NS_ :

BS_:

BU_: AWC BAP_Tester BMC_MLBevo BMS_MV BMS_NV DCDC_800V_PAG DCDC_HV DCDC_HV_02 DCDC_IHEV Gateway Gateway_PAG Ladegeraet_2 Ladegeraet_Konzern LE1 LE2 LE_MLBevo Sub_Gateway TME

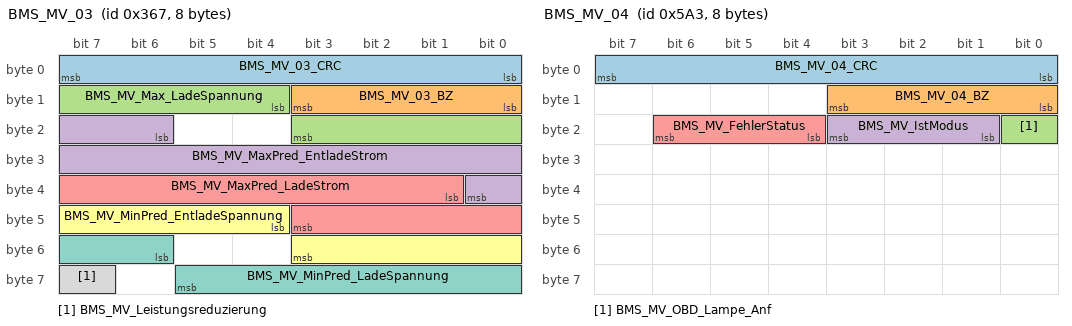
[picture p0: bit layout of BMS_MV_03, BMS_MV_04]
BO_ 871 BMS_MV_03: 8 BMS_MV
 SG_ BMS_MV_03_CRC : 0|8@1+ (1,0) [0|255] ""  Gateway,Gateway_PAG
 SG_ BMS_MV_03_BZ : 8|4@1+ (1,0) [0|15] ""  Gateway,Gateway_PAG
 SG_ BMS_MV_Max_LadeSpannung : 12|8@1+ (0.25,0) [0.00|63.25] "Unit_Volt"  Gateway,Gateway_PAG
 SG_ BMS_MV_MaxPred_EntladeStrom : 22|11@1+ (1,0) [0|2045] "Unit_Amper"  Gateway,Gateway_PAG
 SG_ BMS_MV_MaxPred_LadeStrom : 33|11@1+ (1,0) [0|2045] "Unit_Amper"  Gateway,Gateway_PAG
 SG_ BMS_MV_MinPred_EntladeSpannung : 44|8@1+ (0.25,0) [0.00|63.25] "Unit_Volt"  Gateway,Gateway_PAG
 SG_ BMS_MV_MinPred_LadeSpannung : 54|8@1+ (0.25,0) [0.00|63.25] "Unit_Volt"  Gateway,Gateway_PAG
 SG_ BMS_MV_Leistungsreduzierung : 63|1@1+ (1.0,0.0) [0.0|1] ""  Gateway,Gateway_PAG

BO_ 1443 BMS_MV_04: 8 BMS_MV
 SG_ BMS_MV_04_CRC : 0|8@1+ (1,0) [0|255] ""  Gateway,Gateway_PAG
 SG_ BMS_MV_04_BZ : 8|4@1+ (1,0) [0|15] ""  Gateway,Gateway_PAG
 SG_ BMS_MV_OBD_Lampe_Anf : 16|1@1+ (1.0,0.0) [0.0|1] ""  Gateway,Gateway_PAG
 SG_ BMS_MV_IstModus : 17|3@1+ (1.0,0.0) [0.0|7] ""  DCDC_IHEV,Gateway,Gateway_PAG
 SG_ BMS_MV_FehlerStatus : 20|3@1+ (1.0,0.0) [0.0|7] ""  Gateway,Gateway_PAG

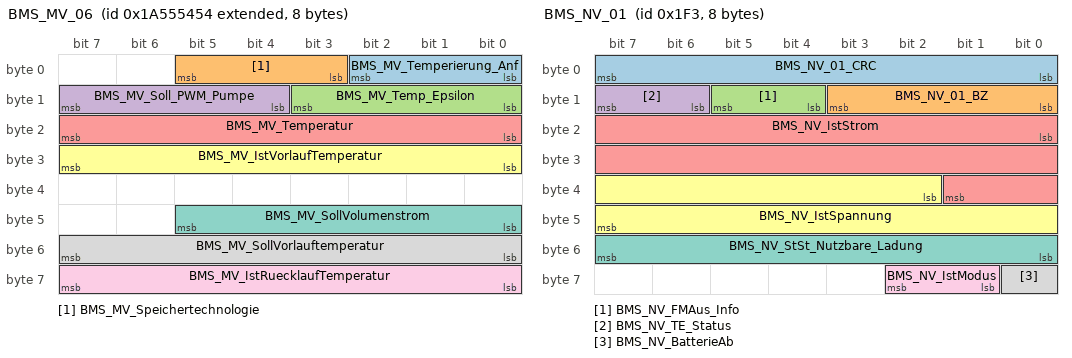
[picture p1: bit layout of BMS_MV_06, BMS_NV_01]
BO_ 2589283412 BMS_MV_06: 8 BMS_MV
 SG_ BMS_MV_Temperierung_Anf : 0|3@1+ (1.0,0.0) [0.0|7] ""  Gateway,Gateway_PAG,TME
 SG_ BMS_MV_Speichertechnologie : 3|3@1+ (1.0,0.0) [0.0|7] ""  Gateway,Gateway_PAG
 SG_ BMS_MV_Temp_Epsilon : 8|4@1+ (1,-15) [-15|0] "Unit_DegreCelsi"  Gateway,Gateway_PAG,TME
 SG_ BMS_MV_Soll_PWM_Pumpe : 12|4@1+ (10,0) [0|100] "Unit_PerCent"  Gateway,Gateway_PAG,TME
 SG_ BMS_MV_Temperatur : 16|8@1+ (0.5,-40) [-40.0|86.5] "Unit_DegreCelsi"  DCDC_IHEV,Gateway,Gateway_PAG,TME
 SG_ BMS_MV_IstVorlaufTemperatur : 24|8@1+ (0.5,-40) [-40.0|86.5] "Unit_DegreCelsi"  Gateway,Gateway_PAG,TME
 SG_ BMS_MV_SollVolumenstrom : 40|6@1+ (1,0) [0|61] ""  Gateway,Gateway_PAG,TME
 SG_ BMS_MV_SollVorlauftemperatur : 48|8@1+ (0.5,-40) [-40.0|86.5] "Unit_DegreCelsi"  Gateway,Gateway_PAG,TME
 SG_ BMS_MV_IstRuecklaufTemperatur : 56|8@1+ (0.5,-40) [-40.0|86.5] "Unit_DegreCelsi"  Gateway,Gateway_PAG,TME

BO_ 2589283608 BMS_MV_07: 8 BMS_MV
 SG_ BMS_MV_Energieinhalt : 12|11@1+ (1,0) [0|2045] "Unit_WattHour"  Gateway,Gateway_PAG
 SG_ BMS_MV_MaxEnergieinhalt : 32|11@1+ (1,0) [0|2045] "Unit_WattHour"  Gateway,Gateway_PAG

BO_ 2589283606 BMS_MV_09: 8 BMS_MV
 SG_ BMS_MV_SOC_Kaltstart : 43|11@1+ (0.05,0) [0.00|100.00] "Unit_PerCent"  Gateway,Gateway_PAG
 SG_ BMS_MV_max_Grenz_SOC : 54|5@1+ (1,70) [70|100] "Unit_PerCent"  Gateway,Gateway_PAG

BO_ 1021 BMS_MV_10: 8 BMS_MV
 SG_ BMS_MV_Pred_Entladeperformance : 50|7@1+ (1,0) [0|100] "Unit_PerCent"  Gateway,Gateway_PAG
 SG_ BMS_MV_Pred_Ladeperformance : 57|7@1+ (1,0) [0|100] "Unit_PerCent"  Gateway,Gateway_PAG

BO_ 499 BMS_NV_01: 8 BMS_NV
 SG_ BMS_NV_01_CRC : 0|8@1+ (1,0) [0|255] ""  Gateway,Gateway_PAG
 SG_ BMS_NV_01_BZ : 8|4@1+ (1,0) [0|15] ""  Gateway,Gateway_PAG
 SG_ BMS_NV_FMAus_Info : 12|2@1+ (1.0,0.0) [0.0|3] ""  Gateway,Gateway_PAG
 SG_ BMS_NV_TE_Status : 14|2@1+ (1.0,0.0) [0.0|3] ""  Gateway,Gateway_PAG
 SG_ BMS_NV_IstStrom : 16|18@1+ (0.01,-1300) [-1300.00|1300.00] "Unit_Amper"  Gateway,Gateway_PAG
 SG_ BMS_NV_IstSpannung : 34|14@1+ (0.001,4) [4.000|20.381] "Unit_Volt"  Gateway,Gateway_PAG
 SG_ BMS_NV_StSt_Nutzbare_Ladung : 48|8@1+ (50,0) [0|12650] "Unit_AmperSecon"  Gateway,Gateway_PAG
 SG_ BMS_NV_BatterieAb : 56|1@1+ (1.0,0.0) [0.0|1] ""  Gateway,Gateway_PAG
 SG_ BMS_NV_IstModus : 57|2@1+ (1.0,0.0) [0.0|3] ""  Gateway,Gateway_PAG

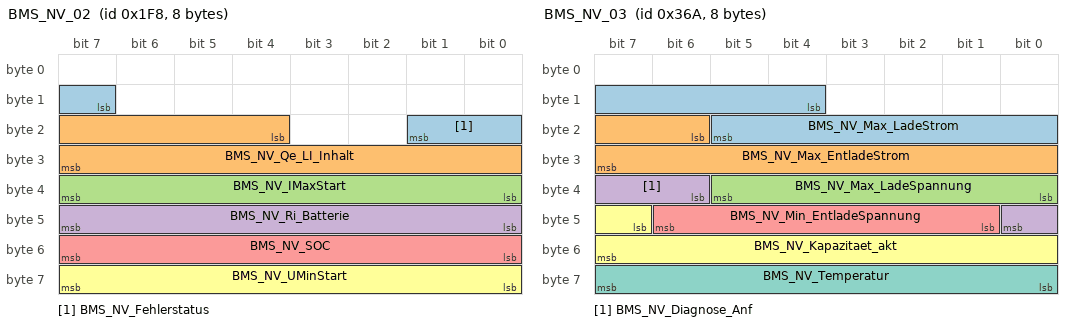
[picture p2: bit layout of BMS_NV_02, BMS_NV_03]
BO_ 504 BMS_NV_02: 8 BMS_NV
 SG_ BMS_NV_Fehlerstatus : 15|3@1+ (1.0,0.0) [0.0|7] ""  Gateway,Gateway_PAG
 SG_ BMS_NV_Qe_LI_Inhalt : 20|12@1+ (0.01,0) [0.00|40.00] "Unit_AmperHour"  Gateway,Gateway_PAG
 SG_ BMS_NV_IMaxStart : 32|8@1+ (4,1) [1|1013] "Unit_Amper"  Gateway,Gateway_PAG
 SG_ BMS_NV_Ri_Batterie : 40|8@1+ (0.2,0) [0.0|50.6] "Unit_MilliOhm"  Gateway,Gateway_PAG
 SG_ BMS_NV_SOC : 48|8@1+ (0.4,0) [0.0|100.0] "Unit_PerCent"  Gateway,Gateway_PAG
 SG_ BMS_NV_UMinStart : 56|8@1+ (0.05,2) [2.00|14.65] "Unit_Volt"  Gateway,Gateway_PAG

BO_ 874 BMS_NV_03: 8 BMS_NV
 SG_ BMS_NV_Max_LadeStrom : 12|10@1+ (1,0) [0|850] "Unit_Amper"  Gateway,Gateway_PAG
 SG_ BMS_NV_Max_EntladeStrom : 22|10@1+ (1,0) [0|850] "Unit_Amper"  Gateway,Gateway_PAG
 SG_ BMS_NV_Max_LadeSpannung : 32|6@1+ (0.1,11) [11.0|17.1] "Unit_Volt"  Gateway,Gateway_PAG
 SG_ BMS_NV_Diagnose_Anf : 38|3@1+ (1.0,0.0) [0.0|7] ""  Gateway,Gateway_PAG
 SG_ BMS_NV_Min_EntladeSpannung : 41|6@1+ (0.1,8) [8.0|14.1] "Unit_Volt"  Gateway,Gateway_PAG
 SG_ BMS_NV_Kapazitaet_akt : 47|9@1+ (0.1,0) [0.0|40.0] "Unit_AmperHour"  Gateway,Gateway_PAG
 SG_ BMS_NV_Temperatur : 56|8@1+ (1,-55) [-55|127] "Unit_DegreCelsi"  Gateway,Gateway_PAG

BO_ 2463978664 BMS_NV_04: 8 BMS_NV
 SG_ BMS_NV_Polspannung : 55|9@1+ (0.01,10.5) [10.50|15.59] "Unit_Volt"  Gateway,Gateway_PAG

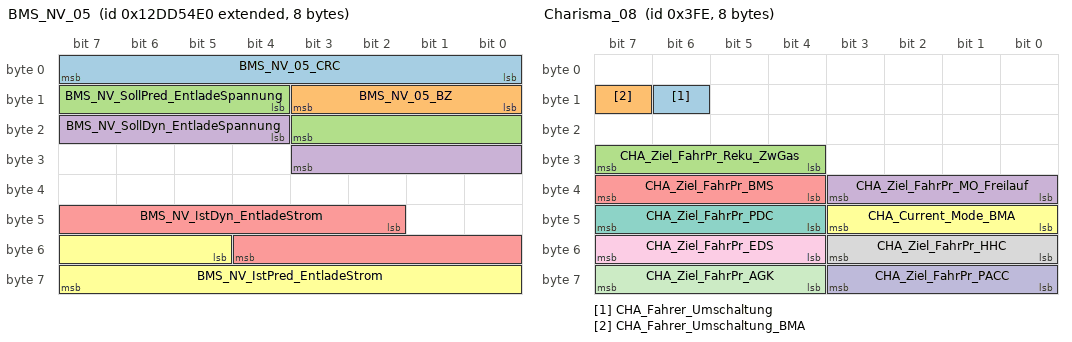
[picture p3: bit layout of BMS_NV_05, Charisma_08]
BO_ 2463978720 BMS_NV_05: 8 BMS_NV
 SG_ BMS_NV_05_CRC : 0|8@1+ (1,0) [0|255] ""  Gateway,Gateway_PAG
 SG_ BMS_NV_05_BZ : 8|4@1+ (1,0) [0|15] ""  Gateway,Gateway_PAG
 SG_ BMS_NV_SollPred_EntladeSpannung : 12|8@1+ (0.05,4) [4.00|16.65] "Unit_Volt"  Gateway,Gateway_PAG
 SG_ BMS_NV_SollDyn_EntladeSpannung : 20|8@1+ (0.05,4) [4.00|16.65] "Unit_Volt"  Gateway,Gateway_PAG
 SG_ BMS_NV_IstDyn_EntladeStrom : 42|11@1+ (1,0) [0|2045] "Unit_Amper"  Gateway,Gateway_PAG
 SG_ BMS_NV_IstPred_EntladeStrom : 53|11@1+ (1,0) [0|2045] "Unit_Amper"  Gateway,Gateway_PAG

BO_ 2617236992 CCP_BMS_CRO_01: 8 Vector__XXX
 SG_ CCP_BMS_CRO_01_Data : 0|64@1+ (1,0) [0|1] ""  BMC_MLBevo

BO_ 2617236993 CCP_BMS_DTO_01: 8 BMC_MLBevo
 SG_ CCP_BMS_DTO_01_Data : 0|64@1+ (1,0) [0|1] ""  Vector__XXX

BO_ 2617130752 CCP_DCDC_HV_02_CRO_01: 8 Vector__XXX
 SG_ CCP_DCDC_HV_02_CRO_01_Data : 0|64@1+ (1.0,0.0) [0.0|18446744073709551615] ""  DCDC_HV_02

BO_ 2617130753 CCP_DCDC_HV_02_DTO_01: 8 DCDC_HV_02
 SG_ CCP_DCDC_HV_02_DTO_01_Data : 0|64@1+ (1.0,0.0) [0.0|18446744073709551615] ""  Vector__XXX

BO_ 2617194240 CCP_Ladegeraet_2_CRO_01: 8 Vector__XXX
 SG_ CCP_Ladegeraet_2_CRO_01_Data : 0|64@1+ (1.0,0.0) [0.0|18446744073709551615] ""  Ladegeraet_2

BO_ 2617194241 CCP_Ladegeraet_2_DTO_01: 8 Ladegeraet_2
 SG_ CCP_Ladegeraet_2_DTO_01_Data : 0|64@1+ (1.0,0.0) [0.0|18446744073709551615] ""  Vector__XXX

BO_ 2617124352 CCP_Ladegeraet_CRO_01: 8 Vector__XXX
 SG_ CCP_Ladegeraet_CRO_01_Data : 0|64@1+ (1.0,0.0) [0.0|18446744073709551615] ""  Ladegeraet_Konzern

BO_ 2617124353 CCP_Ladegeraet_DTO_01: 8 Ladegeraet_Konzern
 SG_ CCP_Ladegeraet_DTO_01_Data : 0|64@1+ (1.0,0.0) [0.0|18446744073709551615] ""  Vector__XXX

BO_ 901 Charisma_01: 8 Gateway
 SG_ CHA_Ziel_FahrPr_AGA : 0|4@1+ (1.0,0.0) [0.0|15] ""  Vector__XXX
 SG_ CHA_Ziel_FahrPr_ESP : 4|4@1+ (1.0,0.0) [0.0|15] ""  Vector__XXX
 SG_ CHA_Ziel_FahrPr_Freilauf : 8|4@1+ (1.0,0.0) [0.0|15] ""  Vector__XXX
 SG_ CHA_Fahrer_Umschaltung : 14|1@1+ (1.0,0.0) [0.0|1] ""  Vector__XXX
 SG_ CHA_Fahrer_Umschaltung_BMA : 15|1@1+ (1.0,0.0) [0.0|1] ""  Vector__XXX
 SG_ CHA_Ziel_FahrPr_MO : 16|4@1+ (1.0,0.0) [0.0|15] ""  Vector__XXX
 SG_ CHA_Ziel_FahrPr_GE : 20|4@1+ (1.0,0.0) [0.0|15] ""  Vector__XXX
 SG_ CHA_Ziel_FahrPr_ALR : 24|4@1+ (1.0,0.0) [0.0|15] ""  Vector__XXX
 SG_ CHA_Ziel_FahrPr_MO_BZS : 28|4@1+ (1.0,0.0) [0.0|15] ""  TME
 SG_ CHA_Ziel_FahrPr_DR : 32|4@1+ (1.0,0.0) [0.0|15] ""  Vector__XXX
 SG_ CHA_Ziel_FahrPr_VAQ : 36|4@1+ (1.0,0.0) [0.0|15] ""  Vector__XXX
 SG_ CHA_Ziel_FahrPr_AFS : 40|4@1+ (1.0,0.0) [0.0|15] ""  Vector__XXX
 SG_ CHA_Ziel_FahrPr_PreCrash : 44|4@1+ (1.0,0.0) [0.0|15] ""  Vector__XXX
 SG_ CHA_Ziel_FahrPr_EPS : 48|4@1+ (1.0,0.0) [0.0|15] ""  Vector__XXX
 SG_ CHA_Ziel_FahrPr_ACC : 52|4@1+ (1.0,0.0) [0.0|15] ""  Vector__XXX
 SG_ CHA_Ziel_FahrPr_SAK : 56|4@1+ (1.0,0.0) [0.0|15] ""  Vector__XXX
 SG_ CHA_Ziel_FahrPr_MO_StSt : 60|4@1+ (1.0,0.0) [0.0|15] ""  Vector__XXX

BO_ 1022 Charisma_08: 8 Gateway
 SG_ CHA_Fahrer_Umschaltung : 14|1@1+ (1.0,0.0) [0.0|1] ""  Vector__XXX
 SG_ CHA_Fahrer_Umschaltung_BMA : 15|1@1+ (1.0,0.0) [0.0|1] ""  Vector__XXX
 SG_ CHA_Ziel_FahrPr_Reku_ZwGas : 28|4@1+ (1.0,0.0) [0.0|15] ""  Vector__XXX
 SG_ CHA_Ziel_FahrPr_MO_Freilauf : 32|4@1+ (1.0,0.0) [0.0|15] ""  Vector__XXX
 SG_ CHA_Ziel_FahrPr_BMS : 36|4@1+ (1.0,0.0) [0.0|15] ""  BMC_MLBevo
 SG_ CHA_Current_Mode_BMA : 40|4@1+ (1.0,0.0) [0.0|15] ""  Vector__XXX
 SG_ CHA_Ziel_FahrPr_PDC : 44|4@1+ (1.0,0.0) [0.0|15] ""  Vector__XXX
 SG_ CHA_Ziel_FahrPr_HHC : 48|4@1+ (1.0,0.0) [0.0|15] ""  Vector__XXX
 SG_ CHA_Ziel_FahrPr_EDS : 52|4@1+ (1.0,0.0) [0.0|15] ""  Vector__XXX
 SG_ CHA_Ziel_FahrPr_PACC : 56|4@1+ (1.0,0.0) [0.0|15] ""  Vector__XXX
 SG_ CHA_Ziel_FahrPr_AGK : 60|4@1+ (1.0,0.0) [0.0|15] ""  Vector__XXX

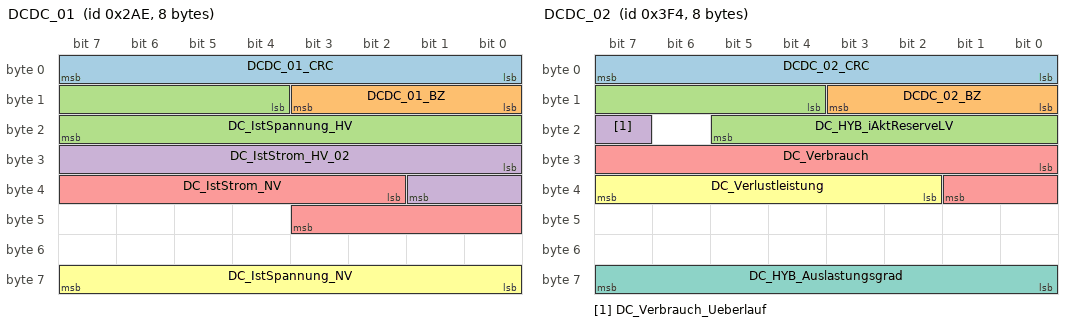
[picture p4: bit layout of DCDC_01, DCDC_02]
BO_ 686 DCDC_01: 8 DCDC_800V_PAG
 SG_ DCDC_01_CRC : 0|8@1+ (1,0) [0|255] ""  Gateway,Gateway_PAG
 SG_ DCDC_01_BZ : 8|4@1+ (1,0) [0|15] ""  Gateway,Gateway_PAG
 SG_ DC_IstSpannung_HV : 12|12@1+ (0.25,0) [0.00|1023.25] "Unit_Volt"  BMC_MLBevo,DCDC_HV_02,Gateway,Gateway_PAG,TME
 SG_ DC_IstStrom_HV_02 : 24|10@1+ (0.4,-204) [-204.0|204.0] "Unit_Amper"  DCDC_HV_02,Gateway,Gateway_PAG,Ladegeraet_Konzern,TME
 SG_ DC_IstStrom_NV : 34|10@1+ (1,-511) [-511|510] "Unit_Amper"  Gateway,Gateway_PAG
 SG_ DC_IstSpannung_NV : 56|8@1+ (0.1,0) [0.0|25.3] "Unit_Volt"  AWC,Gateway,Gateway_PAG,Ladegeraet_2,Ladegeraet_Konzern

BO_ 1012 DCDC_02: 8 DCDC_800V_PAG
 SG_ DCDC_02_CRC : 0|8@1+ (1,0) [0|255] ""  Gateway,Gateway_PAG
 SG_ DCDC_02_BZ : 8|4@1+ (1,0) [0|15] ""  Gateway,Gateway_PAG
 SG_ DC_HYB_iAktReserveLV : 12|10@1+ (1,-511) [-511|510] "Unit_Amper"  Gateway,Gateway_PAG
 SG_ DC_Verbrauch_Ueberlauf : 23|1@1+ (1.0,0.0) [0.0|1] ""  Gateway,Gateway_PAG
 SG_ DC_Verbrauch : 24|10@1+ (1,0) [0|1023] "Unit_WattSecond"  Gateway,Gateway_PAG
 SG_ DC_Verlustleistung : 34|6@1+ (5,0) [0|305] "Unit_Watt"  Gateway,Gateway_PAG,TME
 SG_ DC_HYB_Auslastungsgrad : 56|8@1+ (0.4,0) [0.0|100.0] "Unit_PerCent"  Gateway,Gateway_PAG,TME

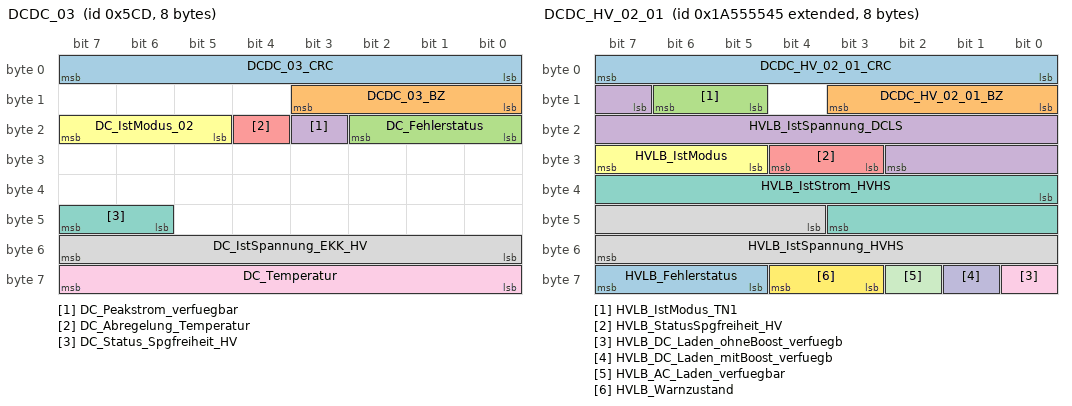
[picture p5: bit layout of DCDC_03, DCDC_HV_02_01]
BO_ 1485 DCDC_03: 8 DCDC_800V_PAG
 SG_ DCDC_03_CRC : 0|8@1+ (1,0) [0|255] ""  Gateway,Gateway_PAG
 SG_ DCDC_03_BZ : 8|4@1+ (1,0) [0|15] ""  Gateway,Gateway_PAG
 SG_ DC_Fehlerstatus : 16|3@1+ (1.0,0.0) [0.0|7] ""  Gateway,Gateway_PAG
 SG_ DC_Peakstrom_verfuegbar : 19|1@1+ (1.0,0.0) [0.0|1] ""  Gateway,Gateway_PAG
 SG_ DC_Abregelung_Temperatur : 20|1@1+ (1.0,0.0) [0.0|1] ""  TME
 SG_ DC_IstModus_02 : 21|3@1+ (1.0,0.0) [0.0|7] ""  DCDC_HV_02,Gateway,Gateway_PAG,Ladegeraet_Konzern,TME
 SG_ DC_Status_Spgfreiheit_HV : 46|2@1+ (1.0,0.0) [0.0|3] ""  Gateway
 SG_ DC_IstSpannung_EKK_HV : 48|8@1+ (2,0) [0|508] "Unit_Volt"  Gateway
 SG_ DC_Temperatur : 56|8@1+ (1,-40) [-40|213] "Unit_DegreCelsi"  Gateway,Gateway_PAG,TME

BO_ 2589283653 DCDC_HV_02_01: 8 DCDC_HV_02
 SG_ DCDC_HV_02_01_CRC : 0|8@1+ (1,0) [0|255] ""  Gateway,Gateway_PAG,Ladegeraet_Konzern
 SG_ DCDC_HV_02_01_BZ : 8|4@1+ (1,0) [0|15] ""  Gateway,Gateway_PAG,Ladegeraet_Konzern
 SG_ HVLB_IstModus_TN1 : 13|2@1+ (1.0,0.0) [0.0|3] ""  Gateway,Gateway_PAG
 SG_ HVLB_IstSpannung_DCLS : 15|12@1+ (0.25,0) [0.00|1023.25] "Unit_Volt"  Ladegeraet_Konzern
 SG_ HVLB_StatusSpgfreiheit_HV : 27|2@1+ (1.0,0.0) [0.0|3] ""  Gateway,Gateway_PAG
 SG_ HVLB_IstModus : 29|3@1+ (1.0,0.0) [0.0|7] ""  Ladegeraet_Konzern,TME
 SG_ HVLB_IstStrom_HVHS : 32|12@1+ (0.25,-512) [-512.00|511.25] "Unit_Amper"  Ladegeraet_Konzern
 SG_ HVLB_IstSpannung_HVHS : 44|12@1+ (0.25,0) [0.00|1023.25] "Unit_Volt"  Gateway,Gateway_PAG,Ladegeraet_Konzern
 SG_ HVLB_DC_Laden_ohneBoost_verfuegb : 56|1@1+ (1.0,0.0) [0.0|1] ""  Ladegeraet_Konzern
 SG_ HVLB_DC_Laden_mitBoost_verfuegb : 57|1@1+ (1.0,0.0) [0.0|1] ""  Ladegeraet_Konzern
 SG_ HVLB_AC_Laden_verfuegbar : 58|1@1+ (1.0,0.0) [0.0|1] ""  Ladegeraet_Konzern
 SG_ HVLB_Warnzustand : 59|2@1+ (1.0,0.0) [0.0|3] ""  Ladegeraet_Konzern
 SG_ HVLB_Fehlerstatus : 61|3@1+ (1.0,0.0) [0.0|7] ""  Gateway,Gateway_PAG,Ladegeraet_Konzern

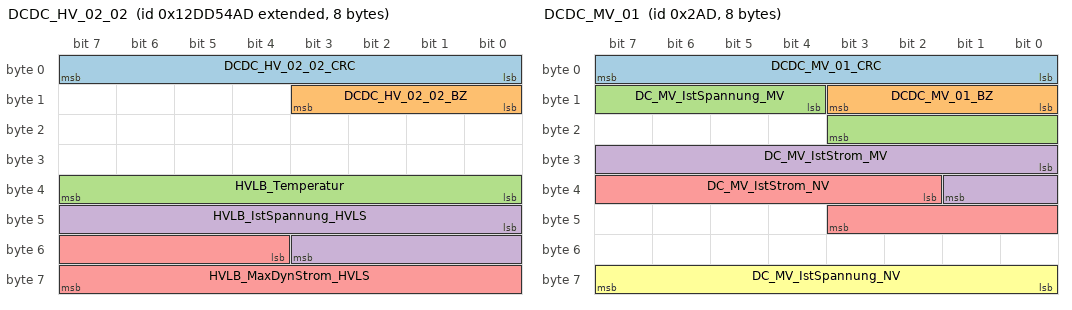
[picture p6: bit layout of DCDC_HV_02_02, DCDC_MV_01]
BO_ 2463978669 DCDC_HV_02_02: 8 DCDC_HV_02
 SG_ DCDC_HV_02_02_CRC : 0|8@1+ (1,0) [0|255] ""  Ladegeraet_Konzern
 SG_ DCDC_HV_02_02_BZ : 8|4@1+ (1,0) [0|15] ""  Ladegeraet_Konzern
 SG_ HVLB_Temperatur : 32|8@1+ (1,-40) [-40|213] "Unit_DegreCelsi"  TME
 SG_ HVLB_IstSpannung_HVLS : 40|12@1+ (0.25,0) [0.00|1023.25] "Unit_Volt"  Ladegeraet_Konzern
 SG_ HVLB_MaxDynStrom_HVLS : 52|12@1+ (0.25,-512) [-512.00|511.25] "Unit_Amper"  Ladegeraet_Konzern

BO_ 2589283662 DCDC_HV_02_03: 8 DCDC_HV_02
 SG_ HVLB_PlanAntw_Verlustleistung : 48|12@1+ (50,0) [0|204650] "Unit_Watt"  Ladegeraet_Konzern,TME
 SG_ HVLB_PlanAntw_Zaehler : 60|4@1+ (1,0) [0|13] "Unit_None"  Ladegeraet_Konzern,TME

BO_ 685 DCDC_MV_01: 8 DCDC_800V_PAG
 SG_ DCDC_MV_01_CRC : 0|8@1+ (1,0) [0|255] ""  Gateway,Gateway_PAG
 SG_ DCDC_MV_01_BZ : 8|4@1+ (1,0) [0|15] ""  Gateway,Gateway_PAG
 SG_ DC_MV_IstSpannung_MV : 12|8@1+ (0.25,0) [0.00|63.25] "Unit_Volt"  Gateway,Gateway_PAG
 SG_ DC_MV_IstStrom_MV : 24|10@1+ (0.4,-204) [-204.0|204.0] "Unit_Amper"  Gateway,Gateway_PAG
 SG_ DC_MV_IstStrom_NV : 34|10@1+ (1,-511) [-511|510] "Unit_Amper"  Gateway,Gateway_PAG
 SG_ DC_MV_IstSpannung_NV : 56|8@1+ (0.1,0) [0.0|25.3] "Unit_Volt"  Gateway,Gateway_PAG

BO_ 1018 DCDC_MV_02: 8 DCDC_800V_PAG
 SG_ DCDC_MV_02_CRC : 0|8@1+ (1,0) [0|255] ""  Gateway,Gateway_PAG
 SG_ DCDC_MV_02_BZ : 8|4@1+ (1,0) [0|15] ""  Gateway,Gateway_PAG
 SG_ DC_MV_akt_Stromreserve_NV : 12|10@1+ (1,-511) [-511|510] "Unit_Amper"  Gateway,Gateway_PAG
 SG_ DC_MV_MaxStrom_MV : 50|6@1+ (2.5,-152.5) [-152.5|0.0] "Unit_Amper"  Gateway,Gateway_PAG
 SG_ DC_MV_Auslastungsgrad : 56|8@1+ (0.4,0) [0.0|100.0] "Unit_PerCent"  Gateway,Gateway_PAG

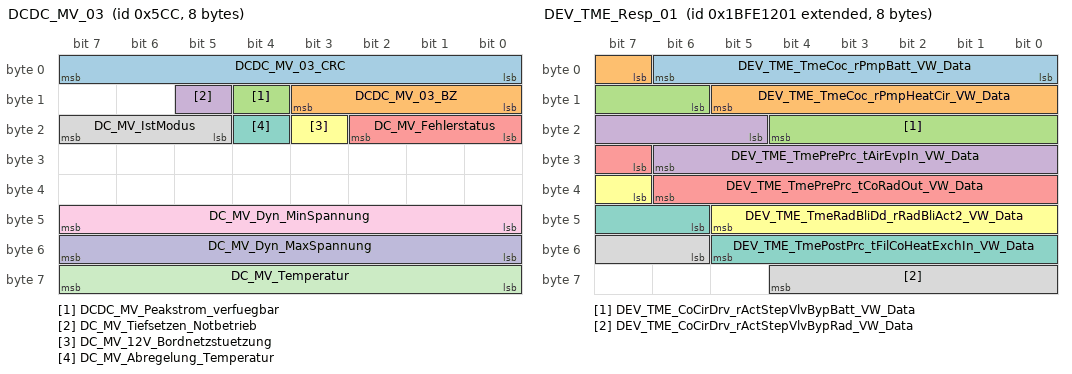
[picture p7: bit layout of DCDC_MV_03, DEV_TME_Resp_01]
BO_ 1484 DCDC_MV_03: 8 DCDC_800V_PAG
 SG_ DCDC_MV_03_CRC : 0|8@1+ (1,0) [0|255] ""  Gateway,Gateway_PAG
 SG_ DCDC_MV_03_BZ : 8|4@1+ (1,0) [0|15] ""  Gateway,Gateway_PAG
 SG_ DCDC_MV_Peakstrom_verfuegbar : 12|1@1+ (1.0,0.0) [0.0|1] ""  Gateway,Gateway_PAG
 SG_ DC_MV_Tiefsetzen_Notbetrieb : 13|1@1+ (1.0,0.0) [0.0|1] ""  Gateway,Gateway_PAG
 SG_ DC_MV_Fehlerstatus : 16|3@1+ (1.0,0.0) [0.0|7] ""  Gateway,Gateway_PAG
 SG_ DC_MV_12V_Bordnetzstuetzung : 19|1@1+ (1.0,0.0) [0.0|1] ""  Gateway,Gateway_PAG
 SG_ DC_MV_Abregelung_Temperatur : 20|1@1+ (1.0,0.0) [0.0|1] ""  TME
 SG_ DC_MV_IstModus : 21|3@1+ (1.0,0.0) [0.0|7] ""  Gateway,Gateway_PAG
 SG_ DC_MV_Dyn_MinSpannung : 40|8@1+ (0.25,0) [0.00|63.25] "Unit_Volt"  Gateway
 SG_ DC_MV_Dyn_MaxSpannung : 48|8@1+ (0.25,0) [0.00|63.25] "Unit_Volt"  Gateway
 SG_ DC_MV_Temperatur : 56|8@1+ (1,-40) [-40|213] "Unit_DegreCelsi"  TME

BO_ 2617015040 DEV_AWC_Resp_00: 8 AWC
 SG_ DEV_AWC_Resp_00_Data : 0|64@1+ (1.0,0.0) [0.0|18446744073709551615] ""  Vector__XXX

BO_ 2617015295 DEV_AWC_Resp_FF: 8 AWC
 SG_ DEV_AWC_Resp_FF_Data : 0|64@1+ (1.0,0.0) [0.0|18446744073709551615] ""  Vector__XXX

BO_ 2617078528 DEV_BattRegelung_Req_00: 8 Vector__XXX
 SG_ DEV_BattRegelung_Req_00_Data : 0|64@1+ (1.0,0.0) [0.0|18446744073709551615] ""  BMS_NV

BO_ 2617078783 DEV_BattRegelung_Resp_FF: 8 BMS_NV
 SG_ DEV_BattRegelung_Resp_FF_Data : 0|64@1+ (1.0,0.0) [0.0|18446744073709551615] ""  Vector__XXX

BO_ 2617041664 DEV_BMS_MV_Resp_00: 8 BMS_MV
 SG_ DEV_BMS_MV_Resp_00_Data : 0|64@1+ (1.0,0.0) [0.0|18446744073709551615] ""  Vector__XXX

BO_ 2617041919 DEV_BMS_MV_Resp_FF: 8 BMS_MV
 SG_ DEV_BMS_MV_Resp_FF_Data : 0|64@1+ (1.0,0.0) [0.0|18446744073709551615] ""  Vector__XXX

BO_ 2617235968 DEV_BMS_Resp_00: 8 BMC_MLBevo
 SG_ DEV_BMS_Resp_00_Data : 0|64@1+ (1.0,0.0) [0.0|18446744073709551615] ""  Vector__XXX

BO_ 2617236223 DEV_BMS_Resp_FF: 8 BMC_MLBevo
 SG_ DEV_BMS_Resp_FF_Data : 0|64@1+ (1.0,0.0) [0.0|18446744073709551615] ""  Vector__XXX

BO_ 2617129728 DEV_DCDC_HV_02_Req_01: 8 Vector__XXX
 SG_ DEV_DCDC_HV_02_Req_01_Data : 0|64@1+ (1.0,0.0) [0.0|18446744073709551615] ""  DCDC_HV_02

BO_ 2617129729 DEV_DCDC_HV_02_Resp_01: 8 DCDC_HV_02
 SG_ DEV_DCDC_HV_02_Resp_01_Data : 0|64@1+ (1.0,0.0) [0.0|18446744073709551615] ""  Vector__XXX

BO_ 2617129983 DEV_DCDC_HV_02_Resp_FF: 8 DCDC_HV_02
 SG_ DEV_DCDC_HV_02_Resp_FF_Data : 0|64@1+ (1.0,0.0) [0.0|18446744073709551615] ""  Vector__XXX

BO_ 2617096960 DEV_DCDC_HV_Resp_00: 8 DCDC_800V_PAG
 SG_ DEV_DCDC_HV_Resp_00_Data : 0|64@1+ (1.0,0.0) [0.0|18446744073709551615] ""  Vector__XXX

BO_ 2617097215 DEV_DCDC_HV_Resp_FF: 8 DCDC_800V_PAG
 SG_ DEV_DCDC_HV_Resp_FF_Data : 0|64@1+ (1.0,0.0) [0.0|18446744073709551615] ""  Vector__XXX

BO_ 2617117184 DEV_DCDC_Resp_00: 8 DCDC_IHEV
 SG_ DEV_DCDC_Resp_00_Data : 0|64@1+ (1.0,0.0) [0.0|18446744073709551615] ""  Vector__XXX

BO_ 2617117439 DEV_DCDC_Resp_FF: 8 DCDC_IHEV
 SG_ DEV_DCDC_Resp_FF_Data : 0|64@1+ (1.0,0.0) [0.0|18446744073709551615] ""  Vector__XXX

BO_ 2617193216 DEV_Ladegeraet_2_Req_01: 8 Vector__XXX
 SG_ DEV_Ladegeraet_2_Req_01_Data : 0|64@1+ (1.0,0.0) [0.0|18446744073709551615] ""  Ladegeraet_2

BO_ 2617193217 DEV_Ladegeraet_2_Resp_01: 8 Ladegeraet_2
 SG_ DEV_Ladegeraet_2_Resp_01_Data : 0|64@1+ (1.0,0.0) [0.0|18446744073709551615] ""  Vector__XXX

BO_ 2617193471 DEV_Ladegeraet_2_Resp_FF: 8 Ladegeraet_2
 SG_ DEV_Ladegeraet_2_Resp_FF_Data : 0|64@1+ (1.0,0.0) [0.0|18446744073709551615] ""  Vector__XXX

BO_ 2617123328 DEV_Ladegeraet_Req_01: 8 Vector__XXX
 SG_ DEV_Ladegeraet_Req_01_Data : 0|64@1+ (1.0,0.0) [0.0|18446744073709551615] ""  Ladegeraet_Konzern

BO_ 2617123329 DEV_Ladegeraet_Resp_01: 8 Ladegeraet_Konzern
 SG_ DEV_Ladegeraet_Resp_01_Data : 0|64@1+ (1.0,0.0) [0.0|18446744073709551615] ""  Vector__XXX

BO_ 2617123583 DEV_Ladegeraet_Resp_FF: 8 Ladegeraet_Konzern
 SG_ DEV_Ladegeraet_Resp_FF_Data : 0|64@1+ (1.0,0.0) [0.0|18446744073709551615] ""  Vector__XXX

BO_ 2617238016 DEV_LEH_01_Resp_00: 8 DCDC_HV
 SG_ DEV_LEH_01_Resp_00_Data : 0|64@1+ (1.0,0.0) [0.0|18446744073709551615] ""  Vector__XXX

BO_ 2617238271 DEV_LEH_01_Resp_FF: 8 DCDC_HV
 SG_ DEV_LEH_01_Resp_FF_Data : 0|64@1+ (1.0,0.0) [0.0|18446744073709551615] ""  Vector__XXX

BO_ 2617119232 DEV_TME_Resp_00: 8 TME
 SG_ DEV_TME_Resp_00_Data : 0|64@1+ (1.0,0.0) [0.0|18446744073709551615] ""  Vector__XXX

BO_ 2617119233 DEV_TME_Resp_01: 8 TME
 SG_ DEV_TME_TmeCoc_rPmpBatt_VW_Data : 0|7@1+ (1,0) [0|100] "" Vector__XXX
 SG_ DEV_TME_TmeCoc_rPmpHeatCir_VW_Data : 7|7@1+ (1,0) [0|100] "" Vector__XXX
 SG_ DEV_TME_CoCirDrv_rActStepVlvBypBatt_VW_Data : 14|7@1+ (1,0) [0|100] "" Vector__XXX
 SG_ DEV_TME_TmePrePrc_tAirEvpIn_VW_Data : 21|10@1+ (0.1,-20) [-20|70] "" Vector__XXX
 SG_ DEV_TME_TmePrePrc_tCoRadOut_VW_Data : 31|8@1+ (0.8,-40) [-40|159] "" Vector__XXX
 SG_ DEV_TME_TmeRadBliDd_rRadBliAct2_VW_Data : 39|7@1+ (1,0) [0|127] "" Vector__XXX
 SG_ DEV_TME_TmePostPrc_tFilCoHeatExchIn_VW_Data : 46|8@1+ (0.8,-45) [-45|159] "" Vector__XXX
 SG_ DEV_TME_CoCirDrv_rActStepVlvBypRad_VW_Data : 54|7@1+ (1,0) [0|100] "" Vector__XXX

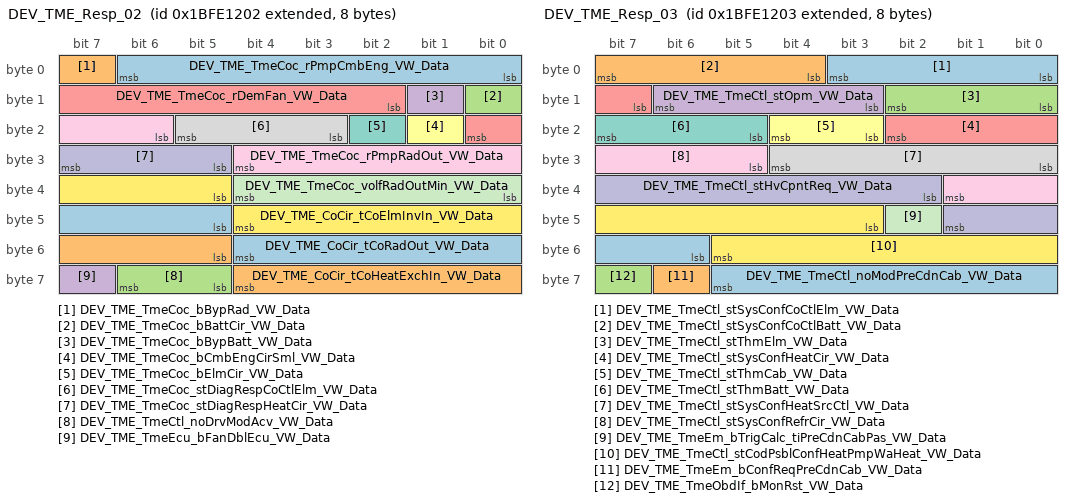
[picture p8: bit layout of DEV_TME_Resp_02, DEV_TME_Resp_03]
BO_ 2617119234 DEV_TME_Resp_02: 8 TME
 SG_ DEV_TME_TmeCoc_rPmpCmbEng_VW_Data : 0|7@1+ (1,0) [0|100] "" Vector__XXX
 SG_ DEV_TME_TmeCoc_bBypRad_VW_Data : 7|1@1+ (1,0) [0|1] "" Vector__XXX
 SG_ DEV_TME_TmeCoc_bBattCir_VW_Data : 8|1@1+ (1,0) [0|1] "" Vector__XXX
 SG_ DEV_TME_TmeCoc_bBypBatt_VW_Data : 9|1@1+ (1,0) [0|1] "" Vector__XXX
 SG_ DEV_TME_TmeCoc_rDemFan_VW_Data : 10|7@1+ (1,0) [0|100] "" Vector__XXX
 SG_ DEV_TME_TmeCoc_bCmbEngCirSml_VW_Data : 17|1@1+ (1,0) [0|1] "" Vector__XXX
 SG_ DEV_TME_TmeCoc_bElmCir_VW_Data : 18|1@1+ (1,0) [0|1] "" Vector__XXX
 SG_ DEV_TME_TmeCoc_stDiagRespCoCtlElm_VW_Data : 19|3@1+ (1,0) [0|5] "" Vector__XXX
 SG_ DEV_TME_TmeCoc_rPmpRadOut_VW_Data : 22|7@1+ (1,0) [0|100] "" Vector__XXX
 SG_ DEV_TME_TmeCoc_stDiagRespHeatCir_VW_Data : 29|3@1+ (1,0) [0|5] "" Vector__XXX
 SG_ DEV_TME_TmeCoc_volfRadOutMin_VW_Data : 32|5@1+ (0.5,0) [0|15.5] "" Vector__XXX
 SG_ DEV_TME_CoCir_tCoElmInvIn_VW_Data : 37|8@1+ (0.8,-45) [-45|159] "" Vector__XXX
 SG_ DEV_TME_CoCir_tCoRadOut_VW_Data : 45|8@1+ (0.8,-45) [-45|159] "" Vector__XXX
 SG_ DEV_TME_CoCir_tCoHeatExchIn_VW_Data : 53|8@1+ (0.8,-45) [-45|159] "" Vector__XXX
 SG_ DEV_TME_TmeCtl_noDrvModAcv_VW_Data : 61|2@1+ (1,0) [0|3] "" Vector__XXX
 SG_ DEV_TME_TmeEcu_bFanDblEcu_VW_Data : 63|1@1+ (1,0) [0|1] "" Vector__XXX

BO_ 2617119235 DEV_TME_Resp_03: 8 TME
 SG_ DEV_TME_TmeCtl_stSysConfCoCtlElm_VW_Data : 0|4@1+ (1,0) [0|15] "" Vector__XXX
 SG_ DEV_TME_TmeCtl_stSysConfCoCtlBatt_VW_Data : 4|4@1+ (1,0) [0|15] "" Vector__XXX
 SG_ DEV_TME_TmeCtl_stThmElm_VW_Data : 8|3@1+ (1,0) [0|7] "" Vector__XXX
 SG_ DEV_TME_TmeCtl_stOpm_VW_Data : 11|4@1+ (1,0) [0|15] "" Vector__XXX
 SG_ DEV_TME_TmeCtl_stSysConfHeatCir_VW_Data : 15|4@1+ (1,0) [0|15] "" Vector__XXX
 SG_ DEV_TME_TmeCtl_stThmCab_VW_Data : 19|2@1+ (1,-1) [-1|2] "" Vector__XXX
 SG_ DEV_TME_TmeCtl_stThmBatt_VW_Data : 21|3@1+ (1,-3) [-3|4] "" Vector__XXX
 SG_ DEV_TME_TmeCtl_stSysConfHeatSrcCtl_VW_Data : 24|5@1+ (1,0) [0|31] "" Vector__XXX
 SG_ DEV_TME_TmeCtl_stSysConfRefrCir_VW_Data : 29|5@1+ (1,0) [0|31] "" Vector__XXX
 SG_ DEV_TME_TmeCtl_stHvCpntReq_VW_Data : 34|8@1+ (1,0) [0|255] "" Vector__XXX
 SG_ DEV_TME_TmeEm_bTrigCalc_tiPreCdnCabPas_VW_Data : 42|1@1+ (1,0) [0|1] "" Vector__XXX
 SG_ DEV_TME_TmeCtl_stCodPsblConfHeatPmpWaHeat_VW_Data : 43|11@1+ (1,0) [0|2047] "" Vector__XXX
 SG_ DEV_TME_TmeCtl_noModPreCdnCab_VW_Data : 54|8@1+ (1,0) [0|255] "" Vector__XXX
 SG_ DEV_TME_TmeEm_bConfReqPreCdnCab_VW_Data : 62|1@1+ (1,0) [0|1] "" Vector__XXX
 SG_ DEV_TME_TmeObdIf_bMonRst_VW_Data : 63|1@1+ (1,0) [0|1] "" Vector__XXX

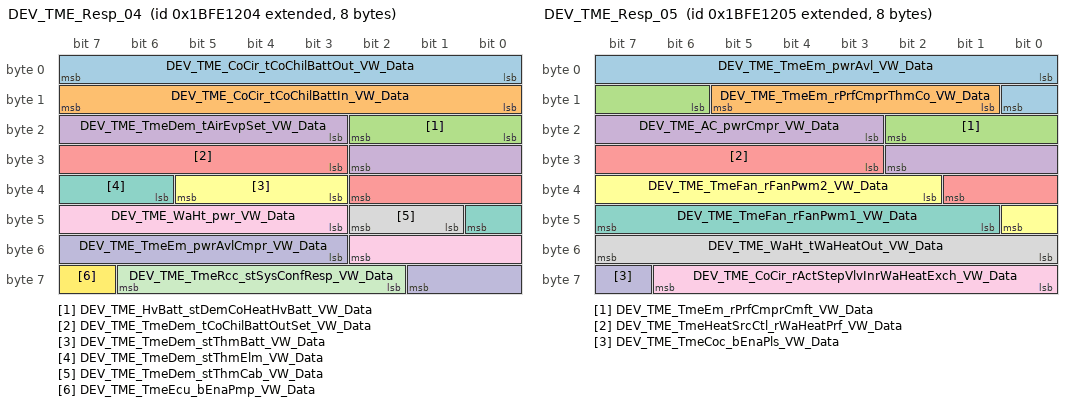
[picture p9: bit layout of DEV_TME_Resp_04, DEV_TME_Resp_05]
BO_ 2617119236 DEV_TME_Resp_04: 8 TME
 SG_ DEV_TME_CoCir_tCoChilBattOut_VW_Data : 0|8@1+ (0.8,-45) [-45|159] "" Vector__XXX
 SG_ DEV_TME_CoCir_tCoChilBattIn_VW_Data : 8|8@1+ (0.8,-45) [-45|159] "" Vector__XXX
 SG_ DEV_TME_HvBatt_stDemCoHeatHvBatt_VW_Data : 16|3@1+ (1,0) [0|7] "" Vector__XXX
 SG_ DEV_TME_TmeDem_tAirEvpSet_VW_Data : 19|8@1+ (0.8,-45) [-45|159] "" Vector__XXX
 SG_ DEV_TME_TmeDem_tCoChilBattOutSet_VW_Data : 27|8@1+ (0.8,-45) [-45|159] "" Vector__XXX
 SG_ DEV_TME_TmeDem_stThmBatt_VW_Data : 35|3@1+ (1,0) [0|4] "" Vector__XXX
 SG_ DEV_TME_TmeDem_stThmElm_VW_Data : 38|3@1+ (1,0) [0|7] "" Vector__XXX
 SG_ DEV_TME_TmeDem_stThmCab_VW_Data : 41|2@1+ (1,-1) [-1|2] "" Vector__XXX
 SG_ DEV_TME_WaHt_pwr_VW_Data : 43|8@1+ (50,0) [0|12750] "" Vector__XXX
 SG_ DEV_TME_TmeEm_pwrAvlCmpr_VW_Data : 51|7@1+ (64,0) [0|8000] "" Vector__XXX
 SG_ DEV_TME_TmeRcc_stSysConfResp_VW_Data : 58|5@1+ (1,0) [0|31] "" Vector__XXX
 SG_ DEV_TME_TmeEcu_bEnaPmp_VW_Data : 63|1@1+ (1,0) [0|1] "" Vector__XXX

BO_ 2617119237 DEV_TME_Resp_05: 8 TME
 SG_ DEV_TME_TmeEm_pwrAvl_VW_Data : 0|9@1+ (32,0) [0|16352] "" Vector__XXX
 SG_ DEV_TME_TmeEm_rPrfCmprThmCo_VW_Data : 9|5@1+ (0.05,0) [0|1] "" Vector__XXX
 SG_ DEV_TME_TmeEm_rPrfCmprCmft_VW_Data : 14|5@1+ (0.05,0) [0|1] "" Vector__XXX
 SG_ DEV_TME_AC_pwrCmpr_VW_Data : 19|8@1+ (32,0) [0|6000] "" Vector__XXX
 SG_ DEV_TME_TmeHeatSrcCtl_rWaHeatPrf_VW_Data : 27|7@1+ (1,0) [0|100] "" Vector__XXX
 SG_ DEV_TME_TmeFan_rFanPwm2_VW_Data : 34|7@1+ (1,0) [0|100] "" Vector__XXX
 SG_ DEV_TME_TmeFan_rFanPwm1_VW_Data : 41|7@1+ (1,0) [0|100] "" Vector__XXX
 SG_ DEV_TME_WaHt_tWaHeatOut_VW_Data : 48|8@1+ (0.8,-45) [-45|159] "" Vector__XXX
 SG_ DEV_TME_CoCir_rActStepVlvInrWaHeatExch_VW_Data : 56|7@1+ (1,0) [0|100] "" Vector__XXX
 SG_ DEV_TME_TmeCoc_bEnaPls_VW_Data : 63|1@1+ (1,0) [0|1] "" Vector__XXX

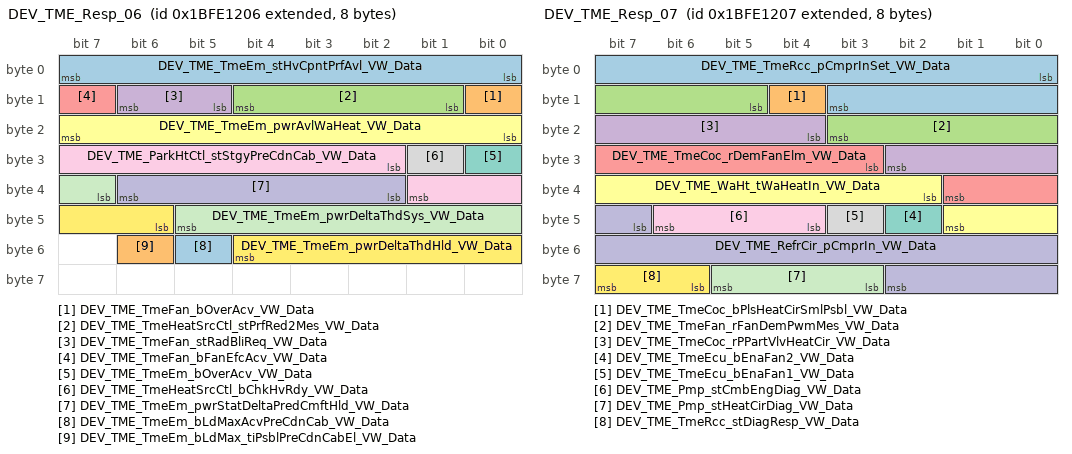
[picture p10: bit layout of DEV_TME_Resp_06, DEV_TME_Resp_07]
BO_ 2617119238 DEV_TME_Resp_06: 8 TME
 SG_ DEV_TME_TmeEm_stHvCpntPrfAvl_VW_Data : 0|8@1+ (1,0) [0|255] "" Vector__XXX
 SG_ DEV_TME_TmeFan_bOverAcv_VW_Data : 8|1@1+ (1,0) [0|1] "" Vector__XXX
 SG_ DEV_TME_TmeHeatSrcCtl_stPrfRed2Mes_VW_Data : 9|4@1+ (1,0) [0|15] "" Vector__XXX
 SG_ DEV_TME_TmeFan_stRadBliReq_VW_Data : 13|2@1+ (1,0) [0|3] "" Vector__XXX
 SG_ DEV_TME_TmeFan_bFanEfcAcv_VW_Data : 15|1@1+ (1,0) [0|1] "" Vector__XXX
 SG_ DEV_TME_TmeEm_pwrAvlWaHeat_VW_Data : 16|8@1+ (32,0) [0|8160] "" Vector__XXX
 SG_ DEV_TME_TmeEm_bOverAcv_VW_Data : 24|1@1+ (1,0) [0|1] "" Vector__XXX
 SG_ DEV_TME_TmeHeatSrcCtl_bChkHvRdy_VW_Data : 25|1@1+ (1,0) [0|1] "" Vector__XXX
 SG_ DEV_TME_ParkHtCtl_stStgyPreCdnCab_VW_Data : 26|8@1+ (1,0) [0|255] "" Vector__XXX
 SG_ DEV_TME_TmeEm_pwrStatDeltaPredCmftHld_VW_Data : 34|5@1+ (200,0) [0|6000] "" Vector__XXX
 SG_ DEV_TME_TmeEm_pwrDeltaThdSys_VW_Data : 39|7@1+ (100,0) [0|12700] "" Vector__XXX
 SG_ DEV_TME_TmeEm_pwrDeltaThdHld_VW_Data : 46|7@1+ (100,0) [0|12700] "" Vector__XXX
 SG_ DEV_TME_TmeEm_bLdMaxAcvPreCdnCab_VW_Data : 53|1@1+ (1,0) [0|1] "" Vector__XXX
 SG_ DEV_TME_TmeEm_bLdMax_tiPsblPreCdnCabEl_VW_Data : 54|1@1+ (1,0) [0|1] "" Vector__XXX

BO_ 2617119239 DEV_TME_Resp_07: 8 TME
 SG_ DEV_TME_TmeRcc_pCmprInSet_VW_Data : 0|12@1+ (0.015625,0) [0|35] "" Vector__XXX
 SG_ DEV_TME_TmeCoc_bPlsHeatCirSmlPsbl_VW_Data : 12|1@1+ (1,0) [0|1] "" Vector__XXX
 SG_ DEV_TME_TmeFan_rFanDemPwmMes_VW_Data : 13|7@1+ (1,0) [0|100] "" Vector__XXX
 SG_ DEV_TME_TmeCoc_rPPartVlvHeatCir_VW_Data : 20|7@1+ (1,0) [0|100] "" Vector__XXX
 SG_ DEV_TME_TmeCoc_rDemFanElm_VW_Data : 27|7@1+ (1,0) [0|100] "" Vector__XXX
 SG_ DEV_TME_WaHt_tWaHeatIn_VW_Data : 34|8@1+ (0.8,-45) [-45|159] "" Vector__XXX
 SG_ DEV_TME_TmeEcu_bEnaFan2_VW_Data : 42|1@1+ (1,0) [0|1] "" Vector__XXX
 SG_ DEV_TME_TmeEcu_bEnaFan1_VW_Data : 43|1@1+ (1,0) [0|1] "" Vector__XXX
 SG_ DEV_TME_Pmp_stCmbEngDiag_VW_Data : 44|3@1+ (1,0) [0|7] "" Vector__XXX
 SG_ DEV_TME_RefrCir_pCmprIn_VW_Data : 47|12@1+ (0.015625,0) [0|63.3] "" Vector__XXX
 SG_ DEV_TME_Pmp_stHeatCirDiag_VW_Data : 59|3@1+ (1,0) [0|7] "" Vector__XXX
 SG_ DEV_TME_TmeRcc_stDiagResp_VW_Data : 62|2@1+ (1,0) [0|3] "" Vector__XXX

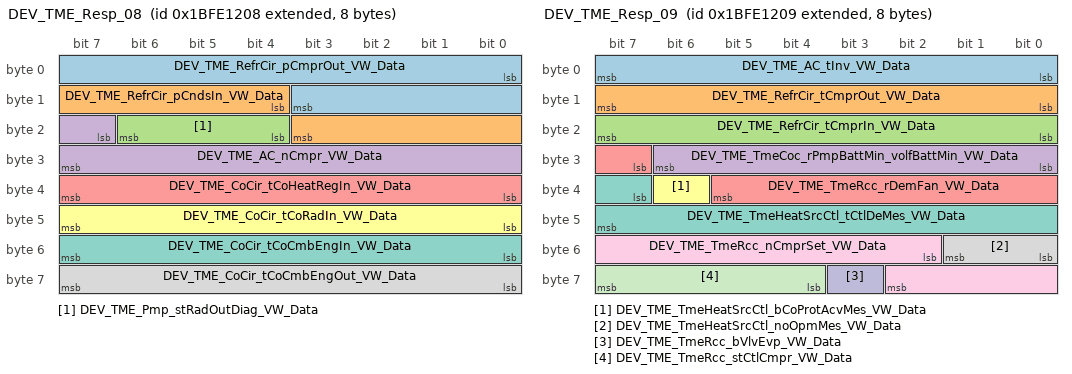
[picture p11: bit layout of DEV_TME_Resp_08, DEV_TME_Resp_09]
BO_ 2617119240 DEV_TME_Resp_08: 8 TME
 SG_ DEV_TME_RefrCir_pCmprOut_VW_Data : 0|12@1+ (0.015625,0) [0|63.3] "" Vector__XXX
 SG_ DEV_TME_RefrCir_pCndsIn_VW_Data : 12|8@1+ (0.1,0) [0|25.5] "" Vector__XXX
 SG_ DEV_TME_Pmp_stRadOutDiag_VW_Data : 20|3@1+ (1,0) [0|7] "" Vector__XXX
 SG_ DEV_TME_AC_nCmpr_VW_Data : 23|9@1+ (32,0) [0|9000] "" Vector__XXX
 SG_ DEV_TME_CoCir_tCoHeatRegIn_VW_Data : 32|8@1+ (0.8,-45) [-45|159] "" Vector__XXX
 SG_ DEV_TME_CoCir_tCoRadIn_VW_Data : 40|8@1+ (0.8,-45) [-45|159] "" Vector__XXX
 SG_ DEV_TME_CoCir_tCoCmbEngIn_VW_Data : 48|8@1+ (0.8,-45) [-45|159] "" Vector__XXX
 SG_ DEV_TME_CoCir_tCoCmbEngOut_VW_Data : 56|8@1+ (0.8,-45) [-45|159] "" Vector__XXX

BO_ 2617119241 DEV_TME_Resp_09: 8 TME
 SG_ DEV_TME_AC_tInv_VW_Data : 0|8@1+ (0.8,-45) [-45|159] "" Vector__XXX
 SG_ DEV_TME_RefrCir_tCmprOut_VW_Data : 8|8@1+ (0.8,-45) [-45|159] "" Vector__XXX
 SG_ DEV_TME_RefrCir_tCmprIn_VW_Data : 16|8@1+ (0.8,-45) [-45|159] "" Vector__XXX
 SG_ DEV_TME_TmeCoc_rPmpBattMin_volfBattMin_VW_Data : 24|7@1+ (1,0) [0|100] "" Vector__XXX
 SG_ DEV_TME_TmeRcc_rDemFan_VW_Data : 31|7@1+ (1,0) [0|100] "" Vector__XXX
 SG_ DEV_TME_TmeHeatSrcCtl_bCoProtAcvMes_VW_Data : 38|1@1+ (1,0) [0|1] "" Vector__XXX
 SG_ DEV_TME_TmeHeatSrcCtl_tCtlDeMes_VW_Data : 39|9@1+ (0.4,-100) [-100|100] "" Vector__XXX
 SG_ DEV_TME_TmeHeatSrcCtl_noOpmMes_VW_Data : 48|2@1+ (1,0) [0|3] "" Vector__XXX
 SG_ DEV_TME_TmeRcc_nCmprSet_VW_Data : 50|9@1+ (32,0) [0|9000] "" Vector__XXX
 SG_ DEV_TME_TmeRcc_bVlvEvp_VW_Data : 59|1@1+ (1,0) [0|1] "" Vector__XXX
 SG_ DEV_TME_TmeRcc_stCtlCmpr_VW_Data : 60|4@1+ (1,0) [0|15] "" Vector__XXX

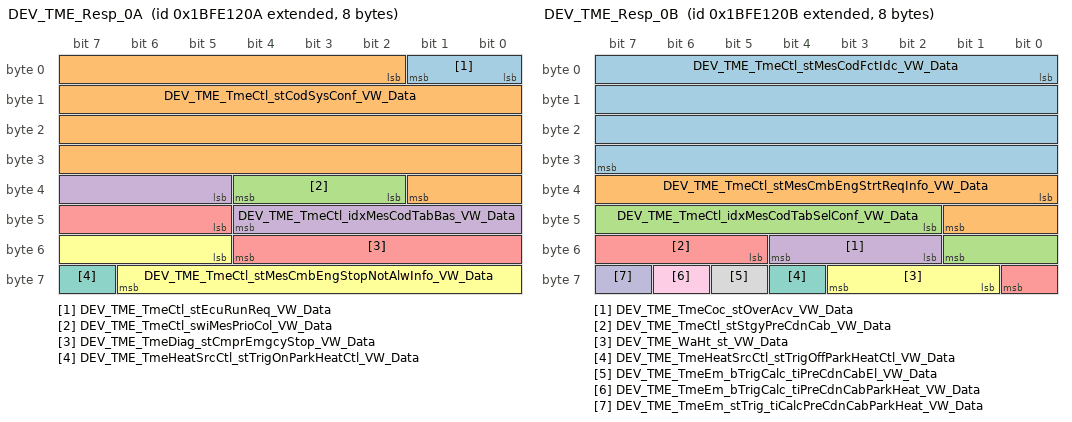
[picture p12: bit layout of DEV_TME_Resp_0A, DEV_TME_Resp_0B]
BO_ 2617119242 DEV_TME_Resp_0A: 8 TME
 SG_ DEV_TME_TmeCtl_stEcuRunReq_VW_Data : 0|2@1+ (1,0) [0|2] "" Vector__XXX
 SG_ DEV_TME_TmeCtl_stCodSysConf_VW_Data : 2|32@1+ (1,0) [0|4294967295] "" Vector__XXX
 SG_ DEV_TME_TmeCtl_swiMesPrioCol_VW_Data : 34|3@1+ (1,0) [0|5] "" Vector__XXX
 SG_ DEV_TME_TmeCtl_idxMesCodTabBas_VW_Data : 37|8@1+ (1,0) [0|255] "" Vector__XXX
 SG_ DEV_TME_TmeDiag_stCmprEmgcyStop_VW_Data : 45|8@1+ (1,0) [0|255] "" Vector__XXX
 SG_ DEV_TME_TmeCtl_stMesCmbEngStopNotAlwInfo_VW_Data : 53|10@1+ (1,0) [0|1023] "" Vector__XXX
 SG_ DEV_TME_TmeHeatSrcCtl_stTrigOnParkHeatCtl_VW_Data : 63|1@1+ (1,0) [0|1] "" Vector__XXX

BO_ 2617119243 DEV_TME_Resp_0B: 8 TME
 SG_ DEV_TME_TmeCtl_stMesCodFctIdc_VW_Data : 0|32@1+ (1,0) [0|4294967295] "" Vector__XXX
 SG_ DEV_TME_TmeCtl_stMesCmbEngStrtReqInfo_VW_Data : 32|10@1+ (1,0) [0|1023] "" Vector__XXX
 SG_ DEV_TME_TmeCtl_idxMesCodTabSelConf_VW_Data : 42|8@1+ (1,0) [0|255] "" Vector__XXX
 SG_ DEV_TME_TmeCoc_stOverAcv_VW_Data : 50|3@1+ (1,0) [0|7] "" Vector__XXX
 SG_ DEV_TME_TmeCtl_stStgyPreCdnCab_VW_Data : 53|4@1+ (1,0) [0|15] "" Vector__XXX
 SG_ DEV_TME_WaHt_st_VW_Data : 57|3@1+ (1,0) [0|7] "" Vector__XXX
 SG_ DEV_TME_TmeHeatSrcCtl_stTrigOffParkHeatCtl_VW_Data : 60|1@1+ (1,0) [0|1] "" Vector__XXX
 SG_ DEV_TME_TmeEm_bTrigCalc_tiPreCdnCabEl_VW_Data : 61|1@1+ (1,0) [0|1] "" Vector__XXX
 SG_ DEV_TME_TmeEm_bTrigCalc_tiPreCdnCabParkHeat_VW_Data : 62|1@1+ (1,0) [0|1] "" Vector__XXX
 SG_ DEV_TME_TmeEm_stTrig_tiCalcPreCdnCabParkHeat_VW_Data : 63|1@1+ (1,0) [0|1] "" Vector__XXX

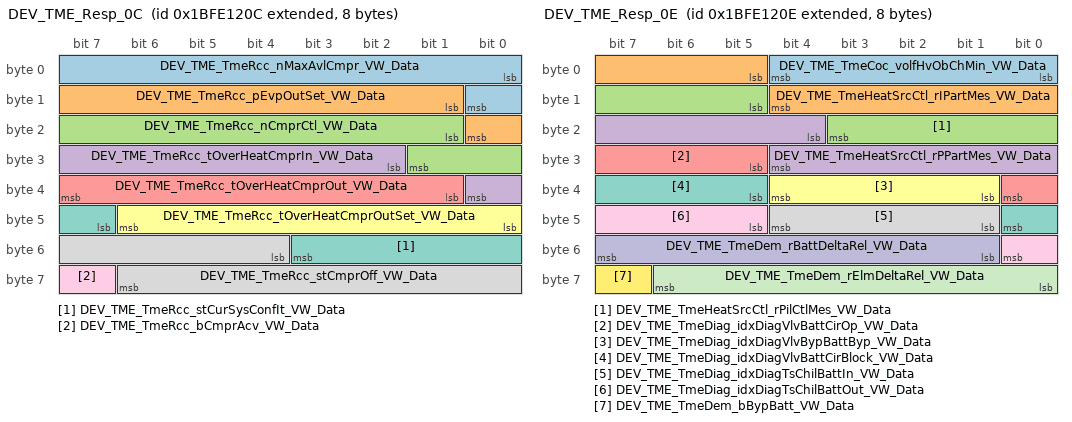
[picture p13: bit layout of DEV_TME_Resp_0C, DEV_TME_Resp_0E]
BO_ 2617119244 DEV_TME_Resp_0C: 8 TME
 SG_ DEV_TME_TmeRcc_nMaxAvlCmpr_VW_Data : 0|9@1+ (32,0) [0|9000] "" Vector__XXX
 SG_ DEV_TME_TmeRcc_pEvpOutSet_VW_Data : 9|8@1+ (0.015625,2) [2|5] "" Vector__XXX
 SG_ DEV_TME_TmeRcc_nCmprCtl_VW_Data : 17|9@1+ (32,0) [0|9000] "" Vector__XXX
 SG_ DEV_TME_TmeRcc_tOverHeatCmprIn_VW_Data : 26|7@1+ (0.8,-15) [-15|86] "" Vector__XXX
 SG_ DEV_TME_TmeRcc_tOverHeatCmprOut_VW_Data : 33|7@1+ (0.8,-15) [-15|86] "" Vector__XXX
 SG_ DEV_TME_TmeRcc_tOverHeatCmprOutSet_VW_Data : 40|7@1+ (0.8,0) [0|100] "" Vector__XXX
 SG_ DEV_TME_TmeRcc_stCurSysConfIt_VW_Data : 47|5@1+ (1,0) [0|31] "" Vector__XXX
 SG_ DEV_TME_TmeRcc_stCmprOff_VW_Data : 52|11@1+ (1,0) [0|2047] "" Vector__XXX
 SG_ DEV_TME_TmeRcc_bCmprAcv_VW_Data : 63|1@1+ (1,0) [0|1] "" Vector__XXX

BO_ 2617119245 DEV_TME_Resp_0D: 8 TME
 SG_ DEV_TME_TmeRcc_stDer_nCmpr_VW_Data : 0|6@1+ (1,0) [0|63] "" Vector__XXX
 SG_ DEV_TME_TmeRcc_stSysConfItSet_VW_Data : 6|5@1+ (1,0) [0|31] "" Vector__XXX
 SG_ DEV_TME_AC_stCmpr_VW_Data : 11|3@1+ (1,0) [0|7] "" Vector__XXX
 SG_ DEV_TME_TmeRcc_bGlbCtlEna_VW_Data : 14|1@1+ (1,0) [0|1] "" Vector__XXX
 SG_ DEV_TME_TmeRcc_bVlvChilBatt_VW_Data : 15|1@1+ (1,0) [0|1] "" Vector__XXX
 SG_ DEV_TME_TmeDem_tCoHeatExchInWaHeatSet_VW_Data : 16|8@1+ (0.8,-45) [-45|159] "" Vector__XXX
 SG_ DEV_TME_TmeRcc_tOverHeatCmprInSet_VW_Data : 24|7@1+ (0.8,0) [0|100] "" Vector__XXX
 SG_ DEV_TME_TmeDem_tCoHeatExchInHeatPmpSet_VW_Data : 31|8@1+ (0.8,-45) [-45|159] "" Vector__XXX
 SG_ DEV_TME_TmeRcc_bLeav2LvlMod_VW_Data : 39|1@1+ (1,0) [0|1] "" Vector__XXX
 SG_ DEV_TME_TmeRcc_bOverAcv_VW_Data : 40|1@1+ (1,0) [0|1] "" Vector__XXX
 SG_ DEV_TME_TmeRcc_bReqMinRevCmpr_VW_Data : 41|1@1+ (1,0) [0|1] "" Vector__XXX
 SG_ DEV_TME_FanPkg_stVarResp2_VW_Data : 42|4@1+ (1,0) [0|15] "" Vector__XXX
 SG_ DEV_TME_FanPkg_stVarResp1_VW_Data : 46|4@1+ (1,0) [0|15] "" Vector__XXX
 SG_ DEV_TME_TmeCtl_swiMesDiagRespRslt_VW_Data : 50|3@1+ (1,0) [0|5] "" Vector__XXX
 SG_ DEV_TME_FanPkg_stDiag2_VW_Data : 53|3@1+ (1,0) [0|7] "" Vector__XXX
 SG_ DEV_TME_FanPkg_stDiag1_VW_Data : 56|3@1+ (1,0) [0|7] "" Vector__XXX
 SG_ DEV_TME_TmeCoc_bCmbEngOverAcv_VW_Data : 59|1@1+ (1,0) [0|1] "" Vector__XXX
 SG_ DEV_TME_TmeCoc_bCoCirOverAcv_VW_Data : 60|1@1+ (1,0) [0|1] "" Vector__XXX
 SG_ DEV_TME_TmeHeatSrcCtl_bNotAcv_VW_Data : 61|1@1+ (1,0) [0|1] "" Vector__XXX
 SG_ DEV_TME_TmeHeatSrcCtl_bRedAcvMes_VW_Data : 62|1@1+ (1,0) [0|1] "" Vector__XXX
 SG_ DEV_TME_TmeCoc_bHeatCirOverAcv_VW_Data : 63|1@1+ (1,0) [0|1] "" Vector__XXX

BO_ 2617119246 DEV_TME_Resp_0E: 8 TME
 SG_ DEV_TME_TmeCoc_volfHvObChMin_VW_Data : 0|5@1+ (0.5,0) [0|15.5] "" Vector__XXX
 SG_ DEV_TME_TmeHeatSrcCtl_rIPartMes_VW_Data : 5|8@1+ (0.8,-100) [-100|100] "" Vector__XXX
 SG_ DEV_TME_TmeHeatSrcCtl_rPilCtlMes_VW_Data : 13|7@1+ (0.8,0) [0|100] "" Vector__XXX
 SG_ DEV_TME_TmeHeatSrcCtl_rPPartMes_VW_Data : 20|9@1+ (0.8,-200) [-200|100] "" Vector__XXX
 SG_ DEV_TME_TmeDiag_idxDiagVlvBattCirOp_VW_Data : 29|4@1+ (0.17,0) [0|2.55] "" Vector__XXX
 SG_ DEV_TME_TmeDiag_idxDiagVlvBypBattByp_VW_Data : 33|4@1+ (0.17,0) [0|2.55] "" Vector__XXX
 SG_ DEV_TME_TmeDiag_idxDiagVlvBattCirBlock_VW_Data : 37|4@1+ (0.17,0) [0|2.55] "" Vector__XXX
 SG_ DEV_TME_TmeDiag_idxDiagTsChilBattIn_VW_Data : 41|4@1+ (17,0) [0|2.55] "" Vector__XXX
 SG_ DEV_TME_TmeDiag_idxDiagTsChilBattOut_VW_Data : 45|4@1+ (17,0) [0|2.55] "" Vector__XXX
 SG_ DEV_TME_TmeDem_rBattDeltaRel_VW_Data : 49|7@1+ (1,0) [0|100] "" Vector__XXX
 SG_ DEV_TME_TmeDem_rElmDeltaRel_VW_Data : 56|7@1+ (1,0) [0|100] "" Vector__XXX
 SG_ DEV_TME_TmeDem_bBypBatt_VW_Data : 63|1@1+ (1,0) [0|1] "" Vector__XXX

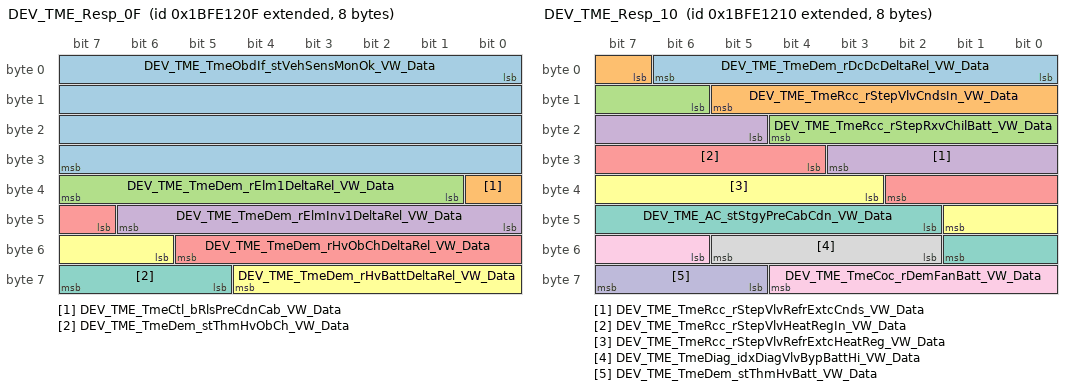
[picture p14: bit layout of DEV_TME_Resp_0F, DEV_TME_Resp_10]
BO_ 2617119247 DEV_TME_Resp_0F: 8 TME
 SG_ DEV_TME_TmeObdIf_stVehSensMonOk_VW_Data : 0|32@1+ (1,0) [0|4294967295] "" Vector__XXX
 SG_ DEV_TME_TmeCtl_bRlsPreCdnCab_VW_Data : 32|1@1+ (1,0) [0|1] "" Vector__XXX
 SG_ DEV_TME_TmeDem_rElm1DeltaRel_VW_Data : 33|7@1+ (1,0) [0|100] "" Vector__XXX
 SG_ DEV_TME_TmeDem_rElmInv1DeltaRel_VW_Data : 40|7@1+ (1,0) [0|100] "" Vector__XXX
 SG_ DEV_TME_TmeDem_rHvObChDeltaRel_VW_Data : 47|7@1+ (1,0) [0|100] "" Vector__XXX
 SG_ DEV_TME_TmeDem_rHvBattDeltaRel_VW_Data : 54|7@1+ (1,0) [0|100] "" Vector__XXX
 SG_ DEV_TME_TmeDem_stThmHvObCh_VW_Data : 61|3@1+ (1,0) [0|4] "" Vector__XXX

BO_ 2617119248 DEV_TME_Resp_10: 8 TME
 SG_ DEV_TME_TmeDem_rDcDcDeltaRel_VW_Data : 0|7@1+ (1,0) [0|100] "" Vector__XXX
 SG_ DEV_TME_TmeRcc_rStepVlvCndsIn_VW_Data : 7|7@1+ (0.8,0) [0|100] "" Vector__XXX
 SG_ DEV_TME_TmeRcc_rStepRxvChilBatt_VW_Data : 14|7@1+ (0.8,0) [0|100] "" Vector__XXX
 SG_ DEV_TME_TmeRcc_rStepVlvRefrExtcCnds_VW_Data : 21|7@1+ (0.8,0) [0|100] "" Vector__XXX
 SG_ DEV_TME_TmeRcc_rStepVlvHeatRegIn_VW_Data : 28|7@1+ (0.8,0) [0|100] "" Vector__XXX
 SG_ DEV_TME_TmeRcc_rStepVlvRefrExtcHeatReg_VW_Data : 35|7@1+ (0.8,0) [0|100] "" Vector__XXX
 SG_ DEV_TME_AC_stStgyPreCabCdn_VW_Data : 42|8@1+ (1,0) [0|255] "" Vector__XXX
 SG_ DEV_TME_TmeDiag_idxDiagVlvBypBattHi_VW_Data : 50|4@1+ (0.17,0) [0|2.55] "" Vector__XXX
 SG_ DEV_TME_TmeCoc_rDemFanBatt_VW_Data : 54|7@1+ (1,0) [0|100] "" Vector__XXX
 SG_ DEV_TME_TmeDem_stThmHvBatt_VW_Data : 61|3@1+ (1,0) [0|4] "" Vector__XXX

BO_ 2617119249 DEV_TME_Resp_11: 8 TME
 SG_ DEV_TME_TmeObdIf_stRefrCirMonOkPlaus_VW_Data : 0|32@1+ (1,0) [0|4294967295] "" Vector__XXX
 SG_ DEV_TME_TmeObdIf_stCoCirMonOkEl_VW_Data : 32|32@1+ (1,0) [0|4294967295] "" Vector__XXX

BO_ 2617119250 DEV_TME_Resp_12: 8 TME
 SG_ DEV_TME_TmeObdIf_stCoCirMonOkPlaus_VW_Data : 0|32@1+ (1,0) [0|4294967295] "" Vector__XXX
 SG_ DEV_TME_TmeObdIf_stRefrCirMonOkEl_VW_Data : 32|32@1+ (1,0) [0|4294967295] "" Vector__XXX

BO_ 2617119251 DEV_TME_Resp_13: 8 TME
 SG_ DEV_TME_TmeObdIf_stHeatCirMonOkEl_VW_Data : 0|32@1+ (1,0) [0|4294967295] "" Vector__XXX
 SG_ DEV_TME_TmeObdIf_stHeatCirMonOkPlaus_VW_Data : 32|32@1+ (1,0) [0|4294967295] "" Vector__XXX

BO_ 2617119252 DEV_TME_Resp_14: 8 TME
 SG_ DEV_TME_TmeCtl_stCodPsblConfExtd_VW_Data : 0|32@1+ (1,0) [0|4294967295] "" Vector__XXX
 SG_ DEV_TME_TmeCtl_stCodPsblConf_VW_Data : 32|32@1+ (1,0) [0|4294967295] "" Vector__XXX

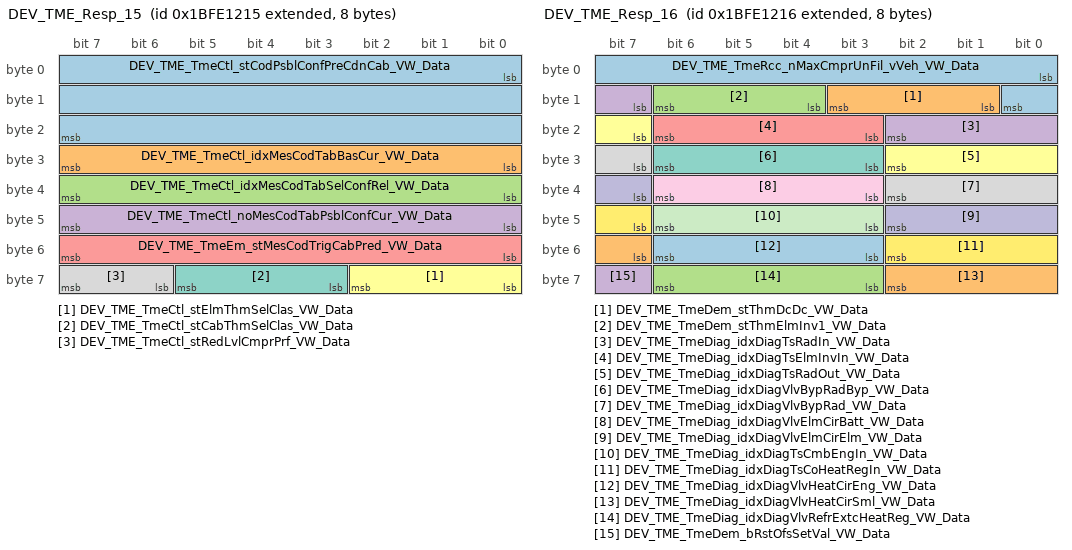
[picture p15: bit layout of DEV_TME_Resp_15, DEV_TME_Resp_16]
BO_ 2617119253 DEV_TME_Resp_15: 8 TME
 SG_ DEV_TME_TmeCtl_stCodPsblConfPreCdnCab_VW_Data : 0|24@1+ (1,0) [0|16777215] "" Vector__XXX
 SG_ DEV_TME_TmeCtl_idxMesCodTabBasCur_VW_Data : 24|8@1+ (1,0) [0|255] "" Vector__XXX
 SG_ DEV_TME_TmeCtl_idxMesCodTabSelConfRel_VW_Data : 32|8@1+ (1,0) [0|255] "" Vector__XXX
 SG_ DEV_TME_TmeCtl_noMesCodTabPsblConfCur_VW_Data : 40|8@1+ (1,0) [0|255] "" Vector__XXX
 SG_ DEV_TME_TmeEm_stMesCodTrigCabPred_VW_Data : 48|8@1+ (1,0) [0|255] "" Vector__XXX
 SG_ DEV_TME_TmeCtl_stElmThmSelClas_VW_Data : 56|3@1+ (1,0) [0|7] "" Vector__XXX
 SG_ DEV_TME_TmeCtl_stCabThmSelClas_VW_Data : 59|3@1+ (1,0) [0|7] "" Vector__XXX
 SG_ DEV_TME_TmeCtl_stRedLvlCmprPrf_VW_Data : 62|2@1+ (1,0) [0|3] "" Vector__XXX

BO_ 2617119254 DEV_TME_Resp_16: 8 TME
 SG_ DEV_TME_TmeRcc_nMaxCmprUnFil_vVeh_VW_Data : 0|9@1+ (32,0) [0|9000] "" Vector__XXX
 SG_ DEV_TME_TmeDem_stThmDcDc_VW_Data : 9|3@1+ (1,0) [0|7] "" Vector__XXX
 SG_ DEV_TME_TmeDem_stThmElmInv1_VW_Data : 12|3@1+ (1,0) [0|7] "" Vector__XXX
 SG_ DEV_TME_TmeDiag_idxDiagTsRadIn_VW_Data : 15|4@1+ (17,0) [0|2.55] "" Vector__XXX
 SG_ DEV_TME_TmeDiag_idxDiagTsElmInvIn_VW_Data : 19|4@1+ (17,0) [0|2.55] "" Vector__XXX
 SG_ DEV_TME_TmeDiag_idxDiagTsRadOut_VW_Data : 23|4@1+ (0.17,0) [0|2.55] "" Vector__XXX
 SG_ DEV_TME_TmeDiag_idxDiagVlvBypRadByp_VW_Data : 27|4@1+ (0.17,0) [0|2.55] "" Vector__XXX
 SG_ DEV_TME_TmeDiag_idxDiagVlvBypRad_VW_Data : 31|4@1+ (0.17,0) [0|2.55] "" Vector__XXX
 SG_ DEV_TME_TmeDiag_idxDiagVlvElmCirBatt_VW_Data : 35|4@1+ (0.17,0) [0|2.55] "" Vector__XXX
 SG_ DEV_TME_TmeDiag_idxDiagVlvElmCirElm_VW_Data : 39|4@1+ (0.17,0) [0|2.55] "" Vector__XXX
 SG_ DEV_TME_TmeDiag_idxDiagTsCmbEngIn_VW_Data : 43|4@1+ (17,0) [0|2.55] "" Vector__XXX
 SG_ DEV_TME_TmeDiag_idxDiagTsCoHeatRegIn_VW_Data : 47|4@1+ (17,0) [0|2.55] "" Vector__XXX
 SG_ DEV_TME_TmeDiag_idxDiagVlvHeatCirEng_VW_Data : 51|4@1+ (0.17,0) [0|2.55] "" Vector__XXX
 SG_ DEV_TME_TmeDiag_idxDiagVlvHeatCirSml_VW_Data : 55|4@1+ (0.17,0) [0|2.55] "" Vector__XXX
 SG_ DEV_TME_TmeDiag_idxDiagVlvRefrExtcHeatReg_VW_Data : 59|4@1+ (0.17,0) [0|2.55] "" Vector__XXX
 SG_ DEV_TME_TmeDem_bRstOfsSetVal_VW_Data : 63|1@1+ (1,0) [0|1] "" Vector__XXX

BO_ 2617119255 DEV_TME_Resp_17: 8 TME
 SG_ DEV_TME_TmeDiag_idxDiagVlvHeatRegIn_VW_Data : 0|4@1+ (0.17,0) [0|2.55] "" Vector__XXX
 SG_ DEV_TME_TmeDiag_idxDiagVlvCndsIn_VW_Data : 4|4@1+ (0.17,0) [0|2.55] "" Vector__XXX
 SG_ DEV_TME_TmeDiag_idxDiagTsCmprIn_VW_Data : 8|4@1+ (17,0) [0|2.55] "" Vector__XXX
 SG_ DEV_TME_TmeDiag_idxDiagTsVlvHeatRegIn_VW_Data : 12|4@1+ (0.17,0) [0|2.55] "" Vector__XXX
 SG_ DEV_TME_TmeDiag_idxDiagTsRxvChilBatt_VW_Data : 16|4@1+ (0.17,0) [0|2.55] "" Vector__XXX
 SG_ DEV_TME_TmeDiag_idxDiagTsVlvCndsIn_VW_Data : 20|4@1+ (0.17,0) [0|2.55] "" Vector__XXX
 SG_ DEV_TME_TmeDiag_idxDiagTsVlvCndsOut_VW_Data : 24|4@1+ (0.17,0) [0|2.55] "" Vector__XXX
 SG_ DEV_TME_TmeDiag_idxDiagTsCmprOut_VW_Data : 28|4@1+ (17,0) [0|2.55] "" Vector__XXX
 SG_ DEV_TME_TmeDiag_idxDiagTsExtcHeatReg_VW_Data : 32|4@1+ (17,0) [0|2.55] "" Vector__XXX
 SG_ DEV_TME_TmeDiag_idxDiagCoPrfLeak_VW_Data : 36|4@1+ (0.17,0) [0|2.55] "" Vector__XXX
 SG_ DEV_TME_FanPkg_stVarReq1_VW_Data : 40|2@1+ (1,0) [0|3] "" Vector__XXX
 SG_ DEV_TME_FanPkg_stVarReq2_VW_Data : 42|2@1+ (1,0) [0|3] "" Vector__XXX
 SG_ DEV_TME_TmeDiag_idxDiagFan2ItFail_VW_Data : 44|4@1+ (0.17,0) [0|2.55] "" Vector__XXX
 SG_ DEV_TME_TmeDiag_idxDiagFan2Block_VW_Data : 48|4@1+ (0.17,0) [0|2.55] "" Vector__XXX
 SG_ DEV_TME_TmeDiag_idxDiagFan2OverHeat_VW_Data : 52|4@1+ (0.17,0) [0|2.55] "" Vector__XXX
 SG_ DEV_TME_TmeDiag_idxDiagFan1OverHeat_VW_Data : 56|4@1+ (0.17,0) [0|2.55] "" Vector__XXX
 SG_ DEV_TME_TmeDiag_idxDiagFan1Block_VW_Data : 60|4@1+ (0.17,0) [0|2.55] "" Vector__XXX

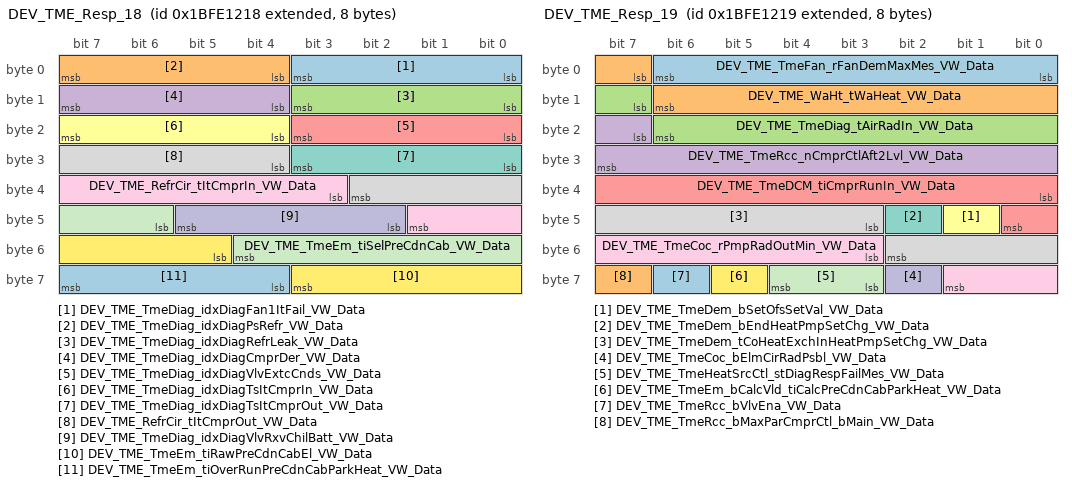
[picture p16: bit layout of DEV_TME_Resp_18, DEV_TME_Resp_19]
BO_ 2617119256 DEV_TME_Resp_18: 8 TME
 SG_ DEV_TME_TmeDiag_idxDiagFan1ItFail_VW_Data : 0|4@1+ (0.17,0) [0|2.55] "" Vector__XXX
 SG_ DEV_TME_TmeDiag_idxDiagPsRefr_VW_Data : 4|4@1+ (0.17,0) [0|2.55] "" Vector__XXX
 SG_ DEV_TME_TmeDiag_idxDiagRefrLeak_VW_Data : 8|4@1+ (17,0) [0|2.55] "" Vector__XXX
 SG_ DEV_TME_TmeDiag_idxDiagCmprDer_VW_Data : 12|4@1+ (0.17,0) [0|2.55] "" Vector__XXX
 SG_ DEV_TME_TmeDiag_idxDiagVlvExtcCnds_VW_Data : 16|4@1+ (0.17,0) [0|2.55] "" Vector__XXX
 SG_ DEV_TME_TmeDiag_idxDiagTsItCmprIn_VW_Data : 20|4@1+ (17,0) [0|2.55] "" Vector__XXX
 SG_ DEV_TME_TmeDiag_idxDiagTsItCmprOut_VW_Data : 24|4@1+ (17,0) [0|2.55] "" Vector__XXX
 SG_ DEV_TME_RefrCir_tItCmprOut_VW_Data : 28|7@1+ (1,-40) [-40|87] "" Vector__XXX
 SG_ DEV_TME_RefrCir_tItCmprIn_VW_Data : 35|7@1+ (1,-40) [-40|87] "" Vector__XXX
 SG_ DEV_TME_TmeDiag_idxDiagVlvRxvChilBatt_VW_Data : 42|4@1+ (0.17,0) [0|2.55] "" Vector__XXX
 SG_ DEV_TME_TmeEm_tiSelPreCdnCab_VW_Data : 46|7@1+ (1,0) [0|120] "" Vector__XXX
 SG_ DEV_TME_TmeEm_tiRawPreCdnCabEl_VW_Data : 53|7@1+ (1,0) [0|120] "" Vector__XXX
 SG_ DEV_TME_TmeEm_tiOverRunPreCdnCabParkHeat_VW_Data : 60|4@1+ (1,0) [0|15] "" Vector__XXX

BO_ 2617119257 DEV_TME_Resp_19: 8 TME
 SG_ DEV_TME_TmeFan_rFanDemMaxMes_VW_Data : 0|7@1+ (1,0) [0|100] "" Vector__XXX
 SG_ DEV_TME_WaHt_tWaHeat_VW_Data : 7|8@1+ (0.8,-45) [-45|159] "" Vector__XXX
 SG_ DEV_TME_TmeDiag_tAirRadIn_VW_Data : 15|8@1+ (0.8,-45) [-45|159] "" Vector__XXX
 SG_ DEV_TME_TmeRcc_nCmprCtlAft2Lvl_VW_Data : 23|9@1+ (32,0) [0|9000] "" Vector__XXX
 SG_ DEV_TME_TmeDCM_tiCmprRunIn_VW_Data : 32|9@1+ (1,0) [0|511] "" Vector__XXX
 SG_ DEV_TME_TmeDem_bSetOfsSetVal_VW_Data : 41|1@1+ (1,0) [0|1] "" Vector__XXX
 SG_ DEV_TME_TmeDem_bEndHeatPmpSetChg_VW_Data : 42|1@1+ (1,0) [0|1] "" Vector__XXX
 SG_ DEV_TME_TmeDem_tCoHeatExchInHeatPmpSetChg_VW_Data : 43|8@1+ (0.8,-45) [-45|159] "" Vector__XXX
 SG_ DEV_TME_TmeCoc_rPmpRadOutMin_VW_Data : 51|7@1+ (1,0) [0|100] "" Vector__XXX
 SG_ DEV_TME_TmeCoc_bElmCirRadPsbl_VW_Data : 58|1@1+ (1,0) [0|1] "" Vector__XXX
 SG_ DEV_TME_TmeHeatSrcCtl_stDiagRespFailMes_VW_Data : 59|2@1+ (1,0) [0|3] "" Vector__XXX
 SG_ DEV_TME_TmeEm_bCalcVld_tiCalcPreCdnCabParkHeat_VW_Data : 61|1@1+ (1,0) [0|1] "" Vector__XXX
 SG_ DEV_TME_TmeRcc_bVlvEna_VW_Data : 62|1@1+ (1,0) [0|1] "" Vector__XXX
 SG_ DEV_TME_TmeRcc_bMaxParCmprCtl_bMain_VW_Data : 63|1@1+ (1,0) [0|1] "" Vector__XXX

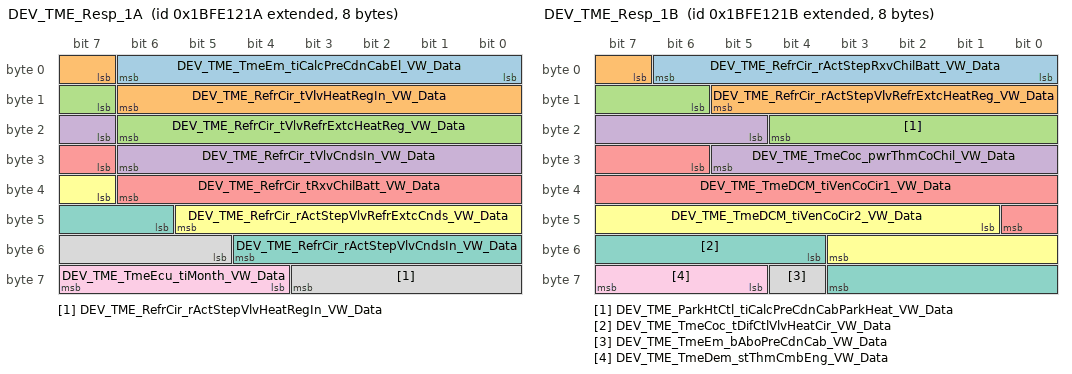
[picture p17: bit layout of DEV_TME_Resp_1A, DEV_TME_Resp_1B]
BO_ 2617119258 DEV_TME_Resp_1A: 8 TME
 SG_ DEV_TME_TmeEm_tiCalcPreCdnCabEl_VW_Data : 0|7@1+ (1,0) [0|120] "" Vector__XXX
 SG_ DEV_TME_RefrCir_tVlvHeatRegIn_VW_Data : 7|8@1+ (0.8,-50) [-50|154] "" Vector__XXX
 SG_ DEV_TME_RefrCir_tVlvRefrExtcHeatReg_VW_Data : 15|8@1+ (0.8,-50) [-50|154] "" Vector__XXX
 SG_ DEV_TME_RefrCir_tVlvCndsIn_VW_Data : 23|8@1+ (0.8,-50) [-50|154] "" Vector__XXX
 SG_ DEV_TME_RefrCir_tRxvChilBatt_VW_Data : 31|8@1+ (0.8,-50) [-50|154] "" Vector__XXX
 SG_ DEV_TME_RefrCir_rActStepVlvRefrExtcCnds_VW_Data : 39|7@1+ (0.8,0) [0|100] "" Vector__XXX
 SG_ DEV_TME_RefrCir_rActStepVlvCndsIn_VW_Data : 46|7@1+ (0.8,0) [0|100] "" Vector__XXX
 SG_ DEV_TME_RefrCir_rActStepVlvHeatRegIn_VW_Data : 53|7@1+ (0.8,0) [0|100] "" Vector__XXX
 SG_ DEV_TME_TmeEcu_tiMonth_VW_Data : 60|4@1+ (1,1) [1|12] "" Vector__XXX

BO_ 2617119259 DEV_TME_Resp_1B: 8 TME
 SG_ DEV_TME_RefrCir_rActStepRxvChilBatt_VW_Data : 0|7@1+ (0.8,0) [0|100] "" Vector__XXX
 SG_ DEV_TME_RefrCir_rActStepVlvRefrExtcHeatReg_VW_Data : 7|7@1+ (0.8,0) [0|100] "" Vector__XXX
 SG_ DEV_TME_ParkHtCtl_tiCalcPreCdnCabParkHeat_VW_Data : 14|7@1+ (1,0) [0|120] "" Vector__XXX
 SG_ DEV_TME_TmeCoc_pwrThmCoChil_VW_Data : 21|9@1+ (32,0) [0|16352] "" Vector__XXX
 SG_ DEV_TME_TmeDCM_tiVenCoCir1_VW_Data : 30|11@1+ (1,0) [0|2047] "" Vector__XXX
 SG_ DEV_TME_TmeDCM_tiVenCoCir2_VW_Data : 41|11@1+ (1,0) [0|2047] "" Vector__XXX
 SG_ DEV_TME_TmeCoc_tDifCtlVlvHeatCir_VW_Data : 52|8@1+ (0.8,-50) [-50|154] "" Vector__XXX
 SG_ DEV_TME_TmeEm_bAboPreCdnCab_VW_Data : 60|1@1+ (1,0) [0|1] "" Vector__XXX
 SG_ DEV_TME_TmeDem_stThmCmbEng_VW_Data : 61|3@1+ (1,0) [0|7] "" Vector__XXX

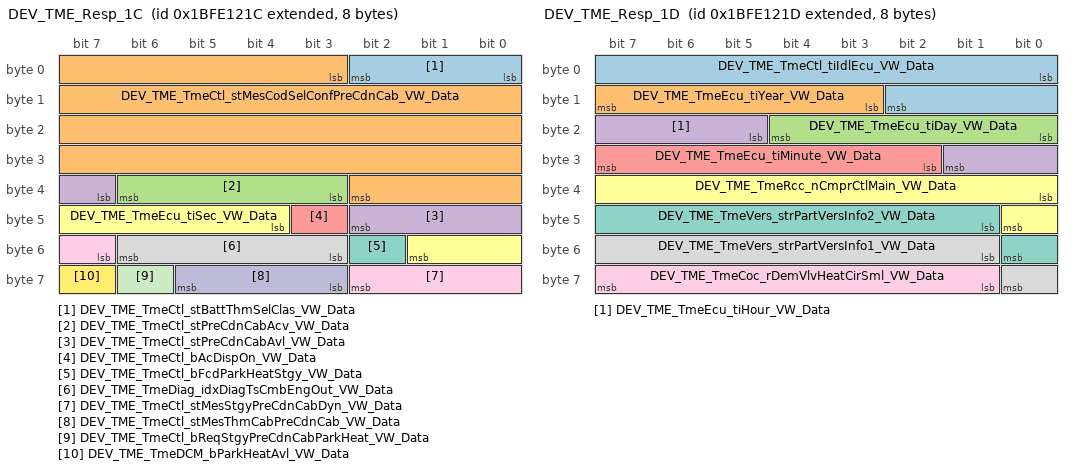
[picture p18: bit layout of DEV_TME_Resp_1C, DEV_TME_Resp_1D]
BO_ 2617119260 DEV_TME_Resp_1C: 8 TME
 SG_ DEV_TME_TmeCtl_stBattThmSelClas_VW_Data : 0|3@1+ (1,0) [0|7] "" Vector__XXX
 SG_ DEV_TME_TmeCtl_stMesCodSelConfPreCdnCab_VW_Data : 3|32@1+ (1,0) [0|4294967295] "" Vector__XXX
 SG_ DEV_TME_TmeCtl_stPreCdnCabAcv_VW_Data : 35|4@1+ (1,0) [0|15] "" Vector__XXX
 SG_ DEV_TME_TmeCtl_stPreCdnCabAvl_VW_Data : 39|4@1+ (1,0) [0|15] "" Vector__XXX
 SG_ DEV_TME_TmeCtl_bAcDispOn_VW_Data : 43|1@1+ (1,0) [0|1] "" Vector__XXX
 SG_ DEV_TME_TmeEcu_tiSec_VW_Data : 44|6@1+ (1,0) [0|59] "" Vector__XXX
 SG_ DEV_TME_TmeCtl_bFcdParkHeatStgy_VW_Data : 50|1@1+ (1,0) [0|1] "" Vector__XXX
 SG_ DEV_TME_TmeDiag_idxDiagTsCmbEngOut_VW_Data : 51|4@1+ (17,0) [0|2.55] "" Vector__XXX
 SG_ DEV_TME_TmeCtl_stMesStgyPreCdnCabDyn_VW_Data : 55|4@1+ (1,0) [0|15] "" Vector__XXX
 SG_ DEV_TME_TmeCtl_stMesThmCabPreCdnCab_VW_Data : 59|3@1+ (1,0) [0|7] "" Vector__XXX
 SG_ DEV_TME_TmeCtl_bReqStgyPreCdnCabParkHeat_VW_Data : 62|1@1+ (1,0) [0|1] "" Vector__XXX
 SG_ DEV_TME_TmeDCM_bParkHeatAvl_VW_Data : 63|1@1+ (1,0) [0|1] "" Vector__XXX

BO_ 2617119261 DEV_TME_Resp_1D: 8 TME
 SG_ DEV_TME_TmeCtl_tiIdlEcu_VW_Data : 0|11@1+ (8,0) [0|16376] "" Vector__XXX
 SG_ DEV_TME_TmeEcu_tiYear_VW_Data : 11|5@1+ (1,2000) [2000|2020] "" Vector__XXX
 SG_ DEV_TME_TmeEcu_tiDay_VW_Data : 16|5@1+ (1,0) [0|31] "" Vector__XXX
 SG_ DEV_TME_TmeEcu_tiHour_VW_Data : 21|5@1+ (1,0) [0|23] "" Vector__XXX
 SG_ DEV_TME_TmeEcu_tiMinute_VW_Data : 26|6@1+ (1,0) [0|59] "" Vector__XXX
 SG_ DEV_TME_TmeRcc_nCmprCtlMain_VW_Data : 32|9@1+ (32,0) [0|9000] "" Vector__XXX
 SG_ DEV_TME_TmeVers_strPartVersInfo2_VW_Data : 41|8@1+ (1,0) [0|255] "" Vector__XXX
 SG_ DEV_TME_TmeVers_strPartVersInfo1_VW_Data : 49|8@1+ (1,0) [0|255] "" Vector__XXX
 SG_ DEV_TME_TmeCoc_rDemVlvHeatCirSml_VW_Data : 57|7@1+ (1,0) [0|100] "" Vector__XXX

BO_ 2617119262 DEV_TME_Resp_1E: 8 TME
 SG_ DEV_TME_TmeCtl_stMesCodPsblPreCdnCab_VW_Data : 0|32@1+ (1,0) [0|4294967295] "" Vector__XXX
 SG_ DEV_TME_TmeCtl_stCodCdnSys2_VW_Data : 32|16@1+ (1,0) [0|65535] "" Vector__XXX
 SG_ DEV_TME_TmeCtl_stCodCdnEnv2_VW_Data : 48|16@1+ (1,0) [0|65535] "" Vector__XXX

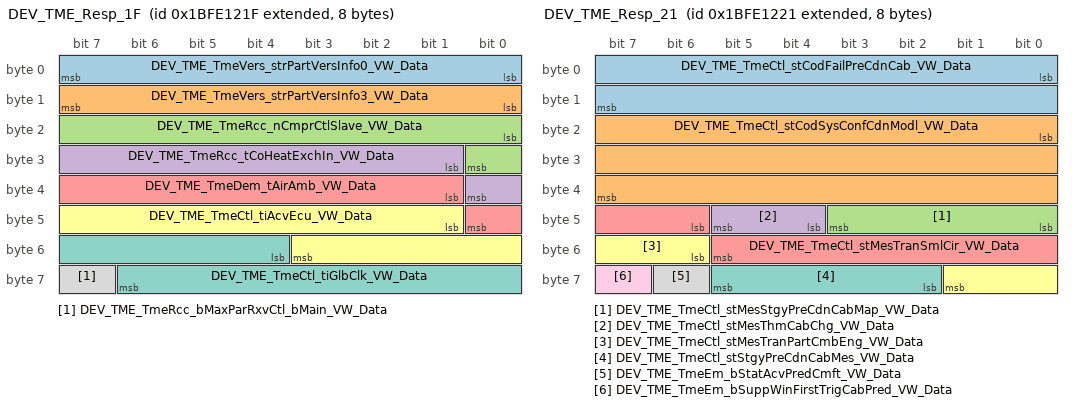
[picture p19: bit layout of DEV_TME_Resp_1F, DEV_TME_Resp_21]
BO_ 2617119263 DEV_TME_Resp_1F: 8 TME
 SG_ DEV_TME_TmeVers_strPartVersInfo0_VW_Data : 0|8@1+ (1,0) [0|255] "" Vector__XXX
 SG_ DEV_TME_TmeVers_strPartVersInfo3_VW_Data : 8|8@1+ (1,0) [0|255] "" Vector__XXX
 SG_ DEV_TME_TmeRcc_nCmprCtlSlave_VW_Data : 16|9@1+ (32,0) [0|9000] "" Vector__XXX
 SG_ DEV_TME_TmeRcc_tCoHeatExchIn_VW_Data : 25|8@1+ (0.8,-45) [-45|159] "" Vector__XXX
 SG_ DEV_TME_TmeDem_tAirAmb_VW_Data : 33|8@1+ (0.8,-45) [-45|159] "" Vector__XXX
 SG_ DEV_TME_TmeCtl_tiAcvEcu_VW_Data : 41|11@1+ (8,0) [0|16376] "" Vector__XXX
 SG_ DEV_TME_TmeCtl_tiGlbClk_VW_Data : 52|11@1+ (8,0) [0|16376] "" Vector__XXX
 SG_ DEV_TME_TmeRcc_bMaxParRxvCtl_bMain_VW_Data : 63|1@1+ (1,0) [0|1] "" Vector__XXX

BO_ 2617119264 DEV_TME_Resp_20: 8 TME
 SG_ DEV_TME_TmeCtl_stCodCdnSys1_VW_Data : 0|32@1+ (1,0) [0|4294967295] "" Vector__XXX
 SG_ DEV_TME_TmeCtl_stCodCdnEnv1_VW_Data : 32|32@1+ (1,0) [0|4294967295] "" Vector__XXX

BO_ 2617119265 DEV_TME_Resp_21: 8 TME
 SG_ DEV_TME_TmeCtl_stCodFailPreCdnCab_VW_Data : 0|16@1+ (1,0) [0|65535] "" Vector__XXX
 SG_ DEV_TME_TmeCtl_stCodSysConfCdnModl_VW_Data : 16|24@1+ (1,0) [0|16777215] "" Vector__XXX
 SG_ DEV_TME_TmeCtl_stMesStgyPreCdnCabMap_VW_Data : 40|4@1+ (1,0) [0|15] "" Vector__XXX
 SG_ DEV_TME_TmeCtl_stMesThmCabChg_VW_Data : 44|2@1+ (1,-1) [-1|2] "" Vector__XXX
 SG_ DEV_TME_TmeCtl_stMesTranSmlCir_VW_Data : 46|8@1+ (1,0) [0|255] "" Vector__XXX
 SG_ DEV_TME_TmeCtl_stMesTranPartCmbEng_VW_Data : 54|4@1+ (1,0) [0|15] "" Vector__XXX
 SG_ DEV_TME_TmeCtl_stStgyPreCdnCabMes_VW_Data : 58|4@1+ (1,0) [0|15] "" Vector__XXX
 SG_ DEV_TME_TmeEm_bStatAcvPredCmft_VW_Data : 62|1@1+ (1,0) [0|1] "" Vector__XXX
 SG_ DEV_TME_TmeEm_bSuppWinFirstTrigCabPred_VW_Data : 63|1@1+ (1,0) [0|1] "" Vector__XXX

BO_TX_BU_ 871 :BMS_MV,DCDC_800V_PAG;
BO_TX_BU_ 1443 :BMS_MV,DCDC_800V_PAG;
BO_TX_BU_ 2589283412 :BMS_MV,DCDC_800V_PAG;
BO_TX_BU_ 2589283608 :BMS_MV,DCDC_800V_PAG;
BO_TX_BU_ 2589283606 :BMS_MV,DCDC_800V_PAG;
BO_TX_BU_ 1021 :BMS_MV,DCDC_800V_PAG;
BO_TX_BU_ 901 :Gateway,Gateway_PAG;
BO_TX_BU_ 1022 :Gateway,Gateway_PAG;
BO_TX_BU_ 686 :DCDC_800V_PAG,DCDC_HV,LE_MLBevo;
BO_TX_BU_ 1012 :DCDC_800V_PAG,DCDC_HV,LE_MLBevo;
BO_TX_BU_ 1485 :DCDC_800V_PAG,DCDC_HV,LE_MLBevo;
BO_TX_BU_ 685 :DCDC_800V_PAG,DCDC_IHEV;
BO_TX_BU_ 1018 :DCDC_800V_PAG,DCDC_IHEV;
BO_TX_BU_ 1484 :DCDC_800V_PAG,DCDC_IHEV;
BO_TX_BU_ 2617238016 :DCDC_HV,LE_MLBevo;
BO_TX_BU_ 2617238271 :DCDC_HV,LE_MLBevo;

CM_ BO_ 901 "ab MQB ohne CHK und mit geänderter Sendeart";

CM_ SG_ 871 BMS_MV_03_BZ "4bit Botschaftszähler, wird mit jeder Sendebotschaft inkrementiert";
CM_ SG_ 871 BMS_MV_03_CRC "Für MLB:
Berechnung siehe Lastenheft 'Kommunikationsabsicherung für FlexRay und CAN'
Ab MQB und MLBevo:
Berechnung siehe Lastenheft 'End-to-End Kommunikationsabsicherung'

Endwerte siehe Begleitdokument 'S-PDU Kennungsfolgen'";
CM_ SG_ 871 BMS_MV_Leistungsreduzierung "Signalisierung der Performanceeinschränkung der 48V Batterie aufgrund hoher Temperatur";
CM_ SG_ 871 BMS_MV_Max_LadeSpannung "max. voltage / maximal erlaubte Batteriespannung (zwingend einzuhaltender Grenzwert)";
CM_ SG_ 871 BMS_MV_MaxPred_EntladeStrom "dynamic el. limit, max. current (discharge) for the specified time (e.g. 10s): and the voltage limit (only for prediction)
rechnerischer Wert: quasistationärer, für eine Dauer von z.B. 10s garantierter maximaler Entladestrom";
CM_ SG_ 871 BMS_MV_MaxPred_LadeStrom "dynamic el. limit, max. current (charge) for the specified time (e.g. 10s), and the voltage limit (only for prediction) 
rechnerischer Wert: quasistationärer, für eine Dauer von z.B. 10s garantierter maximaler Ladestrom";
CM_ SG_ 871 BMS_MV_MinPred_EntladeSpannung "static el. limit, min. battery voltage (e.g. 10s) during current MaxPred_EntladeStrom resp iDisChPredMax / rechnerischer Wert: minimales, für eine Dauer von z.B.  10s garantiertes Spannungsniveau, das unter Belastung mit MaxPred_EntladeStrom bzw. iDisChPr";
CM_ SG_ 871 BMS_MV_MinPred_LadeSpannung "static el. limit, min. battery voltage (e.g. 10s) during current MaxPred_LadeStrom resp. iChPredMax / rechnerischer Wert: minimales, für eine Dauer von z.B. 10s garantiertes Spannungsniveau, das unter Belastung mit MaxPred_LadeStrom bzw. iChPredMax nicht ";

CM_ SG_ 1443 BMS_MV_04_BZ "4bit Botschaftszähler, wird mit jeder Sendebotschaft inkrementiert";
CM_ SG_ 1443 BMS_MV_04_CRC "Für MLB:
Berechnung siehe Lastenheft 'Kommunikationsabsicherung für FlexRay und CAN'
Ab MQB und MLBevo:
Berechnung siehe Lastenheft 'End-to-End Kommunikationsabsicherung'

Endwerte siehe Begleitdokument 'S-PDU Kennungsfolgen'";
CM_ SG_ 1443 BMS_MV_FehlerStatus "aktueller Fehlerstatus der Batterie";
CM_ SG_ 1443 BMS_MV_IstModus "actual state of the battery / momentaner Status der Batterie
0: Standby; Kommunikation aktiv
1: Hauptschütze geschlossen / MV-Netz aktiviert / normaler Fahrbetrieb
5: interner Batteriefehler / angeforderter Modus kann nicht eingestellt werden
7: Initi";
CM_ SG_ 1443 BMS_MV_OBD_Lampe_Anf "Anforderung MIL (MalfunctionIndicationLamp) von BMS (Motorsteuergerät reicht diese Info an Kombi weiter).";

CM_ SG_ 2589283412 BMS_MV_IstRuecklaufTemperatur "Aktuelle Ruecklauftemperatur der Batterie

Abweichender individueller Init-Wert = 254 (Standardkodierung = 254)";
CM_ SG_ 2589283412 BMS_MV_IstVorlaufTemperatur "Aktuelle Vorlauftemperatur der Batterie

Abweichender individueller Init-Wert = 254 (Standardkodierung = 254)";
CM_ SG_ 2589283412 BMS_MV_Soll_PWM_Pumpe "Fehlende Beschreibung (Import)";
CM_ SG_ 2589283412 BMS_MV_SollVolumenstrom "Mindestanforderung des Soll Volumenstrom für Kühlkreislauf Batterie";
CM_ SG_ 2589283412 BMS_MV_SollVorlauftemperatur "Soll_Vorlauftemperatur_Kühlmedium in °C

Abweichender individueller Init-Wert = 254 (Standardkodierung = 254)";
CM_ SG_ 2589283412 BMS_MV_Speichertechnologie "Speichertechnologie des MV-Speichers. Zuordnung zur Technologie in MV FLAH.";
CM_ SG_ 2589283412 BMS_MV_Temp_Epsilon "Das Signal beschreibt die Differenz zwischen Batterie Soll-Temperatur und Batterie Ist-Temperatur.";
CM_ SG_ 2589283412 BMS_MV_Temperatur "battery temperature / Momentanwert: Temperatur der Traktionsbatterie

Abweichender individueller Init-Wert = 254 (Standardkodierung = 254)";
CM_ SG_ 2589283412 BMS_MV_Temperierung_Anf "Temperierungsbedarf der HV-Batterie";

CM_ SG_ 2589283608 BMS_MV_Energieinhalt "aktuell nutzbarer Energieinhalt der MV-Batterie
(bezogen auf ein definiertes mittleres Belastungsprofil)";
CM_ SG_ 2589283608 BMS_MV_MaxEnergieinhalt "maximaler nutzbarer Energieinhalt der MV-Batterie (bezogen auf Last KBI_RWDS_Lastprofil bei SOC=100%)
Abhängig von KBI_RWDS_Lastprofil";

CM_ SG_ 2589283606 BMS_MV_max_Grenz_SOC "oberer Grenz SOC - Betriebsstrategie";
CM_ SG_ 2589283606 BMS_MV_SOC_Kaltstart "Abhängig von der notwendigen Kaltstartleistung berechneter SOC Wert.";

CM_ SG_ 1021 BMS_MV_Pred_Entladeperformance "Indikator Stromintegral in Entladerichtung. 
0%     = Start abrampen Peak-Entladestromgrenze auf Dauer-Entladestromgrenze.
100% = Voller Peak-Entladestrom verfügbar";
CM_ SG_ 1021 BMS_MV_Pred_Ladeperformance "Indikator Stromintegral in Laderichtung. 
0%     = Start abrampen Peak-Ladestromgrenze auf Dauer-Ladestromgrenze.
100% = Voller Peak-Ladestrom verfügbar";

CM_ SG_ 499 BMS_NV_01_BZ "-";
CM_ SG_ 499 BMS_NV_01_CRC "Berechnung siehe Lastenheft 'End-to-End Kommunikationsabsicherung'";
CM_ SG_ 499 BMS_NV_BatterieAb "Detektion einer Verbindungsunterbrechung von oder zur Batterie bzw. Funktion der Batterie ist nicht gegeben
- Polunterbrechung
- Bolzen- oder Massekabelunterbrechung
- interne Unterbechung
Funktion bei geschlossenem Trennelement";
CM_ SG_ 499 BMS_NV_FMAus_Info "Freilauf Informationssignal zum Freilaufkoordinator. 
Gilt nur für die Freilauf Phase. Verwendung im MicroHybrid.";
CM_ SG_ 499 BMS_NV_IstModus "actual state of the battery / momentaner Status der Batterie
Standby; Kommunikation aktiv
Hauptschütz geschlossen / NV-Netz aktiviert / normaler Fahrbetrieb
interner Batteriefehler / angeforderter Modus kann nicht eingestellt werdenInitialisierung";
CM_ SG_ 499 BMS_NV_IstSpannung "actual voltage of the battery / Momentanwert: Batteriespannung";
CM_ SG_ 499 BMS_NV_IstStrom "Ausgabe des aktuell gemessenen Stroms des 12V Zusatzspeichers.
negative Werte: Entladestrom bezogen auf den Energiespeicher
positive Werte: Ladestrom bezogen auf den Energiespeicher";
CM_ SG_ 499 BMS_NV_StSt_Nutzbare_Ladung "Energie aus dem Zusatzspeicher, welche für die StartStopp-Funktion in den Stopp-Phasen genutzt wird. Wird berücksichtig zur Bildung des Signals BEM_StartStopp_Info";
CM_ SG_ 499 BMS_NV_TE_Status "Garantierte Unterstützung des Zusatzspeichers. Nur bei garantierter Bordnetztstützung des Zusatzspeichers kann in Freilauf-Motor-Aus Phase übergegangen werden. Geht der Zustand von 'Trennelement_geschlossen_Mindestzeit' auf 'Trennelement_geschlossen' blei";

CM_ SG_ 504 BMS_NV_Fehlerstatus "aktueller Fehlerstatus der Batterie";
CM_ SG_ 504 BMS_NV_IMaxStart "Aktuell gemessenes Stromdelta bei aktuellem Spannungseinbruch";
CM_ SG_ 504 BMS_NV_Qe_LI_Inhalt "Bei größer 0 ist ein RSG Start mit den vorgegebenen Strom und Spannungsgrenzen noch möglich";
CM_ SG_ 504 BMS_NV_Ri_Batterie "Innenwiderstand in Entladerichtung";
CM_ SG_ 504 BMS_NV_SOC "State of Charge / aktueller Ladezustand der Batterie";
CM_ SG_ 504 BMS_NV_UMinStart "Aktuell gemessener Spannungseinbruch (Minimalwert der Spannung) des letzten Motorstarts ";

CM_ SG_ 874 BMS_NV_Diagnose_Anf "Wunsch zur Diagnose des Trennelements und Anforderung von Prüfpulsen für BZE";
CM_ SG_ 874 BMS_NV_Kapazitaet_akt "Gesamtenergiekapazitaet der NV-Batterie unter Berücksichtigung der Alterung";
CM_ SG_ 874 BMS_NV_Max_EntladeStrom "maximal zulässiger Entladestrom";
CM_ SG_ 874 BMS_NV_Max_LadeSpannung "max. voltage / maximal erlaubte Batteriespannung (zwingend einzuhaltender Grenzwert)";
CM_ SG_ 874 BMS_NV_Max_LadeStrom "maximal zulässiger Ladestrom";
CM_ SG_ 874 BMS_NV_Min_EntladeSpannung "min. voltage / minimal erlaubte Batteriespannung (zwingend einzuhaltender Grenzwert)";
CM_ SG_ 874 BMS_NV_Temperatur "battery temperature / Momentanwert: Temperatur der Batterie";

CM_ SG_ 2463978664 BMS_NV_Polspannung "Spannung gemessen unmittelbar vor den Polen des Speichers";

CM_ SG_ 2463978720 BMS_NV_05_BZ "4bit Botschaftszähler, wird mit jeder Sendebotschaft inkrementiert";
CM_ SG_ 2463978720 BMS_NV_05_CRC "Für MLB:
Berechnung siehe Lastenheft 'Kommunikationsabsicherung für FlexRay und CAN'
Ab MQB und MLBevo:
Berechnung siehe Lastenheft 'End-to-End Kommunikationsabsicherung'

Endwerte siehe Begleitdokument 'S-PDU Kennungsfolgen'";
CM_ SG_ 2463978720 BMS_NV_IstDyn_EntladeStrom "dynamic el. limit, max. current (discharge) for the specified time (e.g. 1s): under consideration of voltage limit (BMS_NV_SollDyn_EntladeSpannung) //
rechnerischer Wert: quasistationärer, für eine Dauer von z.B. 1s garantierter maximaler Entladestrom un";
CM_ SG_ 2463978720 BMS_NV_IstPred_EntladeStrom "prediction el. limit, max. current (discharge) for the specified time (e.g. 18s): under consideration of voltage limit (BMS_NV_SollPred_EntladeSpannung) //
rechnerischer Wert: quasistationärer, für eine Dauer von z.B. 18s garantierter maximaler Entladest";
CM_ SG_ 2463978720 BMS_NV_SollDyn_EntladeSpannung "min. voltage during discharge with current BMS_NV_IstDyn_EntladeStrom // fester Wert: für eine Dauer von ~1s garantiertes Spannungsniveau, das unter Belastung mit BMS_NV_IstDyn_EntladeStrom nicht unterschritten werden würde.";
CM_ SG_ 2463978720 BMS_NV_SollPred_EntladeSpannung "min. voltage during discharge with current BMS_NV_IstPred_EntladeStrom // fester Wert: für eine Dauer von ~18s garantiertes Spannungsniveau, das unter Belastung mit BMS_NV_IstPred_EntladeStrom nicht unterschritten werden würde.";

CM_ SG_ 901 CHA_Fahrer_Umschaltung "Die manuelle Umschaltung durch den Fahrer soll signalisiert werden, um zu automatischen Umschaltungen (z.B. Retries) differenzieren zu können.";
CM_ SG_ 901 CHA_Fahrer_Umschaltung_BMA "Die manuelle Umschaltung der Betriebsmodusauswahl durch den Fahrer soll signalisiert werden, um zu automatischen Umschaltungen (z.B. Retries) differenzieren zu können.";
CM_ SG_ 901 CHA_Ziel_FahrPr_ACC "MQB
Anforderung Ziel-Fahrprogramm ACC";
CM_ SG_ 901 CHA_Ziel_FahrPr_AFS "Anforderung Ziel-Fahrprogramm AFS";
CM_ SG_ 901 CHA_Ziel_FahrPr_AGA "Anforderung Ziel-Fahrprogramm AGA/SAK2 (Aussensound)";
CM_ SG_ 901 CHA_Ziel_FahrPr_ALR "Anforderung Ziel-Fahrprogramm Allrad";
CM_ SG_ 901 CHA_Ziel_FahrPr_DR "Anforderung Ziel-Fahrprogramm Dämpfer";
CM_ SG_ 901 CHA_Ziel_FahrPr_EPS "Anforderung Ziel-Fahrprogramm Elektrische Lenkhilfe";
CM_ SG_ 901 CHA_Ziel_FahrPr_ESP "Anforderung Ziel-Fahrprogramm ESP";
CM_ SG_ 901 CHA_Ziel_FahrPr_Freilauf "Anforderung Ziel-Fahrprogramm Funktion Freilauf";
CM_ SG_ 901 CHA_Ziel_FahrPr_GE "Anforderung Ziel-Fahrprogramm Getriebe";
CM_ SG_ 901 CHA_Ziel_FahrPr_MO "Anforderung Ziel-Fahrprogramm Motor";
CM_ SG_ 901 CHA_Ziel_FahrPr_MO_BZS "Anforderung Zielfahrprogramm Motor-Betriebszusände";
CM_ SG_ 901 CHA_Ziel_FahrPr_MO_StSt "Anforderung Ziel-Fahrprogramm Funktion Motor Start-Stopp";
CM_ SG_ 901 CHA_Ziel_FahrPr_PreCrash "Anforderung Ziel-Fahrprogramm VAQ";
CM_ SG_ 901 CHA_Ziel_FahrPr_SAK "Anforderung Ziel-Fahrprogramm Soundaktuator";
CM_ SG_ 901 CHA_Ziel_FahrPr_VAQ "Anforderung Ziel-Fahrprogramm VAQ";

CM_ SG_ 1022 CHA_Current_Mode_BMA "Aktuell eingestellter Charisma Betriebsmodus";
CM_ SG_ 1022 CHA_Fahrer_Umschaltung "Die manuelle Umschaltung durch den Fahrer soll signalisiert werden, um zu automatischen Umschaltungen (z.B. Retries) differenzieren zu können.";
CM_ SG_ 1022 CHA_Fahrer_Umschaltung_BMA "Die manuelle Umschaltung der Betriebsmodusauswahl durch den Fahrer soll signalisiert werden, um zu automatischen Umschaltungen (z.B. Retries) differenzieren zu können.";
CM_ SG_ 1022 CHA_Ziel_FahrPr_AGK "Signal zur Ansteuerung des Teilnehmers Abgasklappen durch den Charisma-Koordinator über das Motor-SG";
CM_ SG_ 1022 CHA_Ziel_FahrPr_BMS "Anforderung Ziel-Fahrprogramm BMS (nähere Spezifikation siehe Charisma-LH PAG)";
CM_ SG_ 1022 CHA_Ziel_FahrPr_EDS "Anforderung Ziel-Fahrprogramm Elektronische Differentialsperre";
CM_ SG_ 1022 CHA_Ziel_FahrPr_HHC "Anforderung Ziel-Fahrprogramm Hill Hold Control";
CM_ SG_ 1022 CHA_Ziel_FahrPr_MO_Freilauf "Anforderung Ziel-Fahrprogramm Funktion Freilauf Motor aus";
CM_ SG_ 1022 CHA_Ziel_FahrPr_PACC "Anforderung Ziel-Fahrprogramm InnoDrive (PACCh)";
CM_ SG_ 1022 CHA_Ziel_FahrPr_PDC "Signal zur Ansteuerung des PDC/PLA durch den Charisma-Koordinator";
CM_ SG_ 1022 CHA_Ziel_FahrPr_Reku_ZwGas "Anforderung Ziel-Fahrprogramm für Rekuperation oder Zwischengas";

CM_ SG_ 686 DC_IstSpannung_HV "Momentanwert:  Hochspannung am DC/DC Wandler";
CM_ SG_ 686 DC_IstSpannung_NV "Momentanwert: Bordnetzspannung am DC/DC Wandler";
CM_ SG_ 686 DC_IstStrom_HV_02 "Aktueller Strom des DC/DC-Wandlers Höherspannungsseitig.

Tiefsetzen - positiv
Hochsetzen - negativ";
CM_ SG_ 686 DC_IstStrom_NV "Momentanwert: Strom vom DC/DC in das Bordnetz
Tiefsetzen - positiv
Hochsetzen - negativ";
CM_ SG_ 686 DCDC_01_CRC "Für MLB:
'Berechnung siehe Lastenheft 'Kommunikationsabsicherung für FlexRay und CAN''

Ab MQB und MLBevo:
'Berechnung siehe Lastenheft 'End-to-End Kommunikationsabsicherung''

Endwerte siehe Begleitdokument 'S-PDU Kennungsfolgen'";

CM_ SG_ 1012 DC_HYB_Auslastungsgrad "Momentanwert: Auslastung DC/DC (DFM Signal), entspricht I_akt / I_max
(Vorhalt für MQB)";
CM_ SG_ 1012 DC_HYB_iAktReserveLV "Momentanwert: Stromreserve vom DC/DC-Wandler in Richtung 12V-Bordnetz
Im MLBevo nur positiver Bereich genutzt

Tiefsetzen - positiv
Hochsetzen - negativ";
CM_ SG_ 1012 DC_Verbrauch "Energieverbrauch vom DCDC für Versorgung 12V-Bordnetz inkl. seines eigenen Wirkungsgrads (bspw.: HV_Strom*HV_Spannung*t)";
CM_ SG_ 1012 DC_Verbrauch_Ueberlauf "Überlauf-Bit für das Signal DC_Verbrauch";
CM_ SG_ 1012 DC_Verlustleistung "Aktuelle Verlustleistung des DC/DC-Wandlers.";
CM_ SG_ 1012 DCDC_02_CRC "Für MLB:
'Berechnung siehe Lastenheft 'Kommunikationsabsicherung für FlexRay und CAN''

Ab MQB und MLBevo:
'Berechnung siehe Lastenheft 'End-to-End Kommunikationsabsicherung''

Endwerte siehe Begleitdokument 'S-PDU Kennungsfolgen'";

CM_ SG_ 1485 DC_Abregelung_Temperatur "Abregelung aufgrund Übertemperatur im Leistungsteil (Hochtemperatur-Abregelung)";
CM_ SG_ 1485 DC_Fehlerstatus "aktueller Fehlerstatus des DCDC-Wandler:";
CM_ SG_ 1485 DC_IstModus_02 "aktuelle Betriebsart des DC/DC Wandlers;";
CM_ SG_ 1485 DC_IstSpannung_EKK_HV "Ausgangsspannung des Kombiwandlers am 400V-Anschluss";
CM_ SG_ 1485 DC_Peakstrom_verfuegbar "Peakstrom verfügbar/nicht verfügbar";
CM_ SG_ 1485 DC_Status_Spgfreiheit_HV "HV DC/DC-Wandler Status HV-Spannungsfreiheit";
CM_ SG_ 1485 DC_Temperatur "Momentanwert: Temperatur des DC/DC Wandlers";
CM_ SG_ 1485 DCDC_03_CRC "Für MLB:
'Berechnung siehe Lastenheft 'Kommunikationsabsicherung für FlexRay und CAN''

Ab MQB und MLBevo:
'Berechnung siehe Lastenheft 'End-to-End Kommunikationsabsicherung''

Endwerte siehe Begleitdokument 'S-PDU Kennungsfolgen'";

CM_ SG_ 2589283653 DCDC_HV_02_01_BZ "4bit Botschaftszähler, wird mit jeder Sendebotschaft inkrementiert";
CM_ SG_ 2589283653 DCDC_HV_02_01_CRC "Für MLB:
Berechnung siehe Lastenheft 'Kommunikationsabsicherung für FlexRay und CAN'
Ab MQB und MLBevo:
Berechnung siehe Lastenheft 'End-to-End Kommunikationsabsicherung'

Endwerte siehe Begleitdokument 'S-PDU Kennungsfolgen'";
CM_ SG_ 2589283653 HVLB_AC_Laden_verfuegbar "Status Verfügbarkeit AC-Laden , Freigabe Schützansteuerung";
CM_ SG_ 2589283653 HVLB_DC_Laden_mitBoost_verfuegb "Status DC-Laden mit Booster";
CM_ SG_ 2589283653 HVLB_DC_Laden_ohneBoost_verfuegb "Status DC-Laden ohne Booster";
CM_ SG_ 2589283653 HVLB_Fehlerstatus "Fehlerstatus HV-Booster";
CM_ SG_ 2589283653 HVLB_IstModus "IstModus HV-Lade-Booster";
CM_ SG_ 2589283653 HVLB_IstModus_TN1 "Rueckmeldung Istmodus der Steuereinheit für das Schuetz des Teilnetz1 'Ladepfad':
0 : HV_Off                                
1 : HV_On (Schuetz geschlossen)                
2 : Fehler
3 : Init   (CAN-Initialisierung)";
CM_ SG_ 2589283653 HVLB_IstSpannung_DCLS "HV-Lade-Booster IstSpannung DC-Ladesäule";
CM_ SG_ 2589283653 HVLB_IstSpannung_HVHS "HV-Lade-Booster IstSpannung Ausgangsseite";
CM_ SG_ 2589283653 HVLB_IstStrom_HVHS "HV-Lade-Booster IstStrom Ausgangsseite";
CM_ SG_ 2589283653 HVLB_StatusSpgfreiheit_HV "HV-Lade-Booster Status HV-Spannungsfreiheit";
CM_ SG_ 2589283653 HVLB_Warnzustand "Warnzustand HV-Lade-Booster";

CM_ SG_ 2463978669 DCDC_HV_02_02_BZ "4bit Botschaftszähler, wird mit jeder Sendebotschaft inkrementiert";
CM_ SG_ 2463978669 DCDC_HV_02_02_CRC "Für MLB:
Berechnung siehe Lastenheft 'Kommunikationsabsicherung für FlexRay und CAN'
Ab MQB und MLBevo:
Berechnung siehe Lastenheft 'End-to-End Kommunikationsabsicherung'

Endwerte siehe Begleitdokument 'S-PDU Kennungsfolgen'";
CM_ SG_ 2463978669 HVLB_IstSpannung_HVLS "HV-Lade-Booster IstSpannung Eingangsseite";
CM_ SG_ 2463978669 HVLB_MaxDynStrom_HVLS "HV-Lade Booster, maximal zulässiger Strom Eingangsseite";
CM_ SG_ 2463978669 HVLB_Temperatur "HV-Lade-Booster Temperatur";

CM_ SG_ 2589283662 HVLB_PlanAntw_Verlustleistung "Antwort auf die Ladeplan-Anfrage für die Ladeplanung: Verlustleistung";
CM_ SG_ 2589283662 HVLB_PlanAntw_Zaehler "Antwort auf die Ladeplan-Anfrage für die Ladeplanung: Zähler";

CM_ SG_ 685 DC_MV_IstSpannung_MV "Momentanwert:  Hochspannung am DC/DC Wandler";
CM_ SG_ 685 DC_MV_IstSpannung_NV "Momentanwert: Bordnetzspannung am DC/DC Wandler";
CM_ SG_ 685 DC_MV_IstStrom_MV "Aktueller Strom des DC/DC-Wandlers Höherspannungsseitig.

Tiefsetzen - positiv
Hochsetzen - negativ";
CM_ SG_ 685 DC_MV_IstStrom_NV "Momentanwert: Strom vom DC/DC in das Bordnetz
Tiefsetzen - positiv
Hochsetzen - negativ";
CM_ SG_ 685 DCDC_MV_01_BZ "4bit Botschaftszähler, wird mit jeder Sendebotschaft inkrementiert";
CM_ SG_ 685 DCDC_MV_01_CRC "Für MLB:
Berechnung siehe Lastenheft 'Kommunikationsabsicherung für FlexRay und CAN'
Ab MQB und MLBevo:
Berechnung siehe Lastenheft 'End-to-End Kommunikationsabsicherung'

Endwerte siehe Begleitdokument 'S-PDU Kennungsfolgen'";

CM_ SG_ 1018 DC_MV_akt_Stromreserve_NV "Momentanwert: Stromreserve vom DC/DC-Wandler in Richtung 12V-Bordnetz
Im MLBevo nur positiver Bereich genutzt

Tiefsetzen - positiv
Hochsetzen - negativ";
CM_ SG_ 1018 DC_MV_Auslastungsgrad "Momentanwert: Auslastung DC/DC (DFM Signal), entspricht I_aktuell / I_verfügbar * 100%";
CM_ SG_ 1018 DC_MV_MaxStrom_MV "Momentanwert: maximaler Strom vom DC/DC-Wandler in Richtung MV-Bordnetz;
abhängig von Eingangsspannung und BT-Temperatur";
CM_ SG_ 1018 DCDC_MV_02_BZ "4bit Botschaftszähler, wird mit jeder Sendebotschaft inkrementiert";
CM_ SG_ 1018 DCDC_MV_02_CRC "Für MLB:
Berechnung siehe Lastenheft 'Kommunikationsabsicherung für FlexRay und CAN'
Ab MQB und MLBevo:
Berechnung siehe Lastenheft 'End-to-End Kommunikationsabsicherung'

Endwerte siehe Begleitdokument 'S-PDU Kennungsfolgen'";

CM_ SG_ 1484 DC_MV_12V_Bordnetzstuetzung "DC/DC-Wandler befindet sich im Betriebsmodus Bordnetzstützung";
CM_ SG_ 1484 DC_MV_Abregelung_Temperatur "Abregelung aufgrund Übertemperatur im Leistungsteil (Hochtemperatur-Abregelung)";
CM_ SG_ 1484 DC_MV_Dyn_MaxSpannung "Spannungsgrenze, um eine Leistungsbeschränkung des eAWS-Systems in einem speicherlosen 48V-Netz durchführen zu können";
CM_ SG_ 1484 DC_MV_Dyn_MinSpannung "Spannungsgrenze, um eine Leistungsbeschränkung des eAWS-Systems in einem speicherlosen 48V-Netz durchführen zu können";
CM_ SG_ 1484 DC_MV_Fehlerstatus "aktueller Fehlerstatus des DCDC-Wandler:";
CM_ SG_ 1484 DC_MV_IstModus "aktuelle Betriebsart des DC/DC Wandlers;";
CM_ SG_ 1484 DC_MV_Temperatur "Momentanwert: Temperatur des DC/DC Wandlers";
CM_ SG_ 1484 DC_MV_Tiefsetzen_Notbetrieb "DCDC-Wandler arbeitet im Notbetrieb; ungeregelter Betrieb mit festem Tastverhältnis";
CM_ SG_ 1484 DCDC_MV_03_BZ "4bit Botschaftszähler, wird mit jeder Sendebotschaft inkrementiert";
CM_ SG_ 1484 DCDC_MV_03_CRC "Für MLB:
Berechnung siehe Lastenheft 'Kommunikationsabsicherung für FlexRay und CAN'
Ab MQB und MLBevo:
Berechnung siehe Lastenheft 'End-to-End Kommunikationsabsicherung'

Endwerte siehe Begleitdokument 'S-PDU Kennungsfolgen'";
CM_ SG_ 1484 DCDC_MV_Peakstrom_verfuegbar "Peakstrom verfügbar/nicht verfügbar";
BA_DEF_REL_ BU_SG_REL_  "GenSigTimeoutTime" INT 0 65535;
BA_DEF_ BO_  "DiagRequest" ENUM "No", "Yes";
BA_DEF_ BO_  "DiagResponse" ENUM "No", "Yes";
BA_DEF_ BO_  "DiagState" ENUM "No", "Yes";
BA_DEF_ BO_  "GenMsgChkConstant" HEX 0 4095;
BA_DEF_ BO_  "GenMsgCycleTime" INT 0 65535;
BA_DEF_ BO_  "GenMsgCycleTimeFast" INT 0 65535;
BA_DEF_ BO_  "GenMsgDelayTime" INT 0 100000;
BA_DEF_ BO_  "GenMsgILSupport" ENUM "No", "Yes";
BA_DEF_ BO_  "GenMsgNrOfRepetition" INT 0 100;
BA_DEF_ BO_  "GenMsgPDUConstants" STRING;
BA_DEF_ BO_  "GenMsgSendType" ENUM "Cyclic", "not_used", "not_used", "not_used", "not_used", "not_used", "not_used", "IfActive", "NoMsgSendType";
BA_DEF_ BO_  "GenMsgStartDelayTime" INT 0 100000;
BA_DEF_ BO_  "NmMessage" ENUM "No", "Yes";
BA_DEF_ BO_  "NmhMessage" ENUM "No", "Yes";
BA_DEF_ BO_  "MsgType" ENUM "Application", "NM ", "NMH", "TP2.0", "ISO-TP ", "BAP", "EID", "KS";
BA_DEF_ BO_  "VAGTP20_API" HEX 0 255;
BA_DEF_ BO_  "VAGTP20_DynConnection" ENUM "No", "Yes";
BA_DEF_ BO_  "VAGTP20_DynSetup" ENUM "No", "Yes";
BA_DEF_ BO_  "VAGTP20_StatConnection" ENUM "No", "Yes";
BA_DEF_ SG_  "GenSigActiveRepetitions" INT -2147483648 2147483647;
BA_DEF_ SG_  "GenSigInactiveValue" INT -2147483648 2147483647;
BA_DEF_ SG_  "GenSigSendType" ENUM "Cyclic", "OnWrite", "OnWriteWithRepetition", "OnChange", "OnChangeWithRepetition", "IfActive", "IfActiveWithRepetition", "NoSigSendType", "OnChangeAndIfActive", "OnChangeAndIfActiveWithRepetition";
BA_DEF_ SG_  "GenSigStartValue" INT -2147483648 2147483647;
BA_DEF_ SG_  "NWM-WakeupAllowed" ENUM "No", "Yes";
BA_DEF_ SG_  "GenSigFuncType" ENUM "NoFunction", "MsgCounter", "CRC-8", "XOR", "XOR-2", "DatedBit", "SW-Kl15", "CHK", "Constant", "Protocol", "CRC-8-SAE_J1850";
BA_DEF_ SG_  "GenSigSwitchedByIgnition" ENUM "No", "Yes";
BA_DEF_ SG_  "Fehlerwert" HEX 0 2147483647;
BA_DEF_ SG_  "GenSigMissingSourceValue" HEX 0 2147483647;
BA_DEF_DEF_REL_  "GenSigTimeoutTime" 0;
BA_DEF_DEF_  "DiagRequest" "No";
BA_DEF_DEF_  "DiagResponse" "No";
BA_DEF_DEF_  "DiagState" "No";
BA_DEF_DEF_  "GenMsgChkConstant" 0;
BA_DEF_DEF_  "GenMsgCycleTime" 0;
BA_DEF_DEF_  "GenMsgCycleTimeFast" 0;
BA_DEF_DEF_  "GenMsgDelayTime" 0;
BA_DEF_DEF_  "GenMsgILSupport" "No";
BA_DEF_DEF_  "GenMsgNrOfRepetition" 0;
BA_DEF_DEF_  "GenMsgPDUConstants" "";
BA_DEF_DEF_  "GenMsgSendType" "NoMsgSendType";
BA_DEF_DEF_  "GenMsgStartDelayTime" 0;
BA_DEF_DEF_  "NmMessage" "No";
BA_DEF_DEF_  "NmhMessage" "No";
BA_DEF_DEF_  "MsgType" "Application";
BA_DEF_DEF_  "VAGTP20_API" 0;
BA_DEF_DEF_  "VAGTP20_DynConnection" "No";
BA_DEF_DEF_  "VAGTP20_DynSetup" "No";
BA_DEF_DEF_  "VAGTP20_StatConnection" "No";
BA_DEF_DEF_  "GenSigActiveRepetitions" 0;
BA_DEF_DEF_  "GenSigInactiveValue" 0;
BA_DEF_DEF_  "GenSigSendType" "NoSigSendType";
BA_DEF_DEF_  "GenSigStartValue" 0;
BA_DEF_DEF_  "NWM-WakeupAllowed" "No";
BA_DEF_DEF_  "GenSigFuncType" "NoFunction";
BA_DEF_DEF_  "GenSigSwitchedByIgnition" "Yes";
BA_DEF_DEF_  "Fehlerwert" 0;
BA_DEF_DEF_  "GenSigMissingSourceValue" 0;
BA_ "GenMsgCycleTime" BO_ 871 100;
BA_ "GenMsgILSupport" BO_ 871 1;
BA_ "GenMsgPDUConstants" BO_ 871 "0xa1,0xb0,0xdb,0x69,0x9c,0xef,0xbd,0x08,0xdd,0xcc,0x1b,0x05,0xce,0x20,0xe1,0x48";
BA_ "GenMsgSendType" BO_ 871 0;
BA_ "GenMsgCycleTime" BO_ 1443 500;
BA_ "GenMsgDelayTime" BO_ 1443 20;
BA_ "GenMsgILSupport" BO_ 1443 1;
BA_ "GenMsgPDUConstants" BO_ 1443 "0x0a,0xd3,0xaa,0x89,0x5f,0xc4,0x27,0x2d,0xfb,0xa0,0x47,0x1e,0x28,0xa8,0x44,0x5c";
BA_ "GenMsgSendType" BO_ 1443 0;
BA_ "GenMsgCycleTime" BO_ 2589283412 500;
BA_ "GenMsgILSupport" BO_ 2589283412 1;
BA_ "GenMsgSendType" BO_ 2589283412 0;
BA_ "GenMsgCycleTime" BO_ 2589283608 500;
BA_ "GenMsgILSupport" BO_ 2589283608 1;
BA_ "GenMsgSendType" BO_ 2589283608 0;
BA_ "GenMsgCycleTime" BO_ 2589283606 1000;
BA_ "GenMsgILSupport" BO_ 2589283606 1;
BA_ "GenMsgSendType" BO_ 2589283606 0;
BA_ "GenMsgCycleTime" BO_ 1021 100;
BA_ "GenMsgILSupport" BO_ 1021 1;
BA_ "GenMsgSendType" BO_ 1021 0;
BA_ "GenMsgCycleTime" BO_ 499 100;
BA_ "GenMsgDelayTime" BO_ 499 10;
BA_ "GenMsgILSupport" BO_ 499 1;
BA_ "GenMsgPDUConstants" BO_ 499 "0xc4,0x1e,0x9c,0xae,0x59,0xcc,0x66,0x99,0xe1,0x87,0xe8,0x4c,0x65,0x4a,0xc9,0xde";
BA_ "GenMsgSendType" BO_ 499 0;
BA_ "GenMsgCycleTime" BO_ 504 100;
BA_ "GenMsgDelayTime" BO_ 504 10;
BA_ "GenMsgILSupport" BO_ 504 1;
BA_ "GenMsgSendType" BO_ 504 0;
BA_ "GenMsgCycleTime" BO_ 874 500;
BA_ "GenMsgILSupport" BO_ 874 1;
BA_ "GenMsgSendType" BO_ 874 0;
BA_ "GenMsgCycleTime" BO_ 2463978664 100;
BA_ "GenMsgILSupport" BO_ 2463978664 1;
BA_ "GenMsgSendType" BO_ 2463978664 0;
BA_ "GenMsgCycleTime" BO_ 2463978720 100;
BA_ "GenMsgILSupport" BO_ 2463978720 1;
BA_ "GenMsgPDUConstants" BO_ 2463978720 "0xd0,0x4d,0x22,0xae,0x8a,0x67,0xf4,0x35,0x15,0x2a,0xb8,0x4e,0xcc,0x07,0xad,0xa2";
BA_ "GenMsgSendType" BO_ 2463978720 0;
BA_ "MsgType" BO_ 2617236992 6;
BA_ "MsgType" BO_ 2617236993 6;
BA_ "MsgType" BO_ 2617130752 6;
BA_ "MsgType" BO_ 2617130753 6;
BA_ "MsgType" BO_ 2617194240 6;
BA_ "MsgType" BO_ 2617194241 6;
BA_ "MsgType" BO_ 2617124352 6;
BA_ "MsgType" BO_ 2617124353 6;
BA_ "GenMsgCycleTime" BO_ 901 1000;
BA_ "GenMsgDelayTime" BO_ 901 50;
BA_ "GenMsgILSupport" BO_ 901 1;
BA_ "GenMsgSendType" BO_ 901 0;
BA_ "GenMsgStartDelayTime" BO_ 901 50;
BA_ "GenMsgCycleTime" BO_ 1022 1000;
BA_ "GenMsgDelayTime" BO_ 1022 50;
BA_ "GenMsgILSupport" BO_ 1022 1;
BA_ "GenMsgSendType" BO_ 1022 0;
BA_ "GenMsgStartDelayTime" BO_ 1022 50;
BA_ "GenMsgCycleTime" BO_ 686 50;
BA_ "GenMsgILSupport" BO_ 686 1;
BA_ "GenMsgPDUConstants" BO_ 686 "0x83,0x50,0xbf,0x5d,0x67,0x68,0x2f,0x4b,0x32,0x4e,0x1a,0xba,0xc4,0x39,0xf5,0xdb";
BA_ "GenMsgSendType" BO_ 686 0;
BA_ "GenMsgCycleTime" BO_ 1012 100;
BA_ "GenMsgILSupport" BO_ 1012 1;
BA_ "GenMsgPDUConstants" BO_ 1012 "0x26,0xe4,0xc5,0x16,0xcf,0x20,0x65,0xad,0xed,0x6a,0xa3,0x49,0x02,0x6b,0xb2,0xbd";
BA_ "GenMsgSendType" BO_ 1012 0;
BA_ "GenMsgCycleTime" BO_ 1485 500;
BA_ "GenMsgDelayTime" BO_ 1485 50;
BA_ "GenMsgILSupport" BO_ 1485 1;
BA_ "GenMsgPDUConstants" BO_ 1485 "0x93,0x04,0x18,0x69,0xce,0x8f,0xb1,0x53,0x40,0x2d,0xe4,0xca,0x90,0x25,0x79,0x8c";
BA_ "GenMsgSendType" BO_ 1485 0;
BA_ "GenMsgCycleTime" BO_ 2589283653 500;
BA_ "GenMsgDelayTime" BO_ 2589283653 50;
BA_ "GenMsgILSupport" BO_ 2589283653 1;
BA_ "GenMsgPDUConstants" BO_ 2589283653 "0xc2,0xe1,0xd3,0x20,0x42,0xce,0x68,0x05,0xa9,0x1b,0xa3,0xcc,0xe2,0xdd,0x14,0x08";
BA_ "GenMsgSendType" BO_ 2589283653 0;
BA_ "GenMsgCycleTime" BO_ 2463978669 100;
BA_ "GenMsgILSupport" BO_ 2463978669 1;
BA_ "GenMsgPDUConstants" BO_ 2463978669 "0x02,0xf4,0x6f,0x42,0x4a,0x62,0xcd,0x1b,0xb4,0xa0,0x16,0x14,0xe8,0x0a,0x71,0xef";
BA_ "GenMsgSendType" BO_ 2463978669 0;
BA_ "GenMsgCycleTime" BO_ 2589283662 1000;
BA_ "GenMsgILSupport" BO_ 2589283662 1;
BA_ "GenMsgSendType" BO_ 2589283662 0;
BA_ "GenMsgCycleTime" BO_ 685 50;
BA_ "GenMsgILSupport" BO_ 685 1;
BA_ "GenMsgPDUConstants" BO_ 685 "0x7b,0xed,0xa6,0xd1,0x57,0x4b,0x69,0x9f,0x13,0x82,0x9e,0x19,0x3e,0x08,0x5e,0x78";
BA_ "GenMsgSendType" BO_ 685 0;
BA_ "GenMsgCycleTime" BO_ 1018 100;
BA_ "GenMsgILSupport" BO_ 1018 1;
BA_ "GenMsgPDUConstants" BO_ 1018 "0x26,0xe3,0x43,0x0a,0x6d,0x29,0x22,0xd3,0x52,0x96,0xe4,0xaa,0xe8,0xeb,0xa9,0x89";
BA_ "GenMsgSendType" BO_ 1018 0;
BA_ "GenMsgCycleTime" BO_ 1484 500;
BA_ "GenMsgDelayTime" BO_ 1484 50;
BA_ "GenMsgILSupport" BO_ 1484 1;
BA_ "GenMsgPDUConstants" BO_ 1484 "0x60,0x76,0x27,0x02,0x3a,0xa8,0x32,0x51,0x8b,0x23,0x1c,0xf4,0xf0,0x97,0x5b,0x07";
BA_ "GenMsgSendType" BO_ 1484 0;
BA_ "MsgType" BO_ 2617015040 6;
BA_ "MsgType" BO_ 2617015295 6;
BA_ "MsgType" BO_ 2617078528 6;
BA_ "MsgType" BO_ 2617078783 6;
BA_ "MsgType" BO_ 2617041664 6;
BA_ "MsgType" BO_ 2617041919 6;
BA_ "MsgType" BO_ 2617235968 6;
BA_ "MsgType" BO_ 2617236223 6;
BA_ "MsgType" BO_ 2617129728 6;
BA_ "MsgType" BO_ 2617129729 6;
BA_ "MsgType" BO_ 2617129983 6;
BA_ "MsgType" BO_ 2617096960 6;
BA_ "MsgType" BO_ 2617097215 6;
BA_ "MsgType" BO_ 2617117184 6;
BA_ "MsgType" BO_ 2617117439 6;
BA_ "MsgType" BO_ 2617193216 6;
BA_ "MsgType" BO_ 2617193217 6;
BA_ "MsgType" BO_ 2617193471 6;
BA_ "MsgType" BO_ 2617123328 6;
BA_ "MsgType" BO_ 2617123329 6;
BA_ "MsgType" BO_ 2617123583 6;
BA_ "MsgType" BO_ 2617238016 6;
BA_ "MsgType" BO_ 2617238271 6;
BA_ "MsgType" BO_ 2617119232 6;
BA_ "GenMsgCycleTime" BO_ 2617119233 2000;
BA_ "GenMsgILSupport" BO_ 2617119233 1;
BA_ "GenMsgSendType" BO_ 2617119233 0;
BA_ "GenMsgCycleTime" BO_ 2617119234 2000;
BA_ "GenMsgILSupport" BO_ 2617119234 1;
BA_ "GenMsgSendType" BO_ 2617119234 0;
BA_ "GenMsgCycleTime" BO_ 2617119235 100;
BA_ "GenMsgILSupport" BO_ 2617119235 1;
BA_ "GenMsgSendType" BO_ 2617119235 0;
BA_ "GenMsgCycleTime" BO_ 2617119236 2000;
BA_ "GenMsgILSupport" BO_ 2617119236 1;
BA_ "GenMsgSendType" BO_ 2617119236 0;
BA_ "GenMsgCycleTime" BO_ 2617119237 2000;
BA_ "GenMsgILSupport" BO_ 2617119237 1;
BA_ "GenMsgSendType" BO_ 2617119237 0;
BA_ "GenMsgCycleTime" BO_ 2617119238 1000;
BA_ "GenMsgILSupport" BO_ 2617119238 1;
BA_ "GenMsgSendType" BO_ 2617119238 0;
BA_ "GenMsgCycleTime" BO_ 2617119239 2000;
BA_ "GenMsgILSupport" BO_ 2617119239 1;
BA_ "GenMsgSendType" BO_ 2617119239 0;
BA_ "GenMsgCycleTime" BO_ 2617119240 2000;
BA_ "GenMsgILSupport" BO_ 2617119240 1;
BA_ "GenMsgSendType" BO_ 2617119240 0;
BA_ "GenMsgCycleTime" BO_ 2617119241 2000;
BA_ "GenMsgILSupport" BO_ 2617119241 1;
BA_ "GenMsgSendType" BO_ 2617119241 0;
BA_ "GenMsgCycleTime" BO_ 2617119242 100;
BA_ "GenMsgILSupport" BO_ 2617119242 1;
BA_ "GenMsgSendType" BO_ 2617119242 0;
BA_ "GenMsgCycleTime" BO_ 2617119243 100;
BA_ "GenMsgILSupport" BO_ 2617119243 1;
BA_ "GenMsgSendType" BO_ 2617119243 0;
BA_ "GenMsgCycleTime" BO_ 2617119244 2000;
BA_ "GenMsgILSupport" BO_ 2617119244 1;
BA_ "GenMsgSendType" BO_ 2617119244 0;
BA_ "GenMsgCycleTime" BO_ 2617119245 2000;
BA_ "GenMsgILSupport" BO_ 2617119245 1;
BA_ "GenMsgSendType" BO_ 2617119245 0;
BA_ "GenMsgCycleTime" BO_ 2617119246 2000;
BA_ "GenMsgILSupport" BO_ 2617119246 1;
BA_ "GenMsgSendType" BO_ 2617119246 0;
BA_ "GenMsgCycleTime" BO_ 2617119247 2000;
BA_ "GenMsgILSupport" BO_ 2617119247 1;
BA_ "GenMsgSendType" BO_ 2617119247 0;
BA_ "GenMsgCycleTime" BO_ 2617119248 2000;
BA_ "GenMsgILSupport" BO_ 2617119248 1;
BA_ "GenMsgSendType" BO_ 2617119248 0;
BA_ "GenMsgCycleTime" BO_ 2617119249 2000;
BA_ "GenMsgILSupport" BO_ 2617119249 1;
BA_ "GenMsgSendType" BO_ 2617119249 0;
BA_ "GenMsgCycleTime" BO_ 2617119250 2000;
BA_ "GenMsgILSupport" BO_ 2617119250 1;
BA_ "GenMsgSendType" BO_ 2617119250 0;
BA_ "GenMsgCycleTime" BO_ 2617119251 2000;
BA_ "GenMsgILSupport" BO_ 2617119251 1;
BA_ "GenMsgSendType" BO_ 2617119251 0;
BA_ "GenMsgCycleTime" BO_ 2617119252 100;
BA_ "GenMsgILSupport" BO_ 2617119252 1;
BA_ "GenMsgSendType" BO_ 2617119252 0;
BA_ "GenMsgCycleTime" BO_ 2617119253 100;
BA_ "GenMsgILSupport" BO_ 2617119253 1;
BA_ "GenMsgSendType" BO_ 2617119253 0;
BA_ "GenMsgCycleTime" BO_ 2617119254 2000;
BA_ "GenMsgILSupport" BO_ 2617119254 1;
BA_ "GenMsgSendType" BO_ 2617119254 0;
BA_ "GenMsgCycleTime" BO_ 2617119255 2000;
BA_ "GenMsgILSupport" BO_ 2617119255 1;
BA_ "GenMsgSendType" BO_ 2617119255 0;
BA_ "GenMsgCycleTime" BO_ 2617119256 2000;
BA_ "GenMsgILSupport" BO_ 2617119256 1;
BA_ "GenMsgSendType" BO_ 2617119256 0;
BA_ "GenMsgCycleTime" BO_ 2617119257 2000;
BA_ "GenMsgILSupport" BO_ 2617119257 1;
BA_ "GenMsgSendType" BO_ 2617119257 0;
BA_ "GenMsgCycleTime" BO_ 2617119258 2000;
BA_ "GenMsgILSupport" BO_ 2617119258 1;
BA_ "GenMsgSendType" BO_ 2617119258 0;
BA_ "GenMsgCycleTime" BO_ 2617119259 2000;
BA_ "GenMsgILSupport" BO_ 2617119259 1;
BA_ "GenMsgSendType" BO_ 2617119259 0;
BA_ "GenMsgCycleTime" BO_ 2617119260 100;
BA_ "GenMsgILSupport" BO_ 2617119260 1;
BA_ "GenMsgSendType" BO_ 2617119260 0;
BA_ "GenMsgCycleTime" BO_ 2617119261 2000;
BA_ "GenMsgILSupport" BO_ 2617119261 1;
BA_ "GenMsgSendType" BO_ 2617119261 0;
BA_ "GenMsgCycleTime" BO_ 2617119262 100;
BA_ "GenMsgILSupport" BO_ 2617119262 1;
BA_ "GenMsgSendType" BO_ 2617119262 0;
BA_ "GenMsgCycleTime" BO_ 2617119263 2000;
BA_ "GenMsgILSupport" BO_ 2617119263 1;
BA_ "GenMsgSendType" BO_ 2617119263 0;
BA_ "GenMsgCycleTime" BO_ 2617119264 100;
BA_ "GenMsgILSupport" BO_ 2617119264 1;
BA_ "GenMsgSendType" BO_ 2617119264 0;
BA_ "GenMsgCycleTime" BO_ 2617119265 100;
BA_ "GenMsgILSupport" BO_ 2617119265 1;
BA_ "GenMsgSendType" BO_ 2617119265 0;
BA_ "GenSigSendType" SG_ 871 BMS_MV_03_BZ 0;
BA_ "GenSigFuncType" SG_ 871 BMS_MV_03_BZ 1;
BA_ "GenSigSwitchedByIgnition" SG_ 871 BMS_MV_03_BZ 0;
BA_ "GenSigSendType" SG_ 871 BMS_MV_03_CRC 0;
BA_ "GenSigFuncType" SG_ 871 BMS_MV_03_CRC 2;
BA_ "GenSigSwitchedByIgnition" SG_ 871 BMS_MV_03_CRC 0;
BA_ "GenSigSendType" SG_ 871 BMS_MV_Leistungsreduzierung 0;
BA_ "GenSigSwitchedByIgnition" SG_ 871 BMS_MV_Leistungsreduzierung 0;
BA_ "GenSigSendType" SG_ 871 BMS_MV_Max_LadeSpannung 0;
BA_ "GenSigStartValue" SG_ 871 BMS_MV_Max_LadeSpannung 254;
BA_ "GenSigSwitchedByIgnition" SG_ 871 BMS_MV_Max_LadeSpannung 0;
BA_ "Fehlerwert" SG_ 871 BMS_MV_Max_LadeSpannung 255;
BA_ "GenSigSendType" SG_ 871 BMS_MV_MaxPred_EntladeStrom 0;
BA_ "GenSigStartValue" SG_ 871 BMS_MV_MaxPred_EntladeStrom 2046;
BA_ "GenSigSwitchedByIgnition" SG_ 871 BMS_MV_MaxPred_EntladeStrom 0;
BA_ "Fehlerwert" SG_ 871 BMS_MV_MaxPred_EntladeStrom 2047;
BA_ "GenSigSendType" SG_ 871 BMS_MV_MaxPred_LadeStrom 0;
BA_ "GenSigStartValue" SG_ 871 BMS_MV_MaxPred_LadeStrom 2046;
BA_ "GenSigSwitchedByIgnition" SG_ 871 BMS_MV_MaxPred_LadeStrom 0;
BA_ "Fehlerwert" SG_ 871 BMS_MV_MaxPred_LadeStrom 2047;
BA_ "GenSigSendType" SG_ 871 BMS_MV_MinPred_EntladeSpannung 0;
BA_ "GenSigStartValue" SG_ 871 BMS_MV_MinPred_EntladeSpannung 254;
BA_ "GenSigSwitchedByIgnition" SG_ 871 BMS_MV_MinPred_EntladeSpannung 0;
BA_ "GenSigSendType" SG_ 871 BMS_MV_MinPred_LadeSpannung 0;
BA_ "GenSigStartValue" SG_ 871 BMS_MV_MinPred_LadeSpannung 254;
BA_ "GenSigSwitchedByIgnition" SG_ 871 BMS_MV_MinPred_LadeSpannung 0;
BA_ "GenSigSendType" SG_ 1443 BMS_MV_04_BZ 0;
BA_ "GenSigFuncType" SG_ 1443 BMS_MV_04_BZ 1;
BA_ "GenSigSwitchedByIgnition" SG_ 1443 BMS_MV_04_BZ 0;
BA_ "GenSigSendType" SG_ 1443 BMS_MV_04_CRC 0;
BA_ "GenSigFuncType" SG_ 1443 BMS_MV_04_CRC 2;
BA_ "GenSigSwitchedByIgnition" SG_ 1443 BMS_MV_04_CRC 0;
BA_ "GenSigSendType" SG_ 1443 BMS_MV_FehlerStatus 3;
BA_ "GenSigStartValue" SG_ 1443 BMS_MV_FehlerStatus 7;
BA_ "GenSigSwitchedByIgnition" SG_ 1443 BMS_MV_FehlerStatus 0;
BA_ "GenSigSendType" SG_ 1443 BMS_MV_IstModus 1;
BA_ "GenSigStartValue" SG_ 1443 BMS_MV_IstModus 7;
BA_ "GenSigSwitchedByIgnition" SG_ 1443 BMS_MV_IstModus 0;
BA_ "GenSigSendType" SG_ 1443 BMS_MV_OBD_Lampe_Anf 0;
BA_ "GenSigSwitchedByIgnition" SG_ 1443 BMS_MV_OBD_Lampe_Anf 0;
BA_ "GenSigSendType" SG_ 2589283412 BMS_MV_IstRuecklaufTemperatur 0;
BA_ "GenSigStartValue" SG_ 2589283412 BMS_MV_IstRuecklaufTemperatur 254;
BA_ "GenSigSwitchedByIgnition" SG_ 2589283412 BMS_MV_IstRuecklaufTemperatur 0;
BA_ "Fehlerwert" SG_ 2589283412 BMS_MV_IstRuecklaufTemperatur 255;
BA_ "GenSigSendType" SG_ 2589283412 BMS_MV_IstVorlaufTemperatur 0;
BA_ "GenSigStartValue" SG_ 2589283412 BMS_MV_IstVorlaufTemperatur 254;
BA_ "GenSigSwitchedByIgnition" SG_ 2589283412 BMS_MV_IstVorlaufTemperatur 0;
BA_ "Fehlerwert" SG_ 2589283412 BMS_MV_IstVorlaufTemperatur 255;
BA_ "GenSigSendType" SG_ 2589283412 BMS_MV_Soll_PWM_Pumpe 0;
BA_ "GenSigStartValue" SG_ 2589283412 BMS_MV_Soll_PWM_Pumpe 15;
BA_ "GenSigSwitchedByIgnition" SG_ 2589283412 BMS_MV_Soll_PWM_Pumpe 0;
BA_ "GenSigSendType" SG_ 2589283412 BMS_MV_SollVolumenstrom 0;
BA_ "GenSigStartValue" SG_ 2589283412 BMS_MV_SollVolumenstrom 62;
BA_ "GenSigSwitchedByIgnition" SG_ 2589283412 BMS_MV_SollVolumenstrom 0;
BA_ "Fehlerwert" SG_ 2589283412 BMS_MV_SollVolumenstrom 63;
BA_ "GenSigSendType" SG_ 2589283412 BMS_MV_SollVorlauftemperatur 0;
BA_ "GenSigStartValue" SG_ 2589283412 BMS_MV_SollVorlauftemperatur 254;
BA_ "GenSigSwitchedByIgnition" SG_ 2589283412 BMS_MV_SollVorlauftemperatur 0;
BA_ "Fehlerwert" SG_ 2589283412 BMS_MV_SollVorlauftemperatur 255;
BA_ "GenSigSendType" SG_ 2589283412 BMS_MV_Speichertechnologie 0;
BA_ "GenSigSwitchedByIgnition" SG_ 2589283412 BMS_MV_Speichertechnologie 0;
BA_ "GenSigSendType" SG_ 2589283412 BMS_MV_Temp_Epsilon 0;
BA_ "GenSigSwitchedByIgnition" SG_ 2589283412 BMS_MV_Temp_Epsilon 0;
BA_ "GenSigSendType" SG_ 2589283412 BMS_MV_Temperatur 0;
BA_ "GenSigStartValue" SG_ 2589283412 BMS_MV_Temperatur 254;
BA_ "GenSigSwitchedByIgnition" SG_ 2589283412 BMS_MV_Temperatur 0;
BA_ "Fehlerwert" SG_ 2589283412 BMS_MV_Temperatur 255;
BA_ "GenSigSendType" SG_ 2589283412 BMS_MV_Temperierung_Anf 0;
BA_ "GenSigStartValue" SG_ 2589283412 BMS_MV_Temperierung_Anf 3;
BA_ "GenSigSwitchedByIgnition" SG_ 2589283412 BMS_MV_Temperierung_Anf 0;
BA_ "GenSigSendType" SG_ 2589283608 BMS_MV_Energieinhalt 0;
BA_ "GenSigStartValue" SG_ 2589283608 BMS_MV_Energieinhalt 2046;
BA_ "GenSigSwitchedByIgnition" SG_ 2589283608 BMS_MV_Energieinhalt 0;
BA_ "Fehlerwert" SG_ 2589283608 BMS_MV_Energieinhalt 2047;
BA_ "GenSigSendType" SG_ 2589283608 BMS_MV_MaxEnergieinhalt 0;
BA_ "GenSigStartValue" SG_ 2589283608 BMS_MV_MaxEnergieinhalt 2046;
BA_ "GenSigSwitchedByIgnition" SG_ 2589283608 BMS_MV_MaxEnergieinhalt 0;
BA_ "Fehlerwert" SG_ 2589283608 BMS_MV_MaxEnergieinhalt 2047;
BA_ "GenSigSendType" SG_ 2589283606 BMS_MV_max_Grenz_SOC 0;
BA_ "GenSigStartValue" SG_ 2589283606 BMS_MV_max_Grenz_SOC 31;
BA_ "GenSigSwitchedByIgnition" SG_ 2589283606 BMS_MV_max_Grenz_SOC 0;
BA_ "GenSigSendType" SG_ 2589283606 BMS_MV_SOC_Kaltstart 0;
BA_ "GenSigStartValue" SG_ 2589283606 BMS_MV_SOC_Kaltstart 2046;
BA_ "GenSigSwitchedByIgnition" SG_ 2589283606 BMS_MV_SOC_Kaltstart 0;
BA_ "Fehlerwert" SG_ 2589283606 BMS_MV_SOC_Kaltstart 2047;
BA_ "GenSigSendType" SG_ 1021 BMS_MV_Pred_Entladeperformance 0;
BA_ "GenSigStartValue" SG_ 1021 BMS_MV_Pred_Entladeperformance 126;
BA_ "GenSigSwitchedByIgnition" SG_ 1021 BMS_MV_Pred_Entladeperformance 0;
BA_ "Fehlerwert" SG_ 1021 BMS_MV_Pred_Entladeperformance 127;
BA_ "GenSigSendType" SG_ 1021 BMS_MV_Pred_Ladeperformance 0;
BA_ "GenSigStartValue" SG_ 1021 BMS_MV_Pred_Ladeperformance 126;
BA_ "GenSigSwitchedByIgnition" SG_ 1021 BMS_MV_Pred_Ladeperformance 0;
BA_ "Fehlerwert" SG_ 1021 BMS_MV_Pred_Ladeperformance 127;
BA_ "GenSigSendType" SG_ 499 BMS_NV_01_BZ 0;
BA_ "GenSigFuncType" SG_ 499 BMS_NV_01_BZ 1;
BA_ "GenSigSwitchedByIgnition" SG_ 499 BMS_NV_01_BZ 0;
BA_ "GenSigSendType" SG_ 499 BMS_NV_01_CRC 0;
BA_ "GenSigFuncType" SG_ 499 BMS_NV_01_CRC 2;
BA_ "GenSigSwitchedByIgnition" SG_ 499 BMS_NV_01_CRC 0;
BA_ "GenSigSendType" SG_ 499 BMS_NV_BatterieAb 3;
BA_ "GenSigSwitchedByIgnition" SG_ 499 BMS_NV_BatterieAb 0;
BA_ "GenSigSendType" SG_ 499 BMS_NV_FMAus_Info 3;
BA_ "GenSigStartValue" SG_ 499 BMS_NV_FMAus_Info 1;
BA_ "GenSigSwitchedByIgnition" SG_ 499 BMS_NV_FMAus_Info 0;
BA_ "GenSigSendType" SG_ 499 BMS_NV_IstModus 3;
BA_ "GenSigStartValue" SG_ 499 BMS_NV_IstModus 3;
BA_ "GenSigSwitchedByIgnition" SG_ 499 BMS_NV_IstModus 0;
BA_ "Fehlerwert" SG_ 499 BMS_NV_IstModus 2;
BA_ "GenSigSendType" SG_ 499 BMS_NV_IstSpannung 0;
BA_ "GenSigStartValue" SG_ 499 BMS_NV_IstSpannung 16382;
BA_ "GenSigSwitchedByIgnition" SG_ 499 BMS_NV_IstSpannung 0;
BA_ "Fehlerwert" SG_ 499 BMS_NV_IstSpannung 16383;
BA_ "GenSigSendType" SG_ 499 BMS_NV_IstStrom 0;
BA_ "GenSigStartValue" SG_ 499 BMS_NV_IstStrom 262142;
BA_ "GenSigSwitchedByIgnition" SG_ 499 BMS_NV_IstStrom 0;
BA_ "Fehlerwert" SG_ 499 BMS_NV_IstStrom 262143;
BA_ "GenSigSendType" SG_ 499 BMS_NV_StSt_Nutzbare_Ladung 0;
BA_ "GenSigStartValue" SG_ 499 BMS_NV_StSt_Nutzbare_Ladung 254;
BA_ "GenSigSwitchedByIgnition" SG_ 499 BMS_NV_StSt_Nutzbare_Ladung 0;
BA_ "Fehlerwert" SG_ 499 BMS_NV_StSt_Nutzbare_Ladung 255;
BA_ "GenSigSendType" SG_ 499 BMS_NV_TE_Status 0;
BA_ "GenSigSwitchedByIgnition" SG_ 499 BMS_NV_TE_Status 0;
BA_ "GenSigSendType" SG_ 504 BMS_NV_Fehlerstatus 3;
BA_ "GenSigStartValue" SG_ 504 BMS_NV_Fehlerstatus 7;
BA_ "GenSigSwitchedByIgnition" SG_ 504 BMS_NV_Fehlerstatus 0;
BA_ "GenSigSendType" SG_ 504 BMS_NV_IMaxStart 0;
BA_ "GenSigStartValue" SG_ 504 BMS_NV_IMaxStart 254;
BA_ "GenSigSwitchedByIgnition" SG_ 504 BMS_NV_IMaxStart 0;
BA_ "Fehlerwert" SG_ 504 BMS_NV_IMaxStart 255;
BA_ "GenSigSendType" SG_ 504 BMS_NV_Qe_LI_Inhalt 0;
BA_ "GenSigStartValue" SG_ 504 BMS_NV_Qe_LI_Inhalt 4094;
BA_ "GenSigSwitchedByIgnition" SG_ 504 BMS_NV_Qe_LI_Inhalt 0;
BA_ "Fehlerwert" SG_ 504 BMS_NV_Qe_LI_Inhalt 4095;
BA_ "GenSigSendType" SG_ 504 BMS_NV_Ri_Batterie 0;
BA_ "GenSigStartValue" SG_ 504 BMS_NV_Ri_Batterie 254;
BA_ "GenSigSwitchedByIgnition" SG_ 504 BMS_NV_Ri_Batterie 0;
BA_ "Fehlerwert" SG_ 504 BMS_NV_Ri_Batterie 255;
BA_ "GenSigSendType" SG_ 504 BMS_NV_SOC 0;
BA_ "GenSigStartValue" SG_ 504 BMS_NV_SOC 254;
BA_ "GenSigSwitchedByIgnition" SG_ 504 BMS_NV_SOC 0;
BA_ "Fehlerwert" SG_ 504 BMS_NV_SOC 255;
BA_ "GenSigSendType" SG_ 504 BMS_NV_UMinStart 0;
BA_ "GenSigStartValue" SG_ 504 BMS_NV_UMinStart 254;
BA_ "GenSigSwitchedByIgnition" SG_ 504 BMS_NV_UMinStart 0;
BA_ "Fehlerwert" SG_ 504 BMS_NV_UMinStart 255;
BA_ "GenSigSendType" SG_ 874 BMS_NV_Diagnose_Anf 0;
BA_ "GenSigStartValue" SG_ 874 BMS_NV_Diagnose_Anf 7;
BA_ "GenSigSwitchedByIgnition" SG_ 874 BMS_NV_Diagnose_Anf 0;
BA_ "GenSigSendType" SG_ 874 BMS_NV_Kapazitaet_akt 0;
BA_ "GenSigStartValue" SG_ 874 BMS_NV_Kapazitaet_akt 510;
BA_ "GenSigSwitchedByIgnition" SG_ 874 BMS_NV_Kapazitaet_akt 0;
BA_ "Fehlerwert" SG_ 874 BMS_NV_Kapazitaet_akt 511;
BA_ "GenSigSendType" SG_ 874 BMS_NV_Max_EntladeStrom 0;
BA_ "GenSigStartValue" SG_ 874 BMS_NV_Max_EntladeStrom 1022;
BA_ "GenSigSwitchedByIgnition" SG_ 874 BMS_NV_Max_EntladeStrom 0;
BA_ "Fehlerwert" SG_ 874 BMS_NV_Max_EntladeStrom 1023;
BA_ "GenSigSendType" SG_ 874 BMS_NV_Max_LadeSpannung 0;
BA_ "GenSigStartValue" SG_ 874 BMS_NV_Max_LadeSpannung 62;
BA_ "GenSigSwitchedByIgnition" SG_ 874 BMS_NV_Max_LadeSpannung 0;
BA_ "Fehlerwert" SG_ 874 BMS_NV_Max_LadeSpannung 63;
BA_ "GenSigSendType" SG_ 874 BMS_NV_Max_LadeStrom 0;
BA_ "GenSigStartValue" SG_ 874 BMS_NV_Max_LadeStrom 1022;
BA_ "GenSigSwitchedByIgnition" SG_ 874 BMS_NV_Max_LadeStrom 0;
BA_ "Fehlerwert" SG_ 874 BMS_NV_Max_LadeStrom 1023;
BA_ "GenSigSendType" SG_ 874 BMS_NV_Min_EntladeSpannung 0;
BA_ "GenSigStartValue" SG_ 874 BMS_NV_Min_EntladeSpannung 62;
BA_ "GenSigSwitchedByIgnition" SG_ 874 BMS_NV_Min_EntladeSpannung 0;
BA_ "Fehlerwert" SG_ 874 BMS_NV_Min_EntladeSpannung 63;
BA_ "GenSigSendType" SG_ 874 BMS_NV_Temperatur 0;
BA_ "GenSigStartValue" SG_ 874 BMS_NV_Temperatur 254;
BA_ "GenSigSwitchedByIgnition" SG_ 874 BMS_NV_Temperatur 0;
BA_ "Fehlerwert" SG_ 874 BMS_NV_Temperatur 255;
BA_ "GenSigSendType" SG_ 2463978664 BMS_NV_Polspannung 0;
BA_ "GenSigStartValue" SG_ 2463978664 BMS_NV_Polspannung 510;
BA_ "GenSigSwitchedByIgnition" SG_ 2463978664 BMS_NV_Polspannung 0;
BA_ "Fehlerwert" SG_ 2463978664 BMS_NV_Polspannung 511;
BA_ "GenSigSendType" SG_ 2463978720 BMS_NV_05_BZ 0;
BA_ "GenSigFuncType" SG_ 2463978720 BMS_NV_05_BZ 1;
BA_ "GenSigSwitchedByIgnition" SG_ 2463978720 BMS_NV_05_BZ 0;
BA_ "GenSigSendType" SG_ 2463978720 BMS_NV_05_CRC 0;
BA_ "GenSigFuncType" SG_ 2463978720 BMS_NV_05_CRC 2;
BA_ "GenSigSwitchedByIgnition" SG_ 2463978720 BMS_NV_05_CRC 0;
BA_ "GenSigSendType" SG_ 2463978720 BMS_NV_IstDyn_EntladeStrom 0;
BA_ "GenSigStartValue" SG_ 2463978720 BMS_NV_IstDyn_EntladeStrom 2046;
BA_ "GenSigSwitchedByIgnition" SG_ 2463978720 BMS_NV_IstDyn_EntladeStrom 0;
BA_ "Fehlerwert" SG_ 2463978720 BMS_NV_IstDyn_EntladeStrom 2047;
BA_ "GenSigSendType" SG_ 2463978720 BMS_NV_IstPred_EntladeStrom 0;
BA_ "GenSigStartValue" SG_ 2463978720 BMS_NV_IstPred_EntladeStrom 2046;
BA_ "GenSigSwitchedByIgnition" SG_ 2463978720 BMS_NV_IstPred_EntladeStrom 0;
BA_ "Fehlerwert" SG_ 2463978720 BMS_NV_IstPred_EntladeStrom 2047;
BA_ "GenSigSendType" SG_ 2463978720 BMS_NV_SollDyn_EntladeSpannung 0;
BA_ "GenSigStartValue" SG_ 2463978720 BMS_NV_SollDyn_EntladeSpannung 254;
BA_ "GenSigSwitchedByIgnition" SG_ 2463978720 BMS_NV_SollDyn_EntladeSpannung 0;
BA_ "Fehlerwert" SG_ 2463978720 BMS_NV_SollDyn_EntladeSpannung 255;
BA_ "GenSigSendType" SG_ 2463978720 BMS_NV_SollPred_EntladeSpannung 0;
BA_ "GenSigStartValue" SG_ 2463978720 BMS_NV_SollPred_EntladeSpannung 254;
BA_ "GenSigSwitchedByIgnition" SG_ 2463978720 BMS_NV_SollPred_EntladeSpannung 0;
BA_ "Fehlerwert" SG_ 2463978720 BMS_NV_SollPred_EntladeSpannung 255;
BA_ "GenSigFuncType" SG_ 2617236992 CCP_BMS_CRO_01_Data 9;
BA_ "GenSigSwitchedByIgnition" SG_ 2617236992 CCP_BMS_CRO_01_Data 0;
BA_ "GenSigFuncType" SG_ 2617236993 CCP_BMS_DTO_01_Data 9;
BA_ "GenSigSwitchedByIgnition" SG_ 2617236993 CCP_BMS_DTO_01_Data 0;
BA_ "GenSigFuncType" SG_ 2617130752 CCP_DCDC_HV_02_CRO_01_Data 9;
BA_ "GenSigSwitchedByIgnition" SG_ 2617130752 CCP_DCDC_HV_02_CRO_01_Data 0;
BA_ "GenSigFuncType" SG_ 2617130753 CCP_DCDC_HV_02_DTO_01_Data 9;
BA_ "GenSigSwitchedByIgnition" SG_ 2617130753 CCP_DCDC_HV_02_DTO_01_Data 0;
BA_ "GenSigFuncType" SG_ 2617194240 CCP_Ladegeraet_2_CRO_01_Data 9;
BA_ "GenSigSwitchedByIgnition" SG_ 2617194240 CCP_Ladegeraet_2_CRO_01_Data 0;
BA_ "GenSigFuncType" SG_ 2617194241 CCP_Ladegeraet_2_DTO_01_Data 9;
BA_ "GenSigSwitchedByIgnition" SG_ 2617194241 CCP_Ladegeraet_2_DTO_01_Data 0;
BA_ "GenSigFuncType" SG_ 2617124352 CCP_Ladegeraet_CRO_01_Data 9;
BA_ "GenSigSwitchedByIgnition" SG_ 2617124352 CCP_Ladegeraet_CRO_01_Data 0;
BA_ "GenSigFuncType" SG_ 2617124353 CCP_Ladegeraet_DTO_01_Data 9;
BA_ "GenSigSwitchedByIgnition" SG_ 2617124353 CCP_Ladegeraet_DTO_01_Data 0;
BA_ "GenSigSendType" SG_ 901 CHA_Fahrer_Umschaltung 3;
BA_ "GenSigSwitchedByIgnition" SG_ 901 CHA_Fahrer_Umschaltung 0;
BA_ "GenSigSendType" SG_ 901 CHA_Fahrer_Umschaltung_BMA 3;
BA_ "GenSigSwitchedByIgnition" SG_ 901 CHA_Fahrer_Umschaltung_BMA 0;
BA_ "GenSigSendType" SG_ 901 CHA_Ziel_FahrPr_ACC 3;
BA_ "GenSigSwitchedByIgnition" SG_ 901 CHA_Ziel_FahrPr_ACC 0;
BA_ "GenSigSendType" SG_ 901 CHA_Ziel_FahrPr_AFS 3;
BA_ "GenSigSwitchedByIgnition" SG_ 901 CHA_Ziel_FahrPr_AFS 0;
BA_ "GenSigSendType" SG_ 901 CHA_Ziel_FahrPr_AGA 3;
BA_ "GenSigSwitchedByIgnition" SG_ 901 CHA_Ziel_FahrPr_AGA 0;
BA_ "GenSigSendType" SG_ 901 CHA_Ziel_FahrPr_ALR 3;
BA_ "GenSigSwitchedByIgnition" SG_ 901 CHA_Ziel_FahrPr_ALR 0;
BA_ "GenSigSendType" SG_ 901 CHA_Ziel_FahrPr_DR 3;
BA_ "GenSigSwitchedByIgnition" SG_ 901 CHA_Ziel_FahrPr_DR 0;
BA_ "GenSigSendType" SG_ 901 CHA_Ziel_FahrPr_EPS 3;
BA_ "GenSigSwitchedByIgnition" SG_ 901 CHA_Ziel_FahrPr_EPS 0;
BA_ "GenSigSendType" SG_ 901 CHA_Ziel_FahrPr_ESP 3;
BA_ "GenSigSwitchedByIgnition" SG_ 901 CHA_Ziel_FahrPr_ESP 0;
BA_ "GenSigSendType" SG_ 901 CHA_Ziel_FahrPr_Freilauf 3;
BA_ "GenSigSwitchedByIgnition" SG_ 901 CHA_Ziel_FahrPr_Freilauf 0;
BA_ "GenSigSendType" SG_ 901 CHA_Ziel_FahrPr_GE 3;
BA_ "GenSigSwitchedByIgnition" SG_ 901 CHA_Ziel_FahrPr_GE 0;
BA_ "GenSigSendType" SG_ 901 CHA_Ziel_FahrPr_MO 3;
BA_ "GenSigSwitchedByIgnition" SG_ 901 CHA_Ziel_FahrPr_MO 0;
BA_ "GenSigSendType" SG_ 901 CHA_Ziel_FahrPr_MO_BZS 3;
BA_ "GenSigSwitchedByIgnition" SG_ 901 CHA_Ziel_FahrPr_MO_BZS 0;
BA_ "GenSigSendType" SG_ 901 CHA_Ziel_FahrPr_MO_StSt 3;
BA_ "GenSigSwitchedByIgnition" SG_ 901 CHA_Ziel_FahrPr_MO_StSt 0;
BA_ "GenSigSendType" SG_ 901 CHA_Ziel_FahrPr_PreCrash 3;
BA_ "GenSigSwitchedByIgnition" SG_ 901 CHA_Ziel_FahrPr_PreCrash 0;
BA_ "GenSigSendType" SG_ 901 CHA_Ziel_FahrPr_SAK 3;
BA_ "GenSigSwitchedByIgnition" SG_ 901 CHA_Ziel_FahrPr_SAK 0;
BA_ "GenSigSendType" SG_ 901 CHA_Ziel_FahrPr_VAQ 3;
BA_ "GenSigSwitchedByIgnition" SG_ 901 CHA_Ziel_FahrPr_VAQ 0;
BA_ "GenSigSendType" SG_ 1022 CHA_Current_Mode_BMA 3;
BA_ "GenSigSwitchedByIgnition" SG_ 1022 CHA_Current_Mode_BMA 0;
BA_ "GenSigSendType" SG_ 1022 CHA_Fahrer_Umschaltung 3;
BA_ "GenSigSwitchedByIgnition" SG_ 1022 CHA_Fahrer_Umschaltung 0;
BA_ "GenSigSendType" SG_ 1022 CHA_Fahrer_Umschaltung_BMA 3;
BA_ "GenSigSwitchedByIgnition" SG_ 1022 CHA_Fahrer_Umschaltung_BMA 0;
BA_ "GenSigSendType" SG_ 1022 CHA_Ziel_FahrPr_AGK 3;
BA_ "GenSigSwitchedByIgnition" SG_ 1022 CHA_Ziel_FahrPr_AGK 0;
BA_ "GenSigSendType" SG_ 1022 CHA_Ziel_FahrPr_BMS 3;
BA_ "GenSigSwitchedByIgnition" SG_ 1022 CHA_Ziel_FahrPr_BMS 0;
BA_ "GenSigSendType" SG_ 1022 CHA_Ziel_FahrPr_EDS 3;
BA_ "GenSigSwitchedByIgnition" SG_ 1022 CHA_Ziel_FahrPr_EDS 0;
BA_ "GenSigSendType" SG_ 1022 CHA_Ziel_FahrPr_HHC 3;
BA_ "GenSigSwitchedByIgnition" SG_ 1022 CHA_Ziel_FahrPr_HHC 0;
BA_ "GenSigSendType" SG_ 1022 CHA_Ziel_FahrPr_MO_Freilauf 3;
BA_ "GenSigSwitchedByIgnition" SG_ 1022 CHA_Ziel_FahrPr_MO_Freilauf 0;
BA_ "GenSigSendType" SG_ 1022 CHA_Ziel_FahrPr_PACC 3;
BA_ "GenSigSwitchedByIgnition" SG_ 1022 CHA_Ziel_FahrPr_PACC 0;
BA_ "GenSigSendType" SG_ 1022 CHA_Ziel_FahrPr_PDC 3;
BA_ "GenSigSwitchedByIgnition" SG_ 1022 CHA_Ziel_FahrPr_PDC 0;
BA_ "GenSigSendType" SG_ 1022 CHA_Ziel_FahrPr_Reku_ZwGas 3;
BA_ "GenSigSwitchedByIgnition" SG_ 1022 CHA_Ziel_FahrPr_Reku_ZwGas 0;
BA_ "GenSigSendType" SG_ 686 DC_IstSpannung_HV 0;
BA_ "GenSigStartValue" SG_ 686 DC_IstSpannung_HV 4094;
BA_ "GenSigSwitchedByIgnition" SG_ 686 DC_IstSpannung_HV 0;
BA_ "Fehlerwert" SG_ 686 DC_IstSpannung_HV 4095;
BA_ "GenSigSendType" SG_ 686 DC_IstSpannung_NV 0;
BA_ "GenSigStartValue" SG_ 686 DC_IstSpannung_NV 254;
BA_ "GenSigSwitchedByIgnition" SG_ 686 DC_IstSpannung_NV 0;
BA_ "Fehlerwert" SG_ 686 DC_IstSpannung_NV 255;
BA_ "GenSigSendType" SG_ 686 DC_IstStrom_HV_02 0;
BA_ "GenSigStartValue" SG_ 686 DC_IstStrom_HV_02 1022;
BA_ "GenSigSwitchedByIgnition" SG_ 686 DC_IstStrom_HV_02 0;
BA_ "Fehlerwert" SG_ 686 DC_IstStrom_HV_02 1023;
BA_ "GenSigSendType" SG_ 686 DC_IstStrom_NV 0;
BA_ "GenSigStartValue" SG_ 686 DC_IstStrom_NV 1022;
BA_ "GenSigSwitchedByIgnition" SG_ 686 DC_IstStrom_NV 0;
BA_ "Fehlerwert" SG_ 686 DC_IstStrom_NV 1023;
BA_ "GenSigSendType" SG_ 686 DCDC_01_BZ 0;
BA_ "GenSigFuncType" SG_ 686 DCDC_01_BZ 1;
BA_ "GenSigSwitchedByIgnition" SG_ 686 DCDC_01_BZ 0;
BA_ "GenSigSendType" SG_ 686 DCDC_01_CRC 0;
BA_ "GenSigFuncType" SG_ 686 DCDC_01_CRC 2;
BA_ "GenSigSwitchedByIgnition" SG_ 686 DCDC_01_CRC 0;
BA_ "GenSigSendType" SG_ 1012 DC_HYB_Auslastungsgrad 0;
BA_ "GenSigStartValue" SG_ 1012 DC_HYB_Auslastungsgrad 254;
BA_ "Fehlerwert" SG_ 1012 DC_HYB_Auslastungsgrad 255;
BA_ "GenSigSendType" SG_ 1012 DC_HYB_iAktReserveLV 0;
BA_ "GenSigStartValue" SG_ 1012 DC_HYB_iAktReserveLV 1022;
BA_ "GenSigSwitchedByIgnition" SG_ 1012 DC_HYB_iAktReserveLV 0;
BA_ "Fehlerwert" SG_ 1012 DC_HYB_iAktReserveLV 1023;
BA_ "GenSigSendType" SG_ 1012 DC_Verbrauch 0;
BA_ "GenSigSwitchedByIgnition" SG_ 1012 DC_Verbrauch 0;
BA_ "GenSigSendType" SG_ 1012 DC_Verbrauch_Ueberlauf 0;
BA_ "GenSigSwitchedByIgnition" SG_ 1012 DC_Verbrauch_Ueberlauf 0;
BA_ "GenSigSendType" SG_ 1012 DC_Verlustleistung 0;
BA_ "GenSigStartValue" SG_ 1012 DC_Verlustleistung 62;
BA_ "GenSigSwitchedByIgnition" SG_ 1012 DC_Verlustleistung 0;
BA_ "Fehlerwert" SG_ 1012 DC_Verlustleistung 63;
BA_ "GenSigSendType" SG_ 1012 DCDC_02_BZ 0;
BA_ "GenSigFuncType" SG_ 1012 DCDC_02_BZ 1;
BA_ "GenSigSwitchedByIgnition" SG_ 1012 DCDC_02_BZ 0;
BA_ "GenSigSendType" SG_ 1012 DCDC_02_CRC 0;
BA_ "GenSigFuncType" SG_ 1012 DCDC_02_CRC 2;
BA_ "GenSigSwitchedByIgnition" SG_ 1012 DCDC_02_CRC 0;
BA_ "GenSigSendType" SG_ 1485 DC_Abregelung_Temperatur 3;
BA_ "GenSigSwitchedByIgnition" SG_ 1485 DC_Abregelung_Temperatur 0;
BA_ "GenSigSendType" SG_ 1485 DC_Fehlerstatus 3;
BA_ "GenSigStartValue" SG_ 1485 DC_Fehlerstatus 7;
BA_ "GenSigSwitchedByIgnition" SG_ 1485 DC_Fehlerstatus 0;
BA_ "GenSigSendType" SG_ 1485 DC_IstModus_02 3;
BA_ "GenSigStartValue" SG_ 1485 DC_IstModus_02 7;
BA_ "GenSigSwitchedByIgnition" SG_ 1485 DC_IstModus_02 0;
BA_ "GenSigSendType" SG_ 1485 DC_IstSpannung_EKK_HV 0;
BA_ "GenSigStartValue" SG_ 1485 DC_IstSpannung_EKK_HV 255;
BA_ "GenSigSwitchedByIgnition" SG_ 1485 DC_IstSpannung_EKK_HV 0;
BA_ "GenSigSendType" SG_ 1485 DC_Peakstrom_verfuegbar 3;
BA_ "GenSigSwitchedByIgnition" SG_ 1485 DC_Peakstrom_verfuegbar 0;
BA_ "GenSigSendType" SG_ 1485 DC_Status_Spgfreiheit_HV 3;
BA_ "GenSigSwitchedByIgnition" SG_ 1485 DC_Status_Spgfreiheit_HV 0;
BA_ "GenSigSendType" SG_ 1485 DC_Temperatur 0;
BA_ "GenSigStartValue" SG_ 1485 DC_Temperatur 254;
BA_ "GenSigSwitchedByIgnition" SG_ 1485 DC_Temperatur 0;
BA_ "Fehlerwert" SG_ 1485 DC_Temperatur 255;
BA_ "GenSigSendType" SG_ 1485 DCDC_03_BZ 0;
BA_ "GenSigFuncType" SG_ 1485 DCDC_03_BZ 1;
BA_ "GenSigSwitchedByIgnition" SG_ 1485 DCDC_03_BZ 0;
BA_ "GenSigSendType" SG_ 1485 DCDC_03_CRC 0;
BA_ "GenSigFuncType" SG_ 1485 DCDC_03_CRC 2;
BA_ "GenSigSwitchedByIgnition" SG_ 1485 DCDC_03_CRC 0;
BA_ "GenSigSendType" SG_ 2589283653 DCDC_HV_02_01_BZ 0;
BA_ "GenSigFuncType" SG_ 2589283653 DCDC_HV_02_01_BZ 1;
BA_ "GenSigSwitchedByIgnition" SG_ 2589283653 DCDC_HV_02_01_BZ 0;
BA_ "GenSigSendType" SG_ 2589283653 DCDC_HV_02_01_CRC 0;
BA_ "GenSigFuncType" SG_ 2589283653 DCDC_HV_02_01_CRC 2;
BA_ "GenSigSwitchedByIgnition" SG_ 2589283653 DCDC_HV_02_01_CRC 0;
BA_ "GenSigSendType" SG_ 2589283653 HVLB_AC_Laden_verfuegbar 0;
BA_ "GenSigSwitchedByIgnition" SG_ 2589283653 HVLB_AC_Laden_verfuegbar 0;
BA_ "GenSigSendType" SG_ 2589283653 HVLB_DC_Laden_mitBoost_verfuegb 0;
BA_ "GenSigSwitchedByIgnition" SG_ 2589283653 HVLB_DC_Laden_mitBoost_verfuegb 0;
BA_ "GenSigSendType" SG_ 2589283653 HVLB_DC_Laden_ohneBoost_verfuegb 0;
BA_ "GenSigSwitchedByIgnition" SG_ 2589283653 HVLB_DC_Laden_ohneBoost_verfuegb 0;
BA_ "GenSigSendType" SG_ 2589283653 HVLB_Fehlerstatus 0;
BA_ "GenSigStartValue" SG_ 2589283653 HVLB_Fehlerstatus 7;
BA_ "GenSigSwitchedByIgnition" SG_ 2589283653 HVLB_Fehlerstatus 0;
BA_ "GenSigSendType" SG_ 2589283653 HVLB_IstModus 3;
BA_ "GenSigStartValue" SG_ 2589283653 HVLB_IstModus 7;
BA_ "GenSigSwitchedByIgnition" SG_ 2589283653 HVLB_IstModus 0;
BA_ "Fehlerwert" SG_ 2589283653 HVLB_IstModus 5;
BA_ "GenSigSendType" SG_ 2589283653 HVLB_IstModus_TN1 3;
BA_ "GenSigStartValue" SG_ 2589283653 HVLB_IstModus_TN1 3;
BA_ "GenSigSwitchedByIgnition" SG_ 2589283653 HVLB_IstModus_TN1 0;
BA_ "Fehlerwert" SG_ 2589283653 HVLB_IstModus_TN1 2;
BA_ "GenSigSendType" SG_ 2589283653 HVLB_IstSpannung_DCLS 0;
BA_ "GenSigStartValue" SG_ 2589283653 HVLB_IstSpannung_DCLS 4094;
BA_ "GenSigSwitchedByIgnition" SG_ 2589283653 HVLB_IstSpannung_DCLS 0;
BA_ "Fehlerwert" SG_ 2589283653 HVLB_IstSpannung_DCLS 4095;
BA_ "GenSigSendType" SG_ 2589283653 HVLB_IstSpannung_HVHS 0;
BA_ "GenSigStartValue" SG_ 2589283653 HVLB_IstSpannung_HVHS 4094;
BA_ "GenSigSwitchedByIgnition" SG_ 2589283653 HVLB_IstSpannung_HVHS 0;
BA_ "Fehlerwert" SG_ 2589283653 HVLB_IstSpannung_HVHS 4095;
BA_ "GenSigSendType" SG_ 2589283653 HVLB_IstStrom_HVHS 0;
BA_ "GenSigStartValue" SG_ 2589283653 HVLB_IstStrom_HVHS 4094;
BA_ "GenSigSwitchedByIgnition" SG_ 2589283653 HVLB_IstStrom_HVHS 0;
BA_ "Fehlerwert" SG_ 2589283653 HVLB_IstStrom_HVHS 4095;
BA_ "GenSigSendType" SG_ 2589283653 HVLB_StatusSpgfreiheit_HV 0;
BA_ "GenSigSwitchedByIgnition" SG_ 2589283653 HVLB_StatusSpgfreiheit_HV 0;
BA_ "GenSigSendType" SG_ 2589283653 HVLB_Warnzustand 0;
BA_ "GenSigSwitchedByIgnition" SG_ 2589283653 HVLB_Warnzustand 0;
BA_ "GenSigSendType" SG_ 2463978669 DCDC_HV_02_02_BZ 0;
BA_ "GenSigFuncType" SG_ 2463978669 DCDC_HV_02_02_BZ 1;
BA_ "GenSigSwitchedByIgnition" SG_ 2463978669 DCDC_HV_02_02_BZ 0;
BA_ "GenSigSendType" SG_ 2463978669 DCDC_HV_02_02_CRC 0;
BA_ "GenSigFuncType" SG_ 2463978669 DCDC_HV_02_02_CRC 2;
BA_ "GenSigSwitchedByIgnition" SG_ 2463978669 DCDC_HV_02_02_CRC 0;
BA_ "GenSigSendType" SG_ 2463978669 HVLB_IstSpannung_HVLS 0;
BA_ "GenSigStartValue" SG_ 2463978669 HVLB_IstSpannung_HVLS 4094;
BA_ "GenSigSwitchedByIgnition" SG_ 2463978669 HVLB_IstSpannung_HVLS 0;
BA_ "Fehlerwert" SG_ 2463978669 HVLB_IstSpannung_HVLS 4095;
BA_ "GenSigSendType" SG_ 2463978669 HVLB_MaxDynStrom_HVLS 0;
BA_ "GenSigStartValue" SG_ 2463978669 HVLB_MaxDynStrom_HVLS 4094;
BA_ "GenSigSwitchedByIgnition" SG_ 2463978669 HVLB_MaxDynStrom_HVLS 0;
BA_ "Fehlerwert" SG_ 2463978669 HVLB_MaxDynStrom_HVLS 4095;
BA_ "GenSigSendType" SG_ 2463978669 HVLB_Temperatur 0;
BA_ "GenSigStartValue" SG_ 2463978669 HVLB_Temperatur 254;
BA_ "GenSigSwitchedByIgnition" SG_ 2463978669 HVLB_Temperatur 0;
BA_ "Fehlerwert" SG_ 2463978669 HVLB_Temperatur 255;
BA_ "GenSigSendType" SG_ 2589283662 HVLB_PlanAntw_Verlustleistung 0;
BA_ "GenSigStartValue" SG_ 2589283662 HVLB_PlanAntw_Verlustleistung 4094;
BA_ "GenSigSwitchedByIgnition" SG_ 2589283662 HVLB_PlanAntw_Verlustleistung 0;
BA_ "Fehlerwert" SG_ 2589283662 HVLB_PlanAntw_Verlustleistung 4095;
BA_ "GenSigSendType" SG_ 2589283662 HVLB_PlanAntw_Zaehler 0;
BA_ "GenSigStartValue" SG_ 2589283662 HVLB_PlanAntw_Zaehler 14;
BA_ "GenSigSwitchedByIgnition" SG_ 2589283662 HVLB_PlanAntw_Zaehler 0;
BA_ "Fehlerwert" SG_ 2589283662 HVLB_PlanAntw_Zaehler 15;
BA_ "GenSigSendType" SG_ 685 DC_MV_IstSpannung_MV 0;
BA_ "GenSigStartValue" SG_ 685 DC_MV_IstSpannung_MV 254;
BA_ "GenSigSwitchedByIgnition" SG_ 685 DC_MV_IstSpannung_MV 0;
BA_ "Fehlerwert" SG_ 685 DC_MV_IstSpannung_MV 255;
BA_ "GenSigSendType" SG_ 685 DC_MV_IstSpannung_NV 0;
BA_ "GenSigStartValue" SG_ 685 DC_MV_IstSpannung_NV 254;
BA_ "GenSigSwitchedByIgnition" SG_ 685 DC_MV_IstSpannung_NV 0;
BA_ "Fehlerwert" SG_ 685 DC_MV_IstSpannung_NV 255;
BA_ "GenSigSendType" SG_ 685 DC_MV_IstStrom_MV 0;
BA_ "GenSigStartValue" SG_ 685 DC_MV_IstStrom_MV 1022;
BA_ "GenSigSwitchedByIgnition" SG_ 685 DC_MV_IstStrom_MV 0;
BA_ "Fehlerwert" SG_ 685 DC_MV_IstStrom_MV 1023;
BA_ "GenSigSendType" SG_ 685 DC_MV_IstStrom_NV 0;
BA_ "GenSigStartValue" SG_ 685 DC_MV_IstStrom_NV 1022;
BA_ "GenSigSwitchedByIgnition" SG_ 685 DC_MV_IstStrom_NV 0;
BA_ "Fehlerwert" SG_ 685 DC_MV_IstStrom_NV 1023;
BA_ "GenSigSendType" SG_ 685 DCDC_MV_01_BZ 0;
BA_ "GenSigFuncType" SG_ 685 DCDC_MV_01_BZ 1;
BA_ "GenSigSwitchedByIgnition" SG_ 685 DCDC_MV_01_BZ 0;
BA_ "GenSigSendType" SG_ 685 DCDC_MV_01_CRC 0;
BA_ "GenSigFuncType" SG_ 685 DCDC_MV_01_CRC 2;
BA_ "GenSigSwitchedByIgnition" SG_ 685 DCDC_MV_01_CRC 0;
BA_ "GenSigSendType" SG_ 1018 DC_MV_akt_Stromreserve_NV 0;
BA_ "GenSigStartValue" SG_ 1018 DC_MV_akt_Stromreserve_NV 1022;
BA_ "GenSigSwitchedByIgnition" SG_ 1018 DC_MV_akt_Stromreserve_NV 0;
BA_ "Fehlerwert" SG_ 1018 DC_MV_akt_Stromreserve_NV 1023;
BA_ "GenSigSendType" SG_ 1018 DC_MV_Auslastungsgrad 0;
BA_ "GenSigStartValue" SG_ 1018 DC_MV_Auslastungsgrad 254;
BA_ "GenSigSwitchedByIgnition" SG_ 1018 DC_MV_Auslastungsgrad 0;
BA_ "Fehlerwert" SG_ 1018 DC_MV_Auslastungsgrad 255;
BA_ "GenSigSendType" SG_ 1018 DC_MV_MaxStrom_MV 0;
BA_ "GenSigStartValue" SG_ 1018 DC_MV_MaxStrom_MV 62;
BA_ "GenSigSwitchedByIgnition" SG_ 1018 DC_MV_MaxStrom_MV 0;
BA_ "Fehlerwert" SG_ 1018 DC_MV_MaxStrom_MV 63;
BA_ "GenSigSendType" SG_ 1018 DCDC_MV_02_BZ 0;
BA_ "GenSigFuncType" SG_ 1018 DCDC_MV_02_BZ 1;
BA_ "GenSigSwitchedByIgnition" SG_ 1018 DCDC_MV_02_BZ 0;
BA_ "GenSigSendType" SG_ 1018 DCDC_MV_02_CRC 0;
BA_ "GenSigFuncType" SG_ 1018 DCDC_MV_02_CRC 2;
BA_ "GenSigSwitchedByIgnition" SG_ 1018 DCDC_MV_02_CRC 0;
BA_ "GenSigSendType" SG_ 1484 DC_MV_12V_Bordnetzstuetzung 3;
BA_ "GenSigSwitchedByIgnition" SG_ 1484 DC_MV_12V_Bordnetzstuetzung 0;
BA_ "GenSigSendType" SG_ 1484 DC_MV_Abregelung_Temperatur 3;
BA_ "GenSigSwitchedByIgnition" SG_ 1484 DC_MV_Abregelung_Temperatur 0;
BA_ "GenSigSendType" SG_ 1484 DC_MV_Dyn_MaxSpannung 0;
BA_ "GenSigStartValue" SG_ 1484 DC_MV_Dyn_MaxSpannung 254;
BA_ "GenSigSwitchedByIgnition" SG_ 1484 DC_MV_Dyn_MaxSpannung 0;
BA_ "GenSigSendType" SG_ 1484 DC_MV_Dyn_MinSpannung 0;
BA_ "GenSigStartValue" SG_ 1484 DC_MV_Dyn_MinSpannung 254;
BA_ "GenSigSwitchedByIgnition" SG_ 1484 DC_MV_Dyn_MinSpannung 0;
BA_ "GenSigSendType" SG_ 1484 DC_MV_Fehlerstatus 3;
BA_ "GenSigStartValue" SG_ 1484 DC_MV_Fehlerstatus 7;
BA_ "GenSigSwitchedByIgnition" SG_ 1484 DC_MV_Fehlerstatus 0;
BA_ "GenSigSendType" SG_ 1484 DC_MV_IstModus 3;
BA_ "GenSigStartValue" SG_ 1484 DC_MV_IstModus 7;
BA_ "GenSigSwitchedByIgnition" SG_ 1484 DC_MV_IstModus 0;
BA_ "Fehlerwert" SG_ 1484 DC_MV_IstModus 5;
BA_ "GenSigSendType" SG_ 1484 DC_MV_Temperatur 0;
BA_ "GenSigStartValue" SG_ 1484 DC_MV_Temperatur 254;
BA_ "GenSigSwitchedByIgnition" SG_ 1484 DC_MV_Temperatur 0;
BA_ "Fehlerwert" SG_ 1484 DC_MV_Temperatur 255;
BA_ "GenSigSendType" SG_ 1484 DC_MV_Tiefsetzen_Notbetrieb 3;
BA_ "GenSigSwitchedByIgnition" SG_ 1484 DC_MV_Tiefsetzen_Notbetrieb 0;
BA_ "GenSigSendType" SG_ 1484 DCDC_MV_03_BZ 0;
BA_ "GenSigFuncType" SG_ 1484 DCDC_MV_03_BZ 1;
BA_ "GenSigSwitchedByIgnition" SG_ 1484 DCDC_MV_03_BZ 0;
BA_ "GenSigSendType" SG_ 1484 DCDC_MV_03_CRC 0;
BA_ "GenSigFuncType" SG_ 1484 DCDC_MV_03_CRC 2;
BA_ "GenSigSwitchedByIgnition" SG_ 1484 DCDC_MV_03_CRC 0;
BA_ "GenSigSendType" SG_ 1484 DCDC_MV_Peakstrom_verfuegbar 3;
BA_ "GenSigSwitchedByIgnition" SG_ 1484 DCDC_MV_Peakstrom_verfuegbar 0;
BA_ "GenSigSwitchedByIgnition" SG_ 2617015040 DEV_AWC_Resp_00_Data 0;
BA_ "GenSigSwitchedByIgnition" SG_ 2617015295 DEV_AWC_Resp_FF_Data 0;
BA_ "GenSigSwitchedByIgnition" SG_ 2617078528 DEV_BattRegelung_Req_00_Data 0;
BA_ "GenSigSwitchedByIgnition" SG_ 2617078783 DEV_BattRegelung_Resp_FF_Data 0;
BA_ "GenSigSwitchedByIgnition" SG_ 2617041664 DEV_BMS_MV_Resp_00_Data 0;
BA_ "GenSigSwitchedByIgnition" SG_ 2617041919 DEV_BMS_MV_Resp_FF_Data 0;
BA_ "GenSigSwitchedByIgnition" SG_ 2617235968 DEV_BMS_Resp_00_Data 0;
BA_ "GenSigSwitchedByIgnition" SG_ 2617236223 DEV_BMS_Resp_FF_Data 0;
BA_ "GenSigFuncType" SG_ 2617129728 DEV_DCDC_HV_02_Req_01_Data 9;
BA_ "GenSigSwitchedByIgnition" SG_ 2617129728 DEV_DCDC_HV_02_Req_01_Data 0;
BA_ "GenSigFuncType" SG_ 2617129729 DEV_DCDC_HV_02_Resp_01_Data 9;
BA_ "GenSigSwitchedByIgnition" SG_ 2617129729 DEV_DCDC_HV_02_Resp_01_Data 0;
BA_ "GenSigFuncType" SG_ 2617129983 DEV_DCDC_HV_02_Resp_FF_Data 9;
BA_ "GenSigSwitchedByIgnition" SG_ 2617129983 DEV_DCDC_HV_02_Resp_FF_Data 0;
BA_ "GenSigSwitchedByIgnition" SG_ 2617096960 DEV_DCDC_HV_Resp_00_Data 0;
BA_ "GenSigSwitchedByIgnition" SG_ 2617097215 DEV_DCDC_HV_Resp_FF_Data 0;
BA_ "GenSigSwitchedByIgnition" SG_ 2617117184 DEV_DCDC_Resp_00_Data 0;
BA_ "GenSigSwitchedByIgnition" SG_ 2617117439 DEV_DCDC_Resp_FF_Data 0;
BA_ "GenSigFuncType" SG_ 2617193216 DEV_Ladegeraet_2_Req_01_Data 9;
BA_ "GenSigSwitchedByIgnition" SG_ 2617193216 DEV_Ladegeraet_2_Req_01_Data 0;
BA_ "GenSigFuncType" SG_ 2617193217 DEV_Ladegeraet_2_Resp_01_Data 9;
BA_ "GenSigSwitchedByIgnition" SG_ 2617193217 DEV_Ladegeraet_2_Resp_01_Data 0;
BA_ "GenSigFuncType" SG_ 2617193471 DEV_Ladegeraet_2_Resp_FF_Data 9;
BA_ "GenSigSwitchedByIgnition" SG_ 2617193471 DEV_Ladegeraet_2_Resp_FF_Data 0;
BA_ "GenSigFuncType" SG_ 2617123328 DEV_Ladegeraet_Req_01_Data 9;
BA_ "GenSigSwitchedByIgnition" SG_ 2617123328 DEV_Ladegeraet_Req_01_Data 0;
BA_ "GenSigFuncType" SG_ 2617123329 DEV_Ladegeraet_Resp_01_Data 9;
BA_ "GenSigSwitchedByIgnition" SG_ 2617123329 DEV_Ladegeraet_Resp_01_Data 0;
BA_ "GenSigFuncType" SG_ 2617123583 DEV_Ladegeraet_Resp_FF_Data 9;
BA_ "GenSigSwitchedByIgnition" SG_ 2617123583 DEV_Ladegeraet_Resp_FF_Data 0;
BA_ "GenSigSwitchedByIgnition" SG_ 2617238016 DEV_LEH_01_Resp_00_Data 0;
BA_ "GenSigSwitchedByIgnition" SG_ 2617238271 DEV_LEH_01_Resp_FF_Data 0;
BA_ "GenSigSwitchedByIgnition" SG_ 2617119232 DEV_TME_Resp_00_Data 0;
BA_ "GenSigSendType" SG_ 2617119233 DEV_TME_TmeCoc_rPmpBatt_VW_Data 0;
BA_ "GenSigSwitchedByIgnition" SG_ 2617119233 DEV_TME_TmeCoc_rPmpBatt_VW_Data 0;
BA_ "GenSigSendType" SG_ 2617119233 DEV_TME_TmeCoc_rPmpHeatCir_VW_Data 0;
BA_ "GenSigSwitchedByIgnition" SG_ 2617119233 DEV_TME_TmeCoc_rPmpHeatCir_VW_Data 0;
BA_ "GenSigSendType" SG_ 2617119233 DEV_TME_CoCirDrv_rActStepVlvBypBatt_VW_Data 0;
BA_ "GenSigSwitchedByIgnition" SG_ 2617119233 DEV_TME_CoCirDrv_rActStepVlvBypBatt_VW_Data 0;
BA_ "GenSigSendType" SG_ 2617119233 DEV_TME_TmePrePrc_tAirEvpIn_VW_Data 0;
BA_ "GenSigSwitchedByIgnition" SG_ 2617119233 DEV_TME_TmePrePrc_tAirEvpIn_VW_Data 0;
BA_ "GenSigSendType" SG_ 2617119233 DEV_TME_TmePrePrc_tCoRadOut_VW_Data 0;
BA_ "GenSigSwitchedByIgnition" SG_ 2617119233 DEV_TME_TmePrePrc_tCoRadOut_VW_Data 0;
BA_ "GenSigSendType" SG_ 2617119233 DEV_TME_TmeRadBliDd_rRadBliAct2_VW_Data 0;
BA_ "GenSigSwitchedByIgnition" SG_ 2617119233 DEV_TME_TmeRadBliDd_rRadBliAct2_VW_Data 0;
BA_ "GenSigSendType" SG_ 2617119233 DEV_TME_TmePostPrc_tFilCoHeatExchIn_VW_Data 0;
BA_ "GenSigSwitchedByIgnition" SG_ 2617119233 DEV_TME_TmePostPrc_tFilCoHeatExchIn_VW_Data 0;
BA_ "GenSigSendType" SG_ 2617119233 DEV_TME_CoCirDrv_rActStepVlvBypRad_VW_Data 0;
BA_ "GenSigSwitchedByIgnition" SG_ 2617119233 DEV_TME_CoCirDrv_rActStepVlvBypRad_VW_Data 0;
BA_ "GenSigSendType" SG_ 2617119234 DEV_TME_TmeCoc_rPmpCmbEng_VW_Data 0;
BA_ "GenSigSwitchedByIgnition" SG_ 2617119234 DEV_TME_TmeCoc_rPmpCmbEng_VW_Data 0;
BA_ "GenSigSendType" SG_ 2617119234 DEV_TME_TmeCoc_bBypRad_VW_Data 0;
BA_ "GenSigSwitchedByIgnition" SG_ 2617119234 DEV_TME_TmeCoc_bBypRad_VW_Data 0;
BA_ "GenSigSendType" SG_ 2617119234 DEV_TME_TmeCoc_bBattCir_VW_Data 0;
BA_ "GenSigSwitchedByIgnition" SG_ 2617119234 DEV_TME_TmeCoc_bBattCir_VW_Data 0;
BA_ "GenSigSendType" SG_ 2617119234 DEV_TME_TmeCoc_bBypBatt_VW_Data 0;
BA_ "GenSigSwitchedByIgnition" SG_ 2617119234 DEV_TME_TmeCoc_bBypBatt_VW_Data 0;
BA_ "GenSigSendType" SG_ 2617119234 DEV_TME_TmeCoc_rDemFan_VW_Data 0;
BA_ "GenSigSwitchedByIgnition" SG_ 2617119234 DEV_TME_TmeCoc_rDemFan_VW_Data 0;
BA_ "GenSigSendType" SG_ 2617119234 DEV_TME_TmeCoc_bCmbEngCirSml_VW_Data 0;
BA_ "GenSigSwitchedByIgnition" SG_ 2617119234 DEV_TME_TmeCoc_bCmbEngCirSml_VW_Data 0;
BA_ "GenSigSendType" SG_ 2617119234 DEV_TME_TmeCoc_bElmCir_VW_Data 0;
BA_ "GenSigSwitchedByIgnition" SG_ 2617119234 DEV_TME_TmeCoc_bElmCir_VW_Data 0;
BA_ "GenSigSendType" SG_ 2617119234 DEV_TME_TmeCoc_stDiagRespCoCtlElm_VW_Data 0;
BA_ "GenSigSwitchedByIgnition" SG_ 2617119234 DEV_TME_TmeCoc_stDiagRespCoCtlElm_VW_Data 0;
BA_ "GenSigSendType" SG_ 2617119234 DEV_TME_TmeCoc_rPmpRadOut_VW_Data 0;
BA_ "GenSigSwitchedByIgnition" SG_ 2617119234 DEV_TME_TmeCoc_rPmpRadOut_VW_Data 0;
BA_ "GenSigSendType" SG_ 2617119234 DEV_TME_TmeCoc_stDiagRespHeatCir_VW_Data 0;
BA_ "GenSigSwitchedByIgnition" SG_ 2617119234 DEV_TME_TmeCoc_stDiagRespHeatCir_VW_Data 0;
BA_ "GenSigSendType" SG_ 2617119234 DEV_TME_TmeCoc_volfRadOutMin_VW_Data 0;
BA_ "GenSigSwitchedByIgnition" SG_ 2617119234 DEV_TME_TmeCoc_volfRadOutMin_VW_Data 0;
BA_ "GenSigSendType" SG_ 2617119234 DEV_TME_CoCir_tCoElmInvIn_VW_Data 0;
BA_ "GenSigSwitchedByIgnition" SG_ 2617119234 DEV_TME_CoCir_tCoElmInvIn_VW_Data 0;
BA_ "GenSigSendType" SG_ 2617119234 DEV_TME_CoCir_tCoRadOut_VW_Data 0;
BA_ "GenSigSwitchedByIgnition" SG_ 2617119234 DEV_TME_CoCir_tCoRadOut_VW_Data 0;
BA_ "GenSigSendType" SG_ 2617119234 DEV_TME_CoCir_tCoHeatExchIn_VW_Data 0;
BA_ "GenSigSwitchedByIgnition" SG_ 2617119234 DEV_TME_CoCir_tCoHeatExchIn_VW_Data 0;
BA_ "GenSigSendType" SG_ 2617119234 DEV_TME_TmeCtl_noDrvModAcv_VW_Data 0;
BA_ "GenSigSwitchedByIgnition" SG_ 2617119234 DEV_TME_TmeCtl_noDrvModAcv_VW_Data 0;
BA_ "GenSigSendType" SG_ 2617119234 DEV_TME_TmeEcu_bFanDblEcu_VW_Data 0;
BA_ "GenSigSwitchedByIgnition" SG_ 2617119234 DEV_TME_TmeEcu_bFanDblEcu_VW_Data 0;
BA_ "GenSigSendType" SG_ 2617119235 DEV_TME_TmeCtl_stSysConfCoCtlElm_VW_Data 0;
BA_ "GenSigSwitchedByIgnition" SG_ 2617119235 DEV_TME_TmeCtl_stSysConfCoCtlElm_VW_Data 0;
BA_ "GenSigSendType" SG_ 2617119235 DEV_TME_TmeCtl_stSysConfCoCtlBatt_VW_Data 0;
BA_ "GenSigSwitchedByIgnition" SG_ 2617119235 DEV_TME_TmeCtl_stSysConfCoCtlBatt_VW_Data 0;
BA_ "GenSigSendType" SG_ 2617119235 DEV_TME_TmeCtl_stThmElm_VW_Data 0;
BA_ "GenSigSwitchedByIgnition" SG_ 2617119235 DEV_TME_TmeCtl_stThmElm_VW_Data 0;
BA_ "GenSigSendType" SG_ 2617119235 DEV_TME_TmeCtl_stOpm_VW_Data 0;
BA_ "GenSigSwitchedByIgnition" SG_ 2617119235 DEV_TME_TmeCtl_stOpm_VW_Data 0;
BA_ "GenSigSendType" SG_ 2617119235 DEV_TME_TmeCtl_stSysConfHeatCir_VW_Data 0;
BA_ "GenSigSwitchedByIgnition" SG_ 2617119235 DEV_TME_TmeCtl_stSysConfHeatCir_VW_Data 0;
BA_ "GenSigSendType" SG_ 2617119235 DEV_TME_TmeCtl_stThmCab_VW_Data 0;
BA_ "GenSigSwitchedByIgnition" SG_ 2617119235 DEV_TME_TmeCtl_stThmCab_VW_Data 0;
BA_ "GenSigSendType" SG_ 2617119235 DEV_TME_TmeCtl_stThmBatt_VW_Data 0;
BA_ "GenSigSwitchedByIgnition" SG_ 2617119235 DEV_TME_TmeCtl_stThmBatt_VW_Data 0;
BA_ "GenSigSendType" SG_ 2617119235 DEV_TME_TmeCtl_stSysConfHeatSrcCtl_VW_Data 0;
BA_ "GenSigSwitchedByIgnition" SG_ 2617119235 DEV_TME_TmeCtl_stSysConfHeatSrcCtl_VW_Data 0;
BA_ "GenSigSendType" SG_ 2617119235 DEV_TME_TmeCtl_stSysConfRefrCir_VW_Data 0;
BA_ "GenSigSwitchedByIgnition" SG_ 2617119235 DEV_TME_TmeCtl_stSysConfRefrCir_VW_Data 0;
BA_ "GenSigSendType" SG_ 2617119235 DEV_TME_TmeCtl_stHvCpntReq_VW_Data 0;
BA_ "GenSigSwitchedByIgnition" SG_ 2617119235 DEV_TME_TmeCtl_stHvCpntReq_VW_Data 0;
BA_ "GenSigSendType" SG_ 2617119235 DEV_TME_TmeEm_bTrigCalc_tiPreCdnCabPas_VW_Data 0;
BA_ "GenSigSwitchedByIgnition" SG_ 2617119235 DEV_TME_TmeEm_bTrigCalc_tiPreCdnCabPas_VW_Data 0;
BA_ "GenSigSendType" SG_ 2617119235 DEV_TME_TmeCtl_stCodPsblConfHeatPmpWaHeat_VW_Data 0;
BA_ "GenSigSwitchedByIgnition" SG_ 2617119235 DEV_TME_TmeCtl_stCodPsblConfHeatPmpWaHeat_VW_Data 0;
BA_ "GenSigSendType" SG_ 2617119235 DEV_TME_TmeCtl_noModPreCdnCab_VW_Data 0;
BA_ "GenSigSwitchedByIgnition" SG_ 2617119235 DEV_TME_TmeCtl_noModPreCdnCab_VW_Data 0;
BA_ "GenSigSendType" SG_ 2617119235 DEV_TME_TmeEm_bConfReqPreCdnCab_VW_Data 0;
BA_ "GenSigSwitchedByIgnition" SG_ 2617119235 DEV_TME_TmeEm_bConfReqPreCdnCab_VW_Data 0;
BA_ "GenSigSendType" SG_ 2617119235 DEV_TME_TmeObdIf_bMonRst_VW_Data 0;
BA_ "GenSigSwitchedByIgnition" SG_ 2617119235 DEV_TME_TmeObdIf_bMonRst_VW_Data 0;
BA_ "GenSigSendType" SG_ 2617119236 DEV_TME_CoCir_tCoChilBattOut_VW_Data 0;
BA_ "GenSigSwitchedByIgnition" SG_ 2617119236 DEV_TME_CoCir_tCoChilBattOut_VW_Data 0;
BA_ "GenSigSendType" SG_ 2617119236 DEV_TME_CoCir_tCoChilBattIn_VW_Data 0;
BA_ "GenSigSwitchedByIgnition" SG_ 2617119236 DEV_TME_CoCir_tCoChilBattIn_VW_Data 0;
BA_ "GenSigSendType" SG_ 2617119236 DEV_TME_HvBatt_stDemCoHeatHvBatt_VW_Data 0;
BA_ "GenSigSwitchedByIgnition" SG_ 2617119236 DEV_TME_HvBatt_stDemCoHeatHvBatt_VW_Data 0;
BA_ "GenSigSendType" SG_ 2617119236 DEV_TME_TmeDem_tAirEvpSet_VW_Data 0;
BA_ "GenSigSwitchedByIgnition" SG_ 2617119236 DEV_TME_TmeDem_tAirEvpSet_VW_Data 0;
BA_ "GenSigSendType" SG_ 2617119236 DEV_TME_TmeDem_tCoChilBattOutSet_VW_Data 0;
BA_ "GenSigSwitchedByIgnition" SG_ 2617119236 DEV_TME_TmeDem_tCoChilBattOutSet_VW_Data 0;
BA_ "GenSigSendType" SG_ 2617119236 DEV_TME_TmeDem_stThmBatt_VW_Data 0;
BA_ "GenSigSwitchedByIgnition" SG_ 2617119236 DEV_TME_TmeDem_stThmBatt_VW_Data 0;
BA_ "GenSigSendType" SG_ 2617119236 DEV_TME_TmeDem_stThmElm_VW_Data 0;
BA_ "GenSigSwitchedByIgnition" SG_ 2617119236 DEV_TME_TmeDem_stThmElm_VW_Data 0;
BA_ "GenSigSendType" SG_ 2617119236 DEV_TME_TmeDem_stThmCab_VW_Data 0;
BA_ "GenSigSwitchedByIgnition" SG_ 2617119236 DEV_TME_TmeDem_stThmCab_VW_Data 0;
BA_ "GenSigSendType" SG_ 2617119236 DEV_TME_WaHt_pwr_VW_Data 0;
BA_ "GenSigSwitchedByIgnition" SG_ 2617119236 DEV_TME_WaHt_pwr_VW_Data 0;
BA_ "GenSigSendType" SG_ 2617119236 DEV_TME_TmeEm_pwrAvlCmpr_VW_Data 0;
BA_ "GenSigSwitchedByIgnition" SG_ 2617119236 DEV_TME_TmeEm_pwrAvlCmpr_VW_Data 0;
BA_ "GenSigSendType" SG_ 2617119236 DEV_TME_TmeRcc_stSysConfResp_VW_Data 0;
BA_ "GenSigSwitchedByIgnition" SG_ 2617119236 DEV_TME_TmeRcc_stSysConfResp_VW_Data 0;
BA_ "GenSigSendType" SG_ 2617119236 DEV_TME_TmeEcu_bEnaPmp_VW_Data 0;
BA_ "GenSigSwitchedByIgnition" SG_ 2617119236 DEV_TME_TmeEcu_bEnaPmp_VW_Data 0;
BA_ "GenSigSendType" SG_ 2617119237 DEV_TME_TmeEm_pwrAvl_VW_Data 0;
BA_ "GenSigSwitchedByIgnition" SG_ 2617119237 DEV_TME_TmeEm_pwrAvl_VW_Data 0;
BA_ "GenSigSendType" SG_ 2617119237 DEV_TME_TmeEm_rPrfCmprThmCo_VW_Data 0;
BA_ "GenSigSwitchedByIgnition" SG_ 2617119237 DEV_TME_TmeEm_rPrfCmprThmCo_VW_Data 0;
BA_ "GenSigSendType" SG_ 2617119237 DEV_TME_TmeEm_rPrfCmprCmft_VW_Data 0;
BA_ "GenSigSwitchedByIgnition" SG_ 2617119237 DEV_TME_TmeEm_rPrfCmprCmft_VW_Data 0;
BA_ "GenSigSendType" SG_ 2617119237 DEV_TME_AC_pwrCmpr_VW_Data 0;
BA_ "GenSigSwitchedByIgnition" SG_ 2617119237 DEV_TME_AC_pwrCmpr_VW_Data 0;
BA_ "GenSigSendType" SG_ 2617119237 DEV_TME_TmeHeatSrcCtl_rWaHeatPrf_VW_Data 0;
BA_ "GenSigSwitchedByIgnition" SG_ 2617119237 DEV_TME_TmeHeatSrcCtl_rWaHeatPrf_VW_Data 0;
BA_ "GenSigSendType" SG_ 2617119237 DEV_TME_TmeFan_rFanPwm2_VW_Data 0;
BA_ "GenSigSwitchedByIgnition" SG_ 2617119237 DEV_TME_TmeFan_rFanPwm2_VW_Data 0;
BA_ "GenSigSendType" SG_ 2617119237 DEV_TME_TmeFan_rFanPwm1_VW_Data 0;
BA_ "GenSigSwitchedByIgnition" SG_ 2617119237 DEV_TME_TmeFan_rFanPwm1_VW_Data 0;
BA_ "GenSigSendType" SG_ 2617119237 DEV_TME_WaHt_tWaHeatOut_VW_Data 0;
BA_ "GenSigSwitchedByIgnition" SG_ 2617119237 DEV_TME_WaHt_tWaHeatOut_VW_Data 0;
BA_ "GenSigSendType" SG_ 2617119237 DEV_TME_CoCir_rActStepVlvInrWaHeatExch_VW_Data 0;
BA_ "GenSigSwitchedByIgnition" SG_ 2617119237 DEV_TME_CoCir_rActStepVlvInrWaHeatExch_VW_Data 0;
BA_ "GenSigSendType" SG_ 2617119237 DEV_TME_TmeCoc_bEnaPls_VW_Data 0;
BA_ "GenSigSwitchedByIgnition" SG_ 2617119237 DEV_TME_TmeCoc_bEnaPls_VW_Data 0;
BA_ "GenSigSendType" SG_ 2617119238 DEV_TME_TmeEm_stHvCpntPrfAvl_VW_Data 0;
BA_ "GenSigSwitchedByIgnition" SG_ 2617119238 DEV_TME_TmeEm_stHvCpntPrfAvl_VW_Data 0;
BA_ "GenSigSendType" SG_ 2617119238 DEV_TME_TmeFan_bOverAcv_VW_Data 0;
BA_ "GenSigSwitchedByIgnition" SG_ 2617119238 DEV_TME_TmeFan_bOverAcv_VW_Data 0;
BA_ "GenSigSendType" SG_ 2617119238 DEV_TME_TmeHeatSrcCtl_stPrfRed2Mes_VW_Data 0;
BA_ "GenSigSwitchedByIgnition" SG_ 2617119238 DEV_TME_TmeHeatSrcCtl_stPrfRed2Mes_VW_Data 0;
BA_ "GenSigSendType" SG_ 2617119238 DEV_TME_TmeFan_stRadBliReq_VW_Data 0;
BA_ "GenSigSwitchedByIgnition" SG_ 2617119238 DEV_TME_TmeFan_stRadBliReq_VW_Data 0;
BA_ "GenSigSendType" SG_ 2617119238 DEV_TME_TmeFan_bFanEfcAcv_VW_Data 0;
BA_ "GenSigSwitchedByIgnition" SG_ 2617119238 DEV_TME_TmeFan_bFanEfcAcv_VW_Data 0;
BA_ "GenSigSendType" SG_ 2617119238 DEV_TME_TmeEm_pwrAvlWaHeat_VW_Data 0;
BA_ "GenSigSwitchedByIgnition" SG_ 2617119238 DEV_TME_TmeEm_pwrAvlWaHeat_VW_Data 0;
BA_ "GenSigSendType" SG_ 2617119238 DEV_TME_TmeEm_bOverAcv_VW_Data 0;
BA_ "GenSigSwitchedByIgnition" SG_ 2617119238 DEV_TME_TmeEm_bOverAcv_VW_Data 0;
BA_ "GenSigSendType" SG_ 2617119238 DEV_TME_TmeHeatSrcCtl_bChkHvRdy_VW_Data 0;
BA_ "GenSigSwitchedByIgnition" SG_ 2617119238 DEV_TME_TmeHeatSrcCtl_bChkHvRdy_VW_Data 0;
BA_ "GenSigSendType" SG_ 2617119238 DEV_TME_ParkHtCtl_stStgyPreCdnCab_VW_Data 0;
BA_ "GenSigSwitchedByIgnition" SG_ 2617119238 DEV_TME_ParkHtCtl_stStgyPreCdnCab_VW_Data 0;
BA_ "GenSigSendType" SG_ 2617119238 DEV_TME_TmeEm_pwrStatDeltaPredCmftHld_VW_Data 0;
BA_ "GenSigSwitchedByIgnition" SG_ 2617119238 DEV_TME_TmeEm_pwrStatDeltaPredCmftHld_VW_Data 0;
BA_ "GenSigSendType" SG_ 2617119238 DEV_TME_TmeEm_pwrDeltaThdSys_VW_Data 0;
BA_ "GenSigSwitchedByIgnition" SG_ 2617119238 DEV_TME_TmeEm_pwrDeltaThdSys_VW_Data 0;
BA_ "GenSigSendType" SG_ 2617119238 DEV_TME_TmeEm_pwrDeltaThdHld_VW_Data 0;
BA_ "GenSigSwitchedByIgnition" SG_ 2617119238 DEV_TME_TmeEm_pwrDeltaThdHld_VW_Data 0;
BA_ "GenSigSendType" SG_ 2617119238 DEV_TME_TmeEm_bLdMaxAcvPreCdnCab_VW_Data 0;
BA_ "GenSigSwitchedByIgnition" SG_ 2617119238 DEV_TME_TmeEm_bLdMaxAcvPreCdnCab_VW_Data 0;
BA_ "GenSigSendType" SG_ 2617119238 DEV_TME_TmeEm_bLdMax_tiPsblPreCdnCabEl_VW_Data 0;
BA_ "GenSigSwitchedByIgnition" SG_ 2617119238 DEV_TME_TmeEm_bLdMax_tiPsblPreCdnCabEl_VW_Data 0;
BA_ "GenSigSendType" SG_ 2617119239 DEV_TME_TmeRcc_pCmprInSet_VW_Data 0;
BA_ "GenSigSwitchedByIgnition" SG_ 2617119239 DEV_TME_TmeRcc_pCmprInSet_VW_Data 0;
BA_ "GenSigSendType" SG_ 2617119239 DEV_TME_TmeCoc_bPlsHeatCirSmlPsbl_VW_Data 0;
BA_ "GenSigSwitchedByIgnition" SG_ 2617119239 DEV_TME_TmeCoc_bPlsHeatCirSmlPsbl_VW_Data 0;
BA_ "GenSigSendType" SG_ 2617119239 DEV_TME_TmeFan_rFanDemPwmMes_VW_Data 0;
BA_ "GenSigSwitchedByIgnition" SG_ 2617119239 DEV_TME_TmeFan_rFanDemPwmMes_VW_Data 0;
BA_ "GenSigSendType" SG_ 2617119239 DEV_TME_TmeCoc_rPPartVlvHeatCir_VW_Data 0;
BA_ "GenSigSwitchedByIgnition" SG_ 2617119239 DEV_TME_TmeCoc_rPPartVlvHeatCir_VW_Data 0;
BA_ "GenSigSendType" SG_ 2617119239 DEV_TME_TmeCoc_rDemFanElm_VW_Data 0;
BA_ "GenSigSwitchedByIgnition" SG_ 2617119239 DEV_TME_TmeCoc_rDemFanElm_VW_Data 0;
BA_ "GenSigSendType" SG_ 2617119239 DEV_TME_WaHt_tWaHeatIn_VW_Data 0;
BA_ "GenSigSwitchedByIgnition" SG_ 2617119239 DEV_TME_WaHt_tWaHeatIn_VW_Data 0;
BA_ "GenSigSendType" SG_ 2617119239 DEV_TME_TmeEcu_bEnaFan2_VW_Data 0;
BA_ "GenSigSwitchedByIgnition" SG_ 2617119239 DEV_TME_TmeEcu_bEnaFan2_VW_Data 0;
BA_ "GenSigSendType" SG_ 2617119239 DEV_TME_TmeEcu_bEnaFan1_VW_Data 0;
BA_ "GenSigSwitchedByIgnition" SG_ 2617119239 DEV_TME_TmeEcu_bEnaFan1_VW_Data 0;
BA_ "GenSigSendType" SG_ 2617119239 DEV_TME_Pmp_stCmbEngDiag_VW_Data 0;
BA_ "GenSigSwitchedByIgnition" SG_ 2617119239 DEV_TME_Pmp_stCmbEngDiag_VW_Data 0;
BA_ "GenSigSendType" SG_ 2617119239 DEV_TME_RefrCir_pCmprIn_VW_Data 0;
BA_ "GenSigSwitchedByIgnition" SG_ 2617119239 DEV_TME_RefrCir_pCmprIn_VW_Data 0;
BA_ "GenSigSendType" SG_ 2617119239 DEV_TME_Pmp_stHeatCirDiag_VW_Data 0;
BA_ "GenSigSwitchedByIgnition" SG_ 2617119239 DEV_TME_Pmp_stHeatCirDiag_VW_Data 0;
BA_ "GenSigSendType" SG_ 2617119239 DEV_TME_TmeRcc_stDiagResp_VW_Data 0;
BA_ "GenSigSwitchedByIgnition" SG_ 2617119239 DEV_TME_TmeRcc_stDiagResp_VW_Data 0;
BA_ "GenSigSendType" SG_ 2617119240 DEV_TME_RefrCir_pCmprOut_VW_Data 0;
BA_ "GenSigSwitchedByIgnition" SG_ 2617119240 DEV_TME_RefrCir_pCmprOut_VW_Data 0;
BA_ "GenSigSendType" SG_ 2617119240 DEV_TME_RefrCir_pCndsIn_VW_Data 0;
BA_ "GenSigSwitchedByIgnition" SG_ 2617119240 DEV_TME_RefrCir_pCndsIn_VW_Data 0;
BA_ "GenSigSendType" SG_ 2617119240 DEV_TME_Pmp_stRadOutDiag_VW_Data 0;
BA_ "GenSigSwitchedByIgnition" SG_ 2617119240 DEV_TME_Pmp_stRadOutDiag_VW_Data 0;
BA_ "GenSigSendType" SG_ 2617119240 DEV_TME_AC_nCmpr_VW_Data 0;
BA_ "GenSigSwitchedByIgnition" SG_ 2617119240 DEV_TME_AC_nCmpr_VW_Data 0;
BA_ "GenSigSendType" SG_ 2617119240 DEV_TME_CoCir_tCoHeatRegIn_VW_Data 0;
BA_ "GenSigSwitchedByIgnition" SG_ 2617119240 DEV_TME_CoCir_tCoHeatRegIn_VW_Data 0;
BA_ "GenSigSendType" SG_ 2617119240 DEV_TME_CoCir_tCoRadIn_VW_Data 0;
BA_ "GenSigSwitchedByIgnition" SG_ 2617119240 DEV_TME_CoCir_tCoRadIn_VW_Data 0;
BA_ "GenSigSendType" SG_ 2617119240 DEV_TME_CoCir_tCoCmbEngIn_VW_Data 0;
BA_ "GenSigSwitchedByIgnition" SG_ 2617119240 DEV_TME_CoCir_tCoCmbEngIn_VW_Data 0;
BA_ "GenSigSendType" SG_ 2617119240 DEV_TME_CoCir_tCoCmbEngOut_VW_Data 0;
BA_ "GenSigSwitchedByIgnition" SG_ 2617119240 DEV_TME_CoCir_tCoCmbEngOut_VW_Data 0;
BA_ "GenSigSendType" SG_ 2617119241 DEV_TME_AC_tInv_VW_Data 0;
BA_ "GenSigSwitchedByIgnition" SG_ 2617119241 DEV_TME_AC_tInv_VW_Data 0;
BA_ "GenSigSendType" SG_ 2617119241 DEV_TME_RefrCir_tCmprOut_VW_Data 0;
BA_ "GenSigSwitchedByIgnition" SG_ 2617119241 DEV_TME_RefrCir_tCmprOut_VW_Data 0;
BA_ "GenSigSendType" SG_ 2617119241 DEV_TME_RefrCir_tCmprIn_VW_Data 0;
BA_ "GenSigSwitchedByIgnition" SG_ 2617119241 DEV_TME_RefrCir_tCmprIn_VW_Data 0;
BA_ "GenSigSendType" SG_ 2617119241 DEV_TME_TmeCoc_rPmpBattMin_volfBattMin_VW_Data 0;
BA_ "GenSigSwitchedByIgnition" SG_ 2617119241 DEV_TME_TmeCoc_rPmpBattMin_volfBattMin_VW_Data 0;
BA_ "GenSigSendType" SG_ 2617119241 DEV_TME_TmeRcc_rDemFan_VW_Data 0;
BA_ "GenSigSwitchedByIgnition" SG_ 2617119241 DEV_TME_TmeRcc_rDemFan_VW_Data 0;
BA_ "GenSigSendType" SG_ 2617119241 DEV_TME_TmeHeatSrcCtl_bCoProtAcvMes_VW_Data 0;
BA_ "GenSigSwitchedByIgnition" SG_ 2617119241 DEV_TME_TmeHeatSrcCtl_bCoProtAcvMes_VW_Data 0;
BA_ "GenSigSendType" SG_ 2617119241 DEV_TME_TmeHeatSrcCtl_tCtlDeMes_VW_Data 0;
BA_ "GenSigSwitchedByIgnition" SG_ 2617119241 DEV_TME_TmeHeatSrcCtl_tCtlDeMes_VW_Data 0;
BA_ "GenSigSendType" SG_ 2617119241 DEV_TME_TmeHeatSrcCtl_noOpmMes_VW_Data 0;
BA_ "GenSigSwitchedByIgnition" SG_ 2617119241 DEV_TME_TmeHeatSrcCtl_noOpmMes_VW_Data 0;
BA_ "GenSigSendType" SG_ 2617119241 DEV_TME_TmeRcc_nCmprSet_VW_Data 0;
BA_ "GenSigSwitchedByIgnition" SG_ 2617119241 DEV_TME_TmeRcc_nCmprSet_VW_Data 0;
BA_ "GenSigSendType" SG_ 2617119241 DEV_TME_TmeRcc_bVlvEvp_VW_Data 0;
BA_ "GenSigSwitchedByIgnition" SG_ 2617119241 DEV_TME_TmeRcc_bVlvEvp_VW_Data 0;
BA_ "GenSigSendType" SG_ 2617119241 DEV_TME_TmeRcc_stCtlCmpr_VW_Data 0;
BA_ "GenSigSwitchedByIgnition" SG_ 2617119241 DEV_TME_TmeRcc_stCtlCmpr_VW_Data 0;
BA_ "GenSigSendType" SG_ 2617119242 DEV_TME_TmeCtl_stEcuRunReq_VW_Data 0;
BA_ "GenSigSwitchedByIgnition" SG_ 2617119242 DEV_TME_TmeCtl_stEcuRunReq_VW_Data 0;
BA_ "GenSigSendType" SG_ 2617119242 DEV_TME_TmeCtl_stCodSysConf_VW_Data 0;
BA_ "GenSigSwitchedByIgnition" SG_ 2617119242 DEV_TME_TmeCtl_stCodSysConf_VW_Data 0;
BA_ "GenSigSendType" SG_ 2617119242 DEV_TME_TmeCtl_swiMesPrioCol_VW_Data 0;
BA_ "GenSigSwitchedByIgnition" SG_ 2617119242 DEV_TME_TmeCtl_swiMesPrioCol_VW_Data 0;
BA_ "GenSigSendType" SG_ 2617119242 DEV_TME_TmeCtl_idxMesCodTabBas_VW_Data 0;
BA_ "GenSigSwitchedByIgnition" SG_ 2617119242 DEV_TME_TmeCtl_idxMesCodTabBas_VW_Data 0;
BA_ "GenSigSendType" SG_ 2617119242 DEV_TME_TmeDiag_stCmprEmgcyStop_VW_Data 0;
BA_ "GenSigSwitchedByIgnition" SG_ 2617119242 DEV_TME_TmeDiag_stCmprEmgcyStop_VW_Data 0;
BA_ "GenSigSendType" SG_ 2617119242 DEV_TME_TmeCtl_stMesCmbEngStopNotAlwInfo_VW_Data 0;
BA_ "GenSigSwitchedByIgnition" SG_ 2617119242 DEV_TME_TmeCtl_stMesCmbEngStopNotAlwInfo_VW_Data 0;
BA_ "GenSigSendType" SG_ 2617119242 DEV_TME_TmeHeatSrcCtl_stTrigOnParkHeatCtl_VW_Data 0;
BA_ "GenSigSwitchedByIgnition" SG_ 2617119242 DEV_TME_TmeHeatSrcCtl_stTrigOnParkHeatCtl_VW_Data 0;
BA_ "GenSigSendType" SG_ 2617119243 DEV_TME_TmeCtl_stMesCodFctIdc_VW_Data 0;
BA_ "GenSigSwitchedByIgnition" SG_ 2617119243 DEV_TME_TmeCtl_stMesCodFctIdc_VW_Data 0;
BA_ "GenSigSendType" SG_ 2617119243 DEV_TME_TmeCtl_stMesCmbEngStrtReqInfo_VW_Data 0;
BA_ "GenSigSwitchedByIgnition" SG_ 2617119243 DEV_TME_TmeCtl_stMesCmbEngStrtReqInfo_VW_Data 0;
BA_ "GenSigSendType" SG_ 2617119243 DEV_TME_TmeCtl_idxMesCodTabSelConf_VW_Data 0;
BA_ "GenSigSwitchedByIgnition" SG_ 2617119243 DEV_TME_TmeCtl_idxMesCodTabSelConf_VW_Data 0;
BA_ "GenSigSendType" SG_ 2617119243 DEV_TME_TmeCoc_stOverAcv_VW_Data 0;
BA_ "GenSigSwitchedByIgnition" SG_ 2617119243 DEV_TME_TmeCoc_stOverAcv_VW_Data 0;
BA_ "GenSigSendType" SG_ 2617119243 DEV_TME_TmeCtl_stStgyPreCdnCab_VW_Data 0;
BA_ "GenSigSwitchedByIgnition" SG_ 2617119243 DEV_TME_TmeCtl_stStgyPreCdnCab_VW_Data 0;
BA_ "GenSigSendType" SG_ 2617119243 DEV_TME_WaHt_st_VW_Data 0;
BA_ "GenSigSwitchedByIgnition" SG_ 2617119243 DEV_TME_WaHt_st_VW_Data 0;
BA_ "GenSigSendType" SG_ 2617119243 DEV_TME_TmeHeatSrcCtl_stTrigOffParkHeatCtl_VW_Data 0;
BA_ "GenSigSwitchedByIgnition" SG_ 2617119243 DEV_TME_TmeHeatSrcCtl_stTrigOffParkHeatCtl_VW_Data 0;
BA_ "GenSigSendType" SG_ 2617119243 DEV_TME_TmeEm_bTrigCalc_tiPreCdnCabEl_VW_Data 0;
BA_ "GenSigSwitchedByIgnition" SG_ 2617119243 DEV_TME_TmeEm_bTrigCalc_tiPreCdnCabEl_VW_Data 0;
BA_ "GenSigSendType" SG_ 2617119243 DEV_TME_TmeEm_bTrigCalc_tiPreCdnCabParkHeat_VW_Data 0;
BA_ "GenSigSwitchedByIgnition" SG_ 2617119243 DEV_TME_TmeEm_bTrigCalc_tiPreCdnCabParkHeat_VW_Data 0;
BA_ "GenSigSendType" SG_ 2617119243 DEV_TME_TmeEm_stTrig_tiCalcPreCdnCabParkHeat_VW_Data 0;
BA_ "GenSigSwitchedByIgnition" SG_ 2617119243 DEV_TME_TmeEm_stTrig_tiCalcPreCdnCabParkHeat_VW_Data 0;
BA_ "GenSigSendType" SG_ 2617119244 DEV_TME_TmeRcc_nMaxAvlCmpr_VW_Data 0;
BA_ "GenSigSwitchedByIgnition" SG_ 2617119244 DEV_TME_TmeRcc_nMaxAvlCmpr_VW_Data 0;
BA_ "GenSigSendType" SG_ 2617119244 DEV_TME_TmeRcc_pEvpOutSet_VW_Data 0;
BA_ "GenSigSwitchedByIgnition" SG_ 2617119244 DEV_TME_TmeRcc_pEvpOutSet_VW_Data 0;
BA_ "GenSigSendType" SG_ 2617119244 DEV_TME_TmeRcc_nCmprCtl_VW_Data 0;
BA_ "GenSigSwitchedByIgnition" SG_ 2617119244 DEV_TME_TmeRcc_nCmprCtl_VW_Data 0;
BA_ "GenSigSendType" SG_ 2617119244 DEV_TME_TmeRcc_tOverHeatCmprIn_VW_Data 0;
BA_ "GenSigSwitchedByIgnition" SG_ 2617119244 DEV_TME_TmeRcc_tOverHeatCmprIn_VW_Data 0;
BA_ "GenSigSendType" SG_ 2617119244 DEV_TME_TmeRcc_tOverHeatCmprOut_VW_Data 0;
BA_ "GenSigSwitchedByIgnition" SG_ 2617119244 DEV_TME_TmeRcc_tOverHeatCmprOut_VW_Data 0;
BA_ "GenSigSendType" SG_ 2617119244 DEV_TME_TmeRcc_tOverHeatCmprOutSet_VW_Data 0;
BA_ "GenSigSwitchedByIgnition" SG_ 2617119244 DEV_TME_TmeRcc_tOverHeatCmprOutSet_VW_Data 0;
BA_ "GenSigSendType" SG_ 2617119244 DEV_TME_TmeRcc_stCurSysConfIt_VW_Data 0;
BA_ "GenSigSwitchedByIgnition" SG_ 2617119244 DEV_TME_TmeRcc_stCurSysConfIt_VW_Data 0;
BA_ "GenSigSendType" SG_ 2617119244 DEV_TME_TmeRcc_stCmprOff_VW_Data 0;
BA_ "GenSigSwitchedByIgnition" SG_ 2617119244 DEV_TME_TmeRcc_stCmprOff_VW_Data 0;
BA_ "GenSigSendType" SG_ 2617119244 DEV_TME_TmeRcc_bCmprAcv_VW_Data 0;
BA_ "GenSigSwitchedByIgnition" SG_ 2617119244 DEV_TME_TmeRcc_bCmprAcv_VW_Data 0;
BA_ "GenSigSendType" SG_ 2617119245 DEV_TME_TmeRcc_stDer_nCmpr_VW_Data 0;
BA_ "GenSigSwitchedByIgnition" SG_ 2617119245 DEV_TME_TmeRcc_stDer_nCmpr_VW_Data 0;
BA_ "GenSigSendType" SG_ 2617119245 DEV_TME_TmeRcc_stSysConfItSet_VW_Data 0;
BA_ "GenSigSwitchedByIgnition" SG_ 2617119245 DEV_TME_TmeRcc_stSysConfItSet_VW_Data 0;
BA_ "GenSigSendType" SG_ 2617119245 DEV_TME_AC_stCmpr_VW_Data 0;
BA_ "GenSigSwitchedByIgnition" SG_ 2617119245 DEV_TME_AC_stCmpr_VW_Data 0;
BA_ "GenSigSendType" SG_ 2617119245 DEV_TME_TmeRcc_bGlbCtlEna_VW_Data 0;
BA_ "GenSigSwitchedByIgnition" SG_ 2617119245 DEV_TME_TmeRcc_bGlbCtlEna_VW_Data 0;
BA_ "GenSigSendType" SG_ 2617119245 DEV_TME_TmeRcc_bVlvChilBatt_VW_Data 0;
BA_ "GenSigSwitchedByIgnition" SG_ 2617119245 DEV_TME_TmeRcc_bVlvChilBatt_VW_Data 0;
BA_ "GenSigSendType" SG_ 2617119245 DEV_TME_TmeDem_tCoHeatExchInWaHeatSet_VW_Data 0;
BA_ "GenSigSwitchedByIgnition" SG_ 2617119245 DEV_TME_TmeDem_tCoHeatExchInWaHeatSet_VW_Data 0;
BA_ "GenSigSendType" SG_ 2617119245 DEV_TME_TmeRcc_tOverHeatCmprInSet_VW_Data 0;
BA_ "GenSigSwitchedByIgnition" SG_ 2617119245 DEV_TME_TmeRcc_tOverHeatCmprInSet_VW_Data 0;
BA_ "GenSigSendType" SG_ 2617119245 DEV_TME_TmeDem_tCoHeatExchInHeatPmpSet_VW_Data 0;
BA_ "GenSigSwitchedByIgnition" SG_ 2617119245 DEV_TME_TmeDem_tCoHeatExchInHeatPmpSet_VW_Data 0;
BA_ "GenSigSendType" SG_ 2617119245 DEV_TME_TmeRcc_bLeav2LvlMod_VW_Data 0;
BA_ "GenSigSwitchedByIgnition" SG_ 2617119245 DEV_TME_TmeRcc_bLeav2LvlMod_VW_Data 0;
BA_ "GenSigSendType" SG_ 2617119245 DEV_TME_TmeRcc_bOverAcv_VW_Data 0;
BA_ "GenSigSwitchedByIgnition" SG_ 2617119245 DEV_TME_TmeRcc_bOverAcv_VW_Data 0;
BA_ "GenSigSendType" SG_ 2617119245 DEV_TME_TmeRcc_bReqMinRevCmpr_VW_Data 0;
BA_ "GenSigSwitchedByIgnition" SG_ 2617119245 DEV_TME_TmeRcc_bReqMinRevCmpr_VW_Data 0;
BA_ "GenSigSendType" SG_ 2617119245 DEV_TME_FanPkg_stVarResp2_VW_Data 0;
BA_ "GenSigSwitchedByIgnition" SG_ 2617119245 DEV_TME_FanPkg_stVarResp2_VW_Data 0;
BA_ "GenSigSendType" SG_ 2617119245 DEV_TME_FanPkg_stVarResp1_VW_Data 0;
BA_ "GenSigSwitchedByIgnition" SG_ 2617119245 DEV_TME_FanPkg_stVarResp1_VW_Data 0;
BA_ "GenSigSendType" SG_ 2617119245 DEV_TME_TmeCtl_swiMesDiagRespRslt_VW_Data 0;
BA_ "GenSigSwitchedByIgnition" SG_ 2617119245 DEV_TME_TmeCtl_swiMesDiagRespRslt_VW_Data 0;
BA_ "GenSigSendType" SG_ 2617119245 DEV_TME_FanPkg_stDiag2_VW_Data 0;
BA_ "GenSigSwitchedByIgnition" SG_ 2617119245 DEV_TME_FanPkg_stDiag2_VW_Data 0;
BA_ "GenSigSendType" SG_ 2617119245 DEV_TME_FanPkg_stDiag1_VW_Data 0;
BA_ "GenSigSwitchedByIgnition" SG_ 2617119245 DEV_TME_FanPkg_stDiag1_VW_Data 0;
BA_ "GenSigSendType" SG_ 2617119245 DEV_TME_TmeCoc_bCmbEngOverAcv_VW_Data 0;
BA_ "GenSigSwitchedByIgnition" SG_ 2617119245 DEV_TME_TmeCoc_bCmbEngOverAcv_VW_Data 0;
BA_ "GenSigSendType" SG_ 2617119245 DEV_TME_TmeCoc_bCoCirOverAcv_VW_Data 0;
BA_ "GenSigSwitchedByIgnition" SG_ 2617119245 DEV_TME_TmeCoc_bCoCirOverAcv_VW_Data 0;
BA_ "GenSigSendType" SG_ 2617119245 DEV_TME_TmeHeatSrcCtl_bNotAcv_VW_Data 0;
BA_ "GenSigSwitchedByIgnition" SG_ 2617119245 DEV_TME_TmeHeatSrcCtl_bNotAcv_VW_Data 0;
BA_ "GenSigSendType" SG_ 2617119245 DEV_TME_TmeHeatSrcCtl_bRedAcvMes_VW_Data 0;
BA_ "GenSigSwitchedByIgnition" SG_ 2617119245 DEV_TME_TmeHeatSrcCtl_bRedAcvMes_VW_Data 0;
BA_ "GenSigSendType" SG_ 2617119245 DEV_TME_TmeCoc_bHeatCirOverAcv_VW_Data 0;
BA_ "GenSigSwitchedByIgnition" SG_ 2617119245 DEV_TME_TmeCoc_bHeatCirOverAcv_VW_Data 0;
BA_ "GenSigSendType" SG_ 2617119246 DEV_TME_TmeCoc_volfHvObChMin_VW_Data 0;
BA_ "GenSigSwitchedByIgnition" SG_ 2617119246 DEV_TME_TmeCoc_volfHvObChMin_VW_Data 0;
BA_ "GenSigSendType" SG_ 2617119246 DEV_TME_TmeHeatSrcCtl_rIPartMes_VW_Data 0;
BA_ "GenSigSwitchedByIgnition" SG_ 2617119246 DEV_TME_TmeHeatSrcCtl_rIPartMes_VW_Data 0;
BA_ "GenSigSendType" SG_ 2617119246 DEV_TME_TmeHeatSrcCtl_rPilCtlMes_VW_Data 0;
BA_ "GenSigSwitchedByIgnition" SG_ 2617119246 DEV_TME_TmeHeatSrcCtl_rPilCtlMes_VW_Data 0;
BA_ "GenSigSendType" SG_ 2617119246 DEV_TME_TmeHeatSrcCtl_rPPartMes_VW_Data 0;
BA_ "GenSigSwitchedByIgnition" SG_ 2617119246 DEV_TME_TmeHeatSrcCtl_rPPartMes_VW_Data 0;
BA_ "GenSigSendType" SG_ 2617119246 DEV_TME_TmeDiag_idxDiagVlvBattCirOp_VW_Data 0;
BA_ "GenSigSwitchedByIgnition" SG_ 2617119246 DEV_TME_TmeDiag_idxDiagVlvBattCirOp_VW_Data 0;
BA_ "GenSigSendType" SG_ 2617119246 DEV_TME_TmeDiag_idxDiagVlvBypBattByp_VW_Data 0;
BA_ "GenSigSwitchedByIgnition" SG_ 2617119246 DEV_TME_TmeDiag_idxDiagVlvBypBattByp_VW_Data 0;
BA_ "GenSigSendType" SG_ 2617119246 DEV_TME_TmeDiag_idxDiagVlvBattCirBlock_VW_Data 0;
BA_ "GenSigSwitchedByIgnition" SG_ 2617119246 DEV_TME_TmeDiag_idxDiagVlvBattCirBlock_VW_Data 0;
BA_ "GenSigSendType" SG_ 2617119246 DEV_TME_TmeDiag_idxDiagTsChilBattIn_VW_Data 0;
BA_ "GenSigSwitchedByIgnition" SG_ 2617119246 DEV_TME_TmeDiag_idxDiagTsChilBattIn_VW_Data 0;
BA_ "GenSigSendType" SG_ 2617119246 DEV_TME_TmeDiag_idxDiagTsChilBattOut_VW_Data 0;
BA_ "GenSigSwitchedByIgnition" SG_ 2617119246 DEV_TME_TmeDiag_idxDiagTsChilBattOut_VW_Data 0;
BA_ "GenSigSendType" SG_ 2617119246 DEV_TME_TmeDem_rBattDeltaRel_VW_Data 0;
BA_ "GenSigSwitchedByIgnition" SG_ 2617119246 DEV_TME_TmeDem_rBattDeltaRel_VW_Data 0;
BA_ "GenSigSendType" SG_ 2617119246 DEV_TME_TmeDem_rElmDeltaRel_VW_Data 0;
BA_ "GenSigSwitchedByIgnition" SG_ 2617119246 DEV_TME_TmeDem_rElmDeltaRel_VW_Data 0;
BA_ "GenSigSendType" SG_ 2617119246 DEV_TME_TmeDem_bBypBatt_VW_Data 0;
BA_ "GenSigSwitchedByIgnition" SG_ 2617119246 DEV_TME_TmeDem_bBypBatt_VW_Data 0;
BA_ "GenSigSendType" SG_ 2617119247 DEV_TME_TmeObdIf_stVehSensMonOk_VW_Data 0;
BA_ "GenSigSwitchedByIgnition" SG_ 2617119247 DEV_TME_TmeObdIf_stVehSensMonOk_VW_Data 0;
BA_ "GenSigSendType" SG_ 2617119247 DEV_TME_TmeCtl_bRlsPreCdnCab_VW_Data 0;
BA_ "GenSigSwitchedByIgnition" SG_ 2617119247 DEV_TME_TmeCtl_bRlsPreCdnCab_VW_Data 0;
BA_ "GenSigSendType" SG_ 2617119247 DEV_TME_TmeDem_rElm1DeltaRel_VW_Data 0;
BA_ "GenSigSwitchedByIgnition" SG_ 2617119247 DEV_TME_TmeDem_rElm1DeltaRel_VW_Data 0;
BA_ "GenSigSendType" SG_ 2617119247 DEV_TME_TmeDem_rElmInv1DeltaRel_VW_Data 0;
BA_ "GenSigSwitchedByIgnition" SG_ 2617119247 DEV_TME_TmeDem_rElmInv1DeltaRel_VW_Data 0;
BA_ "GenSigSendType" SG_ 2617119247 DEV_TME_TmeDem_rHvObChDeltaRel_VW_Data 0;
BA_ "GenSigSwitchedByIgnition" SG_ 2617119247 DEV_TME_TmeDem_rHvObChDeltaRel_VW_Data 0;
BA_ "GenSigSendType" SG_ 2617119247 DEV_TME_TmeDem_rHvBattDeltaRel_VW_Data 0;
BA_ "GenSigSwitchedByIgnition" SG_ 2617119247 DEV_TME_TmeDem_rHvBattDeltaRel_VW_Data 0;
BA_ "GenSigSendType" SG_ 2617119247 DEV_TME_TmeDem_stThmHvObCh_VW_Data 0;
BA_ "GenSigSwitchedByIgnition" SG_ 2617119247 DEV_TME_TmeDem_stThmHvObCh_VW_Data 0;
BA_ "GenSigSendType" SG_ 2617119248 DEV_TME_TmeDem_rDcDcDeltaRel_VW_Data 0;
BA_ "GenSigSwitchedByIgnition" SG_ 2617119248 DEV_TME_TmeDem_rDcDcDeltaRel_VW_Data 0;
BA_ "GenSigSendType" SG_ 2617119248 DEV_TME_TmeRcc_rStepVlvCndsIn_VW_Data 0;
BA_ "GenSigSwitchedByIgnition" SG_ 2617119248 DEV_TME_TmeRcc_rStepVlvCndsIn_VW_Data 0;
BA_ "GenSigSendType" SG_ 2617119248 DEV_TME_TmeRcc_rStepRxvChilBatt_VW_Data 0;
BA_ "GenSigSwitchedByIgnition" SG_ 2617119248 DEV_TME_TmeRcc_rStepRxvChilBatt_VW_Data 0;
BA_ "GenSigSendType" SG_ 2617119248 DEV_TME_TmeRcc_rStepVlvRefrExtcCnds_VW_Data 0;
BA_ "GenSigSwitchedByIgnition" SG_ 2617119248 DEV_TME_TmeRcc_rStepVlvRefrExtcCnds_VW_Data 0;
BA_ "GenSigSendType" SG_ 2617119248 DEV_TME_TmeRcc_rStepVlvHeatRegIn_VW_Data 0;
BA_ "GenSigSwitchedByIgnition" SG_ 2617119248 DEV_TME_TmeRcc_rStepVlvHeatRegIn_VW_Data 0;
BA_ "GenSigSendType" SG_ 2617119248 DEV_TME_TmeRcc_rStepVlvRefrExtcHeatReg_VW_Data 0;
BA_ "GenSigSwitchedByIgnition" SG_ 2617119248 DEV_TME_TmeRcc_rStepVlvRefrExtcHeatReg_VW_Data 0;
BA_ "GenSigSendType" SG_ 2617119248 DEV_TME_AC_stStgyPreCabCdn_VW_Data 0;
BA_ "GenSigSwitchedByIgnition" SG_ 2617119248 DEV_TME_AC_stStgyPreCabCdn_VW_Data 0;
BA_ "GenSigSendType" SG_ 2617119248 DEV_TME_TmeDiag_idxDiagVlvBypBattHi_VW_Data 0;
BA_ "GenSigSwitchedByIgnition" SG_ 2617119248 DEV_TME_TmeDiag_idxDiagVlvBypBattHi_VW_Data 0;
BA_ "GenSigSendType" SG_ 2617119248 DEV_TME_TmeCoc_rDemFanBatt_VW_Data 0;
BA_ "GenSigSwitchedByIgnition" SG_ 2617119248 DEV_TME_TmeCoc_rDemFanBatt_VW_Data 0;
BA_ "GenSigSendType" SG_ 2617119248 DEV_TME_TmeDem_stThmHvBatt_VW_Data 0;
BA_ "GenSigSwitchedByIgnition" SG_ 2617119248 DEV_TME_TmeDem_stThmHvBatt_VW_Data 0;
BA_ "GenSigSendType" SG_ 2617119249 DEV_TME_TmeObdIf_stRefrCirMonOkPlaus_VW_Data 0;
BA_ "GenSigSwitchedByIgnition" SG_ 2617119249 DEV_TME_TmeObdIf_stRefrCirMonOkPlaus_VW_Data 0;
BA_ "GenSigSendType" SG_ 2617119249 DEV_TME_TmeObdIf_stCoCirMonOkEl_VW_Data 0;
BA_ "GenSigSwitchedByIgnition" SG_ 2617119249 DEV_TME_TmeObdIf_stCoCirMonOkEl_VW_Data 0;
BA_ "GenSigSendType" SG_ 2617119250 DEV_TME_TmeObdIf_stCoCirMonOkPlaus_VW_Data 0;
BA_ "GenSigSwitchedByIgnition" SG_ 2617119250 DEV_TME_TmeObdIf_stCoCirMonOkPlaus_VW_Data 0;
BA_ "GenSigSendType" SG_ 2617119250 DEV_TME_TmeObdIf_stRefrCirMonOkEl_VW_Data 0;
BA_ "GenSigSwitchedByIgnition" SG_ 2617119250 DEV_TME_TmeObdIf_stRefrCirMonOkEl_VW_Data 0;
BA_ "GenSigSendType" SG_ 2617119251 DEV_TME_TmeObdIf_stHeatCirMonOkEl_VW_Data 0;
BA_ "GenSigSwitchedByIgnition" SG_ 2617119251 DEV_TME_TmeObdIf_stHeatCirMonOkEl_VW_Data 0;
BA_ "GenSigSendType" SG_ 2617119251 DEV_TME_TmeObdIf_stHeatCirMonOkPlaus_VW_Data 0;
BA_ "GenSigSwitchedByIgnition" SG_ 2617119251 DEV_TME_TmeObdIf_stHeatCirMonOkPlaus_VW_Data 0;
BA_ "GenSigSendType" SG_ 2617119252 DEV_TME_TmeCtl_stCodPsblConfExtd_VW_Data 0;
BA_ "GenSigSwitchedByIgnition" SG_ 2617119252 DEV_TME_TmeCtl_stCodPsblConfExtd_VW_Data 0;
BA_ "GenSigSendType" SG_ 2617119252 DEV_TME_TmeCtl_stCodPsblConf_VW_Data 0;
BA_ "GenSigSwitchedByIgnition" SG_ 2617119252 DEV_TME_TmeCtl_stCodPsblConf_VW_Data 0;
BA_ "GenSigSendType" SG_ 2617119253 DEV_TME_TmeCtl_stCodPsblConfPreCdnCab_VW_Data 0;
BA_ "GenSigSwitchedByIgnition" SG_ 2617119253 DEV_TME_TmeCtl_stCodPsblConfPreCdnCab_VW_Data 0;
BA_ "GenSigSendType" SG_ 2617119253 DEV_TME_TmeCtl_idxMesCodTabBasCur_VW_Data 0;
BA_ "GenSigSwitchedByIgnition" SG_ 2617119253 DEV_TME_TmeCtl_idxMesCodTabBasCur_VW_Data 0;
BA_ "GenSigSendType" SG_ 2617119253 DEV_TME_TmeCtl_idxMesCodTabSelConfRel_VW_Data 0;
BA_ "GenSigSwitchedByIgnition" SG_ 2617119253 DEV_TME_TmeCtl_idxMesCodTabSelConfRel_VW_Data 0;
BA_ "GenSigSendType" SG_ 2617119253 DEV_TME_TmeCtl_noMesCodTabPsblConfCur_VW_Data 0;
BA_ "GenSigSwitchedByIgnition" SG_ 2617119253 DEV_TME_TmeCtl_noMesCodTabPsblConfCur_VW_Data 0;
BA_ "GenSigSendType" SG_ 2617119253 DEV_TME_TmeEm_stMesCodTrigCabPred_VW_Data 0;
BA_ "GenSigSwitchedByIgnition" SG_ 2617119253 DEV_TME_TmeEm_stMesCodTrigCabPred_VW_Data 0;
BA_ "GenSigSendType" SG_ 2617119253 DEV_TME_TmeCtl_stElmThmSelClas_VW_Data 0;
BA_ "GenSigSwitchedByIgnition" SG_ 2617119253 DEV_TME_TmeCtl_stElmThmSelClas_VW_Data 0;
BA_ "GenSigSendType" SG_ 2617119253 DEV_TME_TmeCtl_stCabThmSelClas_VW_Data 0;
BA_ "GenSigSwitchedByIgnition" SG_ 2617119253 DEV_TME_TmeCtl_stCabThmSelClas_VW_Data 0;
BA_ "GenSigSendType" SG_ 2617119253 DEV_TME_TmeCtl_stRedLvlCmprPrf_VW_Data 0;
BA_ "GenSigSwitchedByIgnition" SG_ 2617119253 DEV_TME_TmeCtl_stRedLvlCmprPrf_VW_Data 0;
BA_ "GenSigSendType" SG_ 2617119254 DEV_TME_TmeRcc_nMaxCmprUnFil_vVeh_VW_Data 0;
BA_ "GenSigSwitchedByIgnition" SG_ 2617119254 DEV_TME_TmeRcc_nMaxCmprUnFil_vVeh_VW_Data 0;
BA_ "GenSigSendType" SG_ 2617119254 DEV_TME_TmeDem_stThmDcDc_VW_Data 0;
BA_ "GenSigSwitchedByIgnition" SG_ 2617119254 DEV_TME_TmeDem_stThmDcDc_VW_Data 0;
BA_ "GenSigSendType" SG_ 2617119254 DEV_TME_TmeDem_stThmElmInv1_VW_Data 0;
BA_ "GenSigSwitchedByIgnition" SG_ 2617119254 DEV_TME_TmeDem_stThmElmInv1_VW_Data 0;
BA_ "GenSigSendType" SG_ 2617119254 DEV_TME_TmeDiag_idxDiagTsRadIn_VW_Data 0;
BA_ "GenSigSwitchedByIgnition" SG_ 2617119254 DEV_TME_TmeDiag_idxDiagTsRadIn_VW_Data 0;
BA_ "GenSigSendType" SG_ 2617119254 DEV_TME_TmeDiag_idxDiagTsElmInvIn_VW_Data 0;
BA_ "GenSigSwitchedByIgnition" SG_ 2617119254 DEV_TME_TmeDiag_idxDiagTsElmInvIn_VW_Data 0;
BA_ "GenSigSendType" SG_ 2617119254 DEV_TME_TmeDiag_idxDiagTsRadOut_VW_Data 0;
BA_ "GenSigSwitchedByIgnition" SG_ 2617119254 DEV_TME_TmeDiag_idxDiagTsRadOut_VW_Data 0;
BA_ "GenSigSendType" SG_ 2617119254 DEV_TME_TmeDiag_idxDiagVlvBypRadByp_VW_Data 0;
BA_ "GenSigSwitchedByIgnition" SG_ 2617119254 DEV_TME_TmeDiag_idxDiagVlvBypRadByp_VW_Data 0;
BA_ "GenSigSendType" SG_ 2617119254 DEV_TME_TmeDiag_idxDiagVlvBypRad_VW_Data 0;
BA_ "GenSigSwitchedByIgnition" SG_ 2617119254 DEV_TME_TmeDiag_idxDiagVlvBypRad_VW_Data 0;
BA_ "GenSigSendType" SG_ 2617119254 DEV_TME_TmeDiag_idxDiagVlvElmCirBatt_VW_Data 0;
BA_ "GenSigSwitchedByIgnition" SG_ 2617119254 DEV_TME_TmeDiag_idxDiagVlvElmCirBatt_VW_Data 0;
BA_ "GenSigSendType" SG_ 2617119254 DEV_TME_TmeDiag_idxDiagVlvElmCirElm_VW_Data 0;
BA_ "GenSigSwitchedByIgnition" SG_ 2617119254 DEV_TME_TmeDiag_idxDiagVlvElmCirElm_VW_Data 0;
BA_ "GenSigSendType" SG_ 2617119254 DEV_TME_TmeDiag_idxDiagTsCmbEngIn_VW_Data 0;
BA_ "GenSigSwitchedByIgnition" SG_ 2617119254 DEV_TME_TmeDiag_idxDiagTsCmbEngIn_VW_Data 0;
BA_ "GenSigSendType" SG_ 2617119254 DEV_TME_TmeDiag_idxDiagTsCoHeatRegIn_VW_Data 0;
BA_ "GenSigSwitchedByIgnition" SG_ 2617119254 DEV_TME_TmeDiag_idxDiagTsCoHeatRegIn_VW_Data 0;
BA_ "GenSigSendType" SG_ 2617119254 DEV_TME_TmeDiag_idxDiagVlvHeatCirEng_VW_Data 0;
BA_ "GenSigSwitchedByIgnition" SG_ 2617119254 DEV_TME_TmeDiag_idxDiagVlvHeatCirEng_VW_Data 0;
BA_ "GenSigSendType" SG_ 2617119254 DEV_TME_TmeDiag_idxDiagVlvHeatCirSml_VW_Data 0;
BA_ "GenSigSwitchedByIgnition" SG_ 2617119254 DEV_TME_TmeDiag_idxDiagVlvHeatCirSml_VW_Data 0;
BA_ "GenSigSendType" SG_ 2617119254 DEV_TME_TmeDiag_idxDiagVlvRefrExtcHeatReg_VW_Data 0;
BA_ "GenSigSwitchedByIgnition" SG_ 2617119254 DEV_TME_TmeDiag_idxDiagVlvRefrExtcHeatReg_VW_Data 0;
BA_ "GenSigSendType" SG_ 2617119254 DEV_TME_TmeDem_bRstOfsSetVal_VW_Data 0;
BA_ "GenSigSwitchedByIgnition" SG_ 2617119254 DEV_TME_TmeDem_bRstOfsSetVal_VW_Data 0;
BA_ "GenSigSendType" SG_ 2617119255 DEV_TME_TmeDiag_idxDiagVlvHeatRegIn_VW_Data 0;
BA_ "GenSigSwitchedByIgnition" SG_ 2617119255 DEV_TME_TmeDiag_idxDiagVlvHeatRegIn_VW_Data 0;
BA_ "GenSigSendType" SG_ 2617119255 DEV_TME_TmeDiag_idxDiagVlvCndsIn_VW_Data 0;
BA_ "GenSigSwitchedByIgnition" SG_ 2617119255 DEV_TME_TmeDiag_idxDiagVlvCndsIn_VW_Data 0;
BA_ "GenSigSendType" SG_ 2617119255 DEV_TME_TmeDiag_idxDiagTsCmprIn_VW_Data 0;
BA_ "GenSigSwitchedByIgnition" SG_ 2617119255 DEV_TME_TmeDiag_idxDiagTsCmprIn_VW_Data 0;
BA_ "GenSigSendType" SG_ 2617119255 DEV_TME_TmeDiag_idxDiagTsVlvHeatRegIn_VW_Data 0;
BA_ "GenSigSwitchedByIgnition" SG_ 2617119255 DEV_TME_TmeDiag_idxDiagTsVlvHeatRegIn_VW_Data 0;
BA_ "GenSigSendType" SG_ 2617119255 DEV_TME_TmeDiag_idxDiagTsRxvChilBatt_VW_Data 0;
BA_ "GenSigSwitchedByIgnition" SG_ 2617119255 DEV_TME_TmeDiag_idxDiagTsRxvChilBatt_VW_Data 0;
BA_ "GenSigSendType" SG_ 2617119255 DEV_TME_TmeDiag_idxDiagTsVlvCndsIn_VW_Data 0;
BA_ "GenSigSwitchedByIgnition" SG_ 2617119255 DEV_TME_TmeDiag_idxDiagTsVlvCndsIn_VW_Data 0;
BA_ "GenSigSendType" SG_ 2617119255 DEV_TME_TmeDiag_idxDiagTsVlvCndsOut_VW_Data 0;
BA_ "GenSigSwitchedByIgnition" SG_ 2617119255 DEV_TME_TmeDiag_idxDiagTsVlvCndsOut_VW_Data 0;
BA_ "GenSigSendType" SG_ 2617119255 DEV_TME_TmeDiag_idxDiagTsCmprOut_VW_Data 0;
BA_ "GenSigSwitchedByIgnition" SG_ 2617119255 DEV_TME_TmeDiag_idxDiagTsCmprOut_VW_Data 0;
BA_ "GenSigSendType" SG_ 2617119255 DEV_TME_TmeDiag_idxDiagTsExtcHeatReg_VW_Data 0;
BA_ "GenSigSwitchedByIgnition" SG_ 2617119255 DEV_TME_TmeDiag_idxDiagTsExtcHeatReg_VW_Data 0;
BA_ "GenSigSendType" SG_ 2617119255 DEV_TME_TmeDiag_idxDiagCoPrfLeak_VW_Data 0;
BA_ "GenSigSwitchedByIgnition" SG_ 2617119255 DEV_TME_TmeDiag_idxDiagCoPrfLeak_VW_Data 0;
BA_ "GenSigSendType" SG_ 2617119255 DEV_TME_FanPkg_stVarReq1_VW_Data 0;
BA_ "GenSigSwitchedByIgnition" SG_ 2617119255 DEV_TME_FanPkg_stVarReq1_VW_Data 0;
BA_ "GenSigSendType" SG_ 2617119255 DEV_TME_FanPkg_stVarReq2_VW_Data 0;
BA_ "GenSigSwitchedByIgnition" SG_ 2617119255 DEV_TME_FanPkg_stVarReq2_VW_Data 0;
BA_ "GenSigSendType" SG_ 2617119255 DEV_TME_TmeDiag_idxDiagFan2ItFail_VW_Data 0;
BA_ "GenSigSwitchedByIgnition" SG_ 2617119255 DEV_TME_TmeDiag_idxDiagFan2ItFail_VW_Data 0;
BA_ "GenSigSendType" SG_ 2617119255 DEV_TME_TmeDiag_idxDiagFan2Block_VW_Data 0;
BA_ "GenSigSwitchedByIgnition" SG_ 2617119255 DEV_TME_TmeDiag_idxDiagFan2Block_VW_Data 0;
BA_ "GenSigSendType" SG_ 2617119255 DEV_TME_TmeDiag_idxDiagFan2OverHeat_VW_Data 0;
BA_ "GenSigSwitchedByIgnition" SG_ 2617119255 DEV_TME_TmeDiag_idxDiagFan2OverHeat_VW_Data 0;
BA_ "GenSigSendType" SG_ 2617119255 DEV_TME_TmeDiag_idxDiagFan1OverHeat_VW_Data 0;
BA_ "GenSigSwitchedByIgnition" SG_ 2617119255 DEV_TME_TmeDiag_idxDiagFan1OverHeat_VW_Data 0;
BA_ "GenSigSendType" SG_ 2617119255 DEV_TME_TmeDiag_idxDiagFan1Block_VW_Data 0;
BA_ "GenSigSwitchedByIgnition" SG_ 2617119255 DEV_TME_TmeDiag_idxDiagFan1Block_VW_Data 0;
BA_ "GenSigSendType" SG_ 2617119256 DEV_TME_TmeDiag_idxDiagFan1ItFail_VW_Data 0;
BA_ "GenSigSwitchedByIgnition" SG_ 2617119256 DEV_TME_TmeDiag_idxDiagFan1ItFail_VW_Data 0;
BA_ "GenSigSendType" SG_ 2617119256 DEV_TME_TmeDiag_idxDiagPsRefr_VW_Data 0;
BA_ "GenSigSwitchedByIgnition" SG_ 2617119256 DEV_TME_TmeDiag_idxDiagPsRefr_VW_Data 0;
BA_ "GenSigSendType" SG_ 2617119256 DEV_TME_TmeDiag_idxDiagRefrLeak_VW_Data 0;
BA_ "GenSigSwitchedByIgnition" SG_ 2617119256 DEV_TME_TmeDiag_idxDiagRefrLeak_VW_Data 0;
BA_ "GenSigSendType" SG_ 2617119256 DEV_TME_TmeDiag_idxDiagCmprDer_VW_Data 0;
BA_ "GenSigSwitchedByIgnition" SG_ 2617119256 DEV_TME_TmeDiag_idxDiagCmprDer_VW_Data 0;
BA_ "GenSigSendType" SG_ 2617119256 DEV_TME_TmeDiag_idxDiagVlvExtcCnds_VW_Data 0;
BA_ "GenSigSwitchedByIgnition" SG_ 2617119256 DEV_TME_TmeDiag_idxDiagVlvExtcCnds_VW_Data 0;
BA_ "GenSigSendType" SG_ 2617119256 DEV_TME_TmeDiag_idxDiagTsItCmprIn_VW_Data 0;
BA_ "GenSigSwitchedByIgnition" SG_ 2617119256 DEV_TME_TmeDiag_idxDiagTsItCmprIn_VW_Data 0;
BA_ "GenSigSendType" SG_ 2617119256 DEV_TME_TmeDiag_idxDiagTsItCmprOut_VW_Data 0;
BA_ "GenSigSwitchedByIgnition" SG_ 2617119256 DEV_TME_TmeDiag_idxDiagTsItCmprOut_VW_Data 0;
BA_ "GenSigSendType" SG_ 2617119256 DEV_TME_RefrCir_tItCmprOut_VW_Data 0;
BA_ "GenSigSwitchedByIgnition" SG_ 2617119256 DEV_TME_RefrCir_tItCmprOut_VW_Data 0;
BA_ "GenSigSendType" SG_ 2617119256 DEV_TME_RefrCir_tItCmprIn_VW_Data 0;
BA_ "GenSigSwitchedByIgnition" SG_ 2617119256 DEV_TME_RefrCir_tItCmprIn_VW_Data 0;
BA_ "GenSigSendType" SG_ 2617119256 DEV_TME_TmeDiag_idxDiagVlvRxvChilBatt_VW_Data 0;
BA_ "GenSigSwitchedByIgnition" SG_ 2617119256 DEV_TME_TmeDiag_idxDiagVlvRxvChilBatt_VW_Data 0;
BA_ "GenSigSendType" SG_ 2617119256 DEV_TME_TmeEm_tiSelPreCdnCab_VW_Data 0;
BA_ "GenSigSwitchedByIgnition" SG_ 2617119256 DEV_TME_TmeEm_tiSelPreCdnCab_VW_Data 0;
BA_ "GenSigSendType" SG_ 2617119256 DEV_TME_TmeEm_tiRawPreCdnCabEl_VW_Data 0;
BA_ "GenSigSwitchedByIgnition" SG_ 2617119256 DEV_TME_TmeEm_tiRawPreCdnCabEl_VW_Data 0;
BA_ "GenSigSendType" SG_ 2617119256 DEV_TME_TmeEm_tiOverRunPreCdnCabParkHeat_VW_Data 0;
BA_ "GenSigSwitchedByIgnition" SG_ 2617119256 DEV_TME_TmeEm_tiOverRunPreCdnCabParkHeat_VW_Data 0;
BA_ "GenSigSendType" SG_ 2617119257 DEV_TME_TmeFan_rFanDemMaxMes_VW_Data 0;
BA_ "GenSigSwitchedByIgnition" SG_ 2617119257 DEV_TME_TmeFan_rFanDemMaxMes_VW_Data 0;
BA_ "GenSigSendType" SG_ 2617119257 DEV_TME_WaHt_tWaHeat_VW_Data 0;
BA_ "GenSigSwitchedByIgnition" SG_ 2617119257 DEV_TME_WaHt_tWaHeat_VW_Data 0;
BA_ "GenSigSendType" SG_ 2617119257 DEV_TME_TmeDiag_tAirRadIn_VW_Data 0;
BA_ "GenSigSwitchedByIgnition" SG_ 2617119257 DEV_TME_TmeDiag_tAirRadIn_VW_Data 0;
BA_ "GenSigSendType" SG_ 2617119257 DEV_TME_TmeRcc_nCmprCtlAft2Lvl_VW_Data 0;
BA_ "GenSigSwitchedByIgnition" SG_ 2617119257 DEV_TME_TmeRcc_nCmprCtlAft2Lvl_VW_Data 0;
BA_ "GenSigSendType" SG_ 2617119257 DEV_TME_TmeDCM_tiCmprRunIn_VW_Data 0;
BA_ "GenSigSwitchedByIgnition" SG_ 2617119257 DEV_TME_TmeDCM_tiCmprRunIn_VW_Data 0;
BA_ "GenSigSendType" SG_ 2617119257 DEV_TME_TmeDem_bSetOfsSetVal_VW_Data 0;
BA_ "GenSigSwitchedByIgnition" SG_ 2617119257 DEV_TME_TmeDem_bSetOfsSetVal_VW_Data 0;
BA_ "GenSigSendType" SG_ 2617119257 DEV_TME_TmeDem_bEndHeatPmpSetChg_VW_Data 0;
BA_ "GenSigSwitchedByIgnition" SG_ 2617119257 DEV_TME_TmeDem_bEndHeatPmpSetChg_VW_Data 0;
BA_ "GenSigSendType" SG_ 2617119257 DEV_TME_TmeDem_tCoHeatExchInHeatPmpSetChg_VW_Data 0;
BA_ "GenSigSwitchedByIgnition" SG_ 2617119257 DEV_TME_TmeDem_tCoHeatExchInHeatPmpSetChg_VW_Data 0;
BA_ "GenSigSendType" SG_ 2617119257 DEV_TME_TmeCoc_rPmpRadOutMin_VW_Data 0;
BA_ "GenSigSwitchedByIgnition" SG_ 2617119257 DEV_TME_TmeCoc_rPmpRadOutMin_VW_Data 0;
BA_ "GenSigSendType" SG_ 2617119257 DEV_TME_TmeCoc_bElmCirRadPsbl_VW_Data 0;
BA_ "GenSigSwitchedByIgnition" SG_ 2617119257 DEV_TME_TmeCoc_bElmCirRadPsbl_VW_Data 0;
BA_ "GenSigSendType" SG_ 2617119257 DEV_TME_TmeHeatSrcCtl_stDiagRespFailMes_VW_Data 0;
BA_ "GenSigSwitchedByIgnition" SG_ 2617119257 DEV_TME_TmeHeatSrcCtl_stDiagRespFailMes_VW_Data 0;
BA_ "GenSigSendType" SG_ 2617119257 DEV_TME_TmeEm_bCalcVld_tiCalcPreCdnCabParkHeat_VW_Data 0;
BA_ "GenSigSwitchedByIgnition" SG_ 2617119257 DEV_TME_TmeEm_bCalcVld_tiCalcPreCdnCabParkHeat_VW_Data 0;
BA_ "GenSigSendType" SG_ 2617119257 DEV_TME_TmeRcc_bVlvEna_VW_Data 0;
BA_ "GenSigSwitchedByIgnition" SG_ 2617119257 DEV_TME_TmeRcc_bVlvEna_VW_Data 0;
BA_ "GenSigSendType" SG_ 2617119257 DEV_TME_TmeRcc_bMaxParCmprCtl_bMain_VW_Data 0;
BA_ "GenSigSwitchedByIgnition" SG_ 2617119257 DEV_TME_TmeRcc_bMaxParCmprCtl_bMain_VW_Data 0;
BA_ "GenSigSendType" SG_ 2617119258 DEV_TME_TmeEm_tiCalcPreCdnCabEl_VW_Data 0;
BA_ "GenSigSwitchedByIgnition" SG_ 2617119258 DEV_TME_TmeEm_tiCalcPreCdnCabEl_VW_Data 0;
BA_ "GenSigSendType" SG_ 2617119258 DEV_TME_RefrCir_tVlvHeatRegIn_VW_Data 0;
BA_ "GenSigSwitchedByIgnition" SG_ 2617119258 DEV_TME_RefrCir_tVlvHeatRegIn_VW_Data 0;
BA_ "GenSigSendType" SG_ 2617119258 DEV_TME_RefrCir_tVlvRefrExtcHeatReg_VW_Data 0;
BA_ "GenSigSwitchedByIgnition" SG_ 2617119258 DEV_TME_RefrCir_tVlvRefrExtcHeatReg_VW_Data 0;
BA_ "GenSigSendType" SG_ 2617119258 DEV_TME_RefrCir_tVlvCndsIn_VW_Data 0;
BA_ "GenSigSwitchedByIgnition" SG_ 2617119258 DEV_TME_RefrCir_tVlvCndsIn_VW_Data 0;
BA_ "GenSigSendType" SG_ 2617119258 DEV_TME_RefrCir_tRxvChilBatt_VW_Data 0;
BA_ "GenSigSwitchedByIgnition" SG_ 2617119258 DEV_TME_RefrCir_tRxvChilBatt_VW_Data 0;
BA_ "GenSigSendType" SG_ 2617119258 DEV_TME_RefrCir_rActStepVlvRefrExtcCnds_VW_Data 0;
BA_ "GenSigSwitchedByIgnition" SG_ 2617119258 DEV_TME_RefrCir_rActStepVlvRefrExtcCnds_VW_Data 0;
BA_ "GenSigSendType" SG_ 2617119258 DEV_TME_RefrCir_rActStepVlvCndsIn_VW_Data 0;
BA_ "GenSigSwitchedByIgnition" SG_ 2617119258 DEV_TME_RefrCir_rActStepVlvCndsIn_VW_Data 0;
BA_ "GenSigSendType" SG_ 2617119258 DEV_TME_RefrCir_rActStepVlvHeatRegIn_VW_Data 0;
BA_ "GenSigSwitchedByIgnition" SG_ 2617119258 DEV_TME_RefrCir_rActStepVlvHeatRegIn_VW_Data 0;
BA_ "GenSigSendType" SG_ 2617119258 DEV_TME_TmeEcu_tiMonth_VW_Data 0;
BA_ "GenSigSwitchedByIgnition" SG_ 2617119258 DEV_TME_TmeEcu_tiMonth_VW_Data 0;
BA_ "GenSigSendType" SG_ 2617119259 DEV_TME_RefrCir_rActStepRxvChilBatt_VW_Data 0;
BA_ "GenSigSwitchedByIgnition" SG_ 2617119259 DEV_TME_RefrCir_rActStepRxvChilBatt_VW_Data 0;
BA_ "GenSigSendType" SG_ 2617119259 DEV_TME_RefrCir_rActStepVlvRefrExtcHeatReg_VW_Data 0;
BA_ "GenSigSwitchedByIgnition" SG_ 2617119259 DEV_TME_RefrCir_rActStepVlvRefrExtcHeatReg_VW_Data 0;
BA_ "GenSigSendType" SG_ 2617119259 DEV_TME_ParkHtCtl_tiCalcPreCdnCabParkHeat_VW_Data 0;
BA_ "GenSigSwitchedByIgnition" SG_ 2617119259 DEV_TME_ParkHtCtl_tiCalcPreCdnCabParkHeat_VW_Data 0;
BA_ "GenSigSendType" SG_ 2617119259 DEV_TME_TmeCoc_pwrThmCoChil_VW_Data 0;
BA_ "GenSigSwitchedByIgnition" SG_ 2617119259 DEV_TME_TmeCoc_pwrThmCoChil_VW_Data 0;
BA_ "GenSigSendType" SG_ 2617119259 DEV_TME_TmeDCM_tiVenCoCir1_VW_Data 0;
BA_ "GenSigSwitchedByIgnition" SG_ 2617119259 DEV_TME_TmeDCM_tiVenCoCir1_VW_Data 0;
BA_ "GenSigSendType" SG_ 2617119259 DEV_TME_TmeDCM_tiVenCoCir2_VW_Data 0;
BA_ "GenSigSwitchedByIgnition" SG_ 2617119259 DEV_TME_TmeDCM_tiVenCoCir2_VW_Data 0;
BA_ "GenSigSendType" SG_ 2617119259 DEV_TME_TmeCoc_tDifCtlVlvHeatCir_VW_Data 0;
BA_ "GenSigSwitchedByIgnition" SG_ 2617119259 DEV_TME_TmeCoc_tDifCtlVlvHeatCir_VW_Data 0;
BA_ "GenSigSendType" SG_ 2617119259 DEV_TME_TmeEm_bAboPreCdnCab_VW_Data 0;
BA_ "GenSigSwitchedByIgnition" SG_ 2617119259 DEV_TME_TmeEm_bAboPreCdnCab_VW_Data 0;
BA_ "GenSigSendType" SG_ 2617119259 DEV_TME_TmeDem_stThmCmbEng_VW_Data 0;
BA_ "GenSigSwitchedByIgnition" SG_ 2617119259 DEV_TME_TmeDem_stThmCmbEng_VW_Data 0;
BA_ "GenSigSendType" SG_ 2617119260 DEV_TME_TmeCtl_stBattThmSelClas_VW_Data 0;
BA_ "GenSigSwitchedByIgnition" SG_ 2617119260 DEV_TME_TmeCtl_stBattThmSelClas_VW_Data 0;
BA_ "GenSigSendType" SG_ 2617119260 DEV_TME_TmeCtl_stMesCodSelConfPreCdnCab_VW_Data 0;
BA_ "GenSigSwitchedByIgnition" SG_ 2617119260 DEV_TME_TmeCtl_stMesCodSelConfPreCdnCab_VW_Data 0;
BA_ "GenSigSendType" SG_ 2617119260 DEV_TME_TmeCtl_stPreCdnCabAcv_VW_Data 0;
BA_ "GenSigSwitchedByIgnition" SG_ 2617119260 DEV_TME_TmeCtl_stPreCdnCabAcv_VW_Data 0;
BA_ "GenSigSendType" SG_ 2617119260 DEV_TME_TmeCtl_stPreCdnCabAvl_VW_Data 0;
BA_ "GenSigSwitchedByIgnition" SG_ 2617119260 DEV_TME_TmeCtl_stPreCdnCabAvl_VW_Data 0;
BA_ "GenSigSendType" SG_ 2617119260 DEV_TME_TmeCtl_bAcDispOn_VW_Data 0;
BA_ "GenSigSwitchedByIgnition" SG_ 2617119260 DEV_TME_TmeCtl_bAcDispOn_VW_Data 0;
BA_ "GenSigSendType" SG_ 2617119260 DEV_TME_TmeEcu_tiSec_VW_Data 0;
BA_ "GenSigSwitchedByIgnition" SG_ 2617119260 DEV_TME_TmeEcu_tiSec_VW_Data 0;
BA_ "GenSigSendType" SG_ 2617119260 DEV_TME_TmeCtl_bFcdParkHeatStgy_VW_Data 0;
BA_ "GenSigSwitchedByIgnition" SG_ 2617119260 DEV_TME_TmeCtl_bFcdParkHeatStgy_VW_Data 0;
BA_ "GenSigSendType" SG_ 2617119260 DEV_TME_TmeDiag_idxDiagTsCmbEngOut_VW_Data 0;
BA_ "GenSigSwitchedByIgnition" SG_ 2617119260 DEV_TME_TmeDiag_idxDiagTsCmbEngOut_VW_Data 0;
BA_ "GenSigSendType" SG_ 2617119260 DEV_TME_TmeCtl_stMesStgyPreCdnCabDyn_VW_Data 0;
BA_ "GenSigSwitchedByIgnition" SG_ 2617119260 DEV_TME_TmeCtl_stMesStgyPreCdnCabDyn_VW_Data 0;
BA_ "GenSigSendType" SG_ 2617119260 DEV_TME_TmeCtl_stMesThmCabPreCdnCab_VW_Data 0;
BA_ "GenSigSwitchedByIgnition" SG_ 2617119260 DEV_TME_TmeCtl_stMesThmCabPreCdnCab_VW_Data 0;
BA_ "GenSigSendType" SG_ 2617119260 DEV_TME_TmeCtl_bReqStgyPreCdnCabParkHeat_VW_Data 0;
BA_ "GenSigSwitchedByIgnition" SG_ 2617119260 DEV_TME_TmeCtl_bReqStgyPreCdnCabParkHeat_VW_Data 0;
BA_ "GenSigSendType" SG_ 2617119260 DEV_TME_TmeDCM_bParkHeatAvl_VW_Data 0;
BA_ "GenSigSwitchedByIgnition" SG_ 2617119260 DEV_TME_TmeDCM_bParkHeatAvl_VW_Data 0;
BA_ "GenSigSendType" SG_ 2617119261 DEV_TME_TmeCtl_tiIdlEcu_VW_Data 0;
BA_ "GenSigSwitchedByIgnition" SG_ 2617119261 DEV_TME_TmeCtl_tiIdlEcu_VW_Data 0;
BA_ "GenSigSendType" SG_ 2617119261 DEV_TME_TmeEcu_tiYear_VW_Data 0;
BA_ "GenSigSwitchedByIgnition" SG_ 2617119261 DEV_TME_TmeEcu_tiYear_VW_Data 0;
BA_ "GenSigSendType" SG_ 2617119261 DEV_TME_TmeEcu_tiDay_VW_Data 0;
BA_ "GenSigSwitchedByIgnition" SG_ 2617119261 DEV_TME_TmeEcu_tiDay_VW_Data 0;
BA_ "GenSigSendType" SG_ 2617119261 DEV_TME_TmeEcu_tiHour_VW_Data 0;
BA_ "GenSigSwitchedByIgnition" SG_ 2617119261 DEV_TME_TmeEcu_tiHour_VW_Data 0;
BA_ "GenSigSendType" SG_ 2617119261 DEV_TME_TmeEcu_tiMinute_VW_Data 0;
BA_ "GenSigSwitchedByIgnition" SG_ 2617119261 DEV_TME_TmeEcu_tiMinute_VW_Data 0;
BA_ "GenSigSendType" SG_ 2617119261 DEV_TME_TmeRcc_nCmprCtlMain_VW_Data 0;
BA_ "GenSigSwitchedByIgnition" SG_ 2617119261 DEV_TME_TmeRcc_nCmprCtlMain_VW_Data 0;
BA_ "GenSigSendType" SG_ 2617119261 DEV_TME_TmeVers_strPartVersInfo2_VW_Data 0;
BA_ "GenSigSwitchedByIgnition" SG_ 2617119261 DEV_TME_TmeVers_strPartVersInfo2_VW_Data 0;
BA_ "GenSigSendType" SG_ 2617119261 DEV_TME_TmeVers_strPartVersInfo1_VW_Data 0;
BA_ "GenSigSwitchedByIgnition" SG_ 2617119261 DEV_TME_TmeVers_strPartVersInfo1_VW_Data 0;
BA_ "GenSigSendType" SG_ 2617119261 DEV_TME_TmeCoc_rDemVlvHeatCirSml_VW_Data 0;
BA_ "GenSigSwitchedByIgnition" SG_ 2617119261 DEV_TME_TmeCoc_rDemVlvHeatCirSml_VW_Data 0;
BA_ "GenSigSendType" SG_ 2617119262 DEV_TME_TmeCtl_stMesCodPsblPreCdnCab_VW_Data 0;
BA_ "GenSigSwitchedByIgnition" SG_ 2617119262 DEV_TME_TmeCtl_stMesCodPsblPreCdnCab_VW_Data 0;
BA_ "GenSigSendType" SG_ 2617119262 DEV_TME_TmeCtl_stCodCdnSys2_VW_Data 0;
BA_ "GenSigSwitchedByIgnition" SG_ 2617119262 DEV_TME_TmeCtl_stCodCdnSys2_VW_Data 0;
BA_ "GenSigSendType" SG_ 2617119262 DEV_TME_TmeCtl_stCodCdnEnv2_VW_Data 0;
BA_ "GenSigSwitchedByIgnition" SG_ 2617119262 DEV_TME_TmeCtl_stCodCdnEnv2_VW_Data 0;
BA_ "GenSigSendType" SG_ 2617119263 DEV_TME_TmeVers_strPartVersInfo0_VW_Data 0;
BA_ "GenSigSwitchedByIgnition" SG_ 2617119263 DEV_TME_TmeVers_strPartVersInfo0_VW_Data 0;
BA_ "GenSigSendType" SG_ 2617119263 DEV_TME_TmeVers_strPartVersInfo3_VW_Data 0;
BA_ "GenSigSwitchedByIgnition" SG_ 2617119263 DEV_TME_TmeVers_strPartVersInfo3_VW_Data 0;
BA_ "GenSigSendType" SG_ 2617119263 DEV_TME_TmeRcc_nCmprCtlSlave_VW_Data 0;
BA_ "GenSigSwitchedByIgnition" SG_ 2617119263 DEV_TME_TmeRcc_nCmprCtlSlave_VW_Data 0;
BA_ "GenSigSendType" SG_ 2617119263 DEV_TME_TmeRcc_tCoHeatExchIn_VW_Data 0;
BA_ "GenSigSwitchedByIgnition" SG_ 2617119263 DEV_TME_TmeRcc_tCoHeatExchIn_VW_Data 0;
BA_ "GenSigSendType" SG_ 2617119263 DEV_TME_TmeDem_tAirAmb_VW_Data 0;
BA_ "GenSigSwitchedByIgnition" SG_ 2617119263 DEV_TME_TmeDem_tAirAmb_VW_Data 0;
BA_ "GenSigSendType" SG_ 2617119263 DEV_TME_TmeCtl_tiAcvEcu_VW_Data 0;
BA_ "GenSigSwitchedByIgnition" SG_ 2617119263 DEV_TME_TmeCtl_tiAcvEcu_VW_Data 0;
BA_ "GenSigSendType" SG_ 2617119263 DEV_TME_TmeCtl_tiGlbClk_VW_Data 0;
BA_ "GenSigSwitchedByIgnition" SG_ 2617119263 DEV_TME_TmeCtl_tiGlbClk_VW_Data 0;
BA_ "GenSigSendType" SG_ 2617119263 DEV_TME_TmeRcc_bMaxParRxvCtl_bMain_VW_Data 0;
BA_ "GenSigSwitchedByIgnition" SG_ 2617119263 DEV_TME_TmeRcc_bMaxParRxvCtl_bMain_VW_Data 0;
BA_ "GenSigSendType" SG_ 2617119264 DEV_TME_TmeCtl_stCodCdnSys1_VW_Data 0;
BA_ "GenSigSwitchedByIgnition" SG_ 2617119264 DEV_TME_TmeCtl_stCodCdnSys1_VW_Data 0;
BA_ "GenSigSendType" SG_ 2617119264 DEV_TME_TmeCtl_stCodCdnEnv1_VW_Data 0;
BA_ "GenSigSwitchedByIgnition" SG_ 2617119264 DEV_TME_TmeCtl_stCodCdnEnv1_VW_Data 0;
BA_ "GenSigSendType" SG_ 2617119265 DEV_TME_TmeCtl_stCodFailPreCdnCab_VW_Data 0;
BA_ "GenSigSwitchedByIgnition" SG_ 2617119265 DEV_TME_TmeCtl_stCodFailPreCdnCab_VW_Data 0;
BA_ "GenSigSendType" SG_ 2617119265 DEV_TME_TmeCtl_stCodSysConfCdnModl_VW_Data 0;
BA_ "GenSigSwitchedByIgnition" SG_ 2617119265 DEV_TME_TmeCtl_stCodSysConfCdnModl_VW_Data 0;
BA_ "GenSigSendType" SG_ 2617119265 DEV_TME_TmeCtl_stMesStgyPreCdnCabMap_VW_Data 0;
BA_ "GenSigSwitchedByIgnition" SG_ 2617119265 DEV_TME_TmeCtl_stMesStgyPreCdnCabMap_VW_Data 0;
BA_ "GenSigSendType" SG_ 2617119265 DEV_TME_TmeCtl_stMesThmCabChg_VW_Data 0;
BA_ "GenSigSwitchedByIgnition" SG_ 2617119265 DEV_TME_TmeCtl_stMesThmCabChg_VW_Data 0;
BA_ "GenSigSendType" SG_ 2617119265 DEV_TME_TmeCtl_stMesTranSmlCir_VW_Data 0;
BA_ "GenSigSwitchedByIgnition" SG_ 2617119265 DEV_TME_TmeCtl_stMesTranSmlCir_VW_Data 0;
BA_ "GenSigSendType" SG_ 2617119265 DEV_TME_TmeCtl_stMesTranPartCmbEng_VW_Data 0;
BA_ "GenSigSwitchedByIgnition" SG_ 2617119265 DEV_TME_TmeCtl_stMesTranPartCmbEng_VW_Data 0;
BA_ "GenSigSendType" SG_ 2617119265 DEV_TME_TmeCtl_stStgyPreCdnCabMes_VW_Data 0;
BA_ "GenSigSwitchedByIgnition" SG_ 2617119265 DEV_TME_TmeCtl_stStgyPreCdnCabMes_VW_Data 0;
BA_ "GenSigSendType" SG_ 2617119265 DEV_TME_TmeEm_bStatAcvPredCmft_VW_Data 0;
BA_ "GenSigSwitchedByIgnition" SG_ 2617119265 DEV_TME_TmeEm_bStatAcvPredCmft_VW_Data 0;
BA_ "GenSigSendType" SG_ 2617119265 DEV_TME_TmeEm_bSuppWinFirstTrigCabPred_VW_Data 0;
BA_ "GenSigSwitchedByIgnition" SG_ 2617119265 DEV_TME_TmeEm_bSuppWinFirstTrigCabPred_VW_Data 0;
BA_REL_ "GenSigTimeoutTime" BU_SG_REL_ AWC SG_ 686 DC_IstSpannung_NV 500;
BA_REL_ "GenSigTimeoutTime" BU_SG_REL_ BMC_MLBevo SG_ 1022 CHA_Ziel_FahrPr_BMS 5000;
BA_REL_ "GenSigTimeoutTime" BU_SG_REL_ BMC_MLBevo SG_ 686 DC_IstSpannung_HV 500;
BA_REL_ "GenSigTimeoutTime" BU_SG_REL_ DCDC_HV_02 SG_ 686 DC_IstSpannung_HV 500;
BA_REL_ "GenSigTimeoutTime" BU_SG_REL_ DCDC_HV_02 SG_ 686 DC_IstStrom_HV_02 500;
BA_REL_ "GenSigTimeoutTime" BU_SG_REL_ DCDC_HV_02 SG_ 1485 DC_IstModus_02 5000;
BA_REL_ "GenSigTimeoutTime" BU_SG_REL_ DCDC_IHEV SG_ 1443 BMS_MV_IstModus 5000;
BA_REL_ "GenSigTimeoutTime" BU_SG_REL_ DCDC_IHEV SG_ 2589283412 BMS_MV_Temperatur 5000;
BA_REL_ "GenSigTimeoutTime" BU_SG_REL_ Gateway SG_ 871 BMS_MV_03_CRC 1000;
BA_REL_ "GenSigTimeoutTime" BU_SG_REL_ Gateway SG_ 871 BMS_MV_03_BZ 1000;
BA_REL_ "GenSigTimeoutTime" BU_SG_REL_ Gateway SG_ 871 BMS_MV_Max_LadeSpannung 1000;
BA_REL_ "GenSigTimeoutTime" BU_SG_REL_ Gateway SG_ 871 BMS_MV_MaxPred_LadeStrom 1000;
BA_REL_ "GenSigTimeoutTime" BU_SG_REL_ Gateway SG_ 871 BMS_MV_Leistungsreduzierung 1000;
BA_REL_ "GenSigTimeoutTime" BU_SG_REL_ Gateway SG_ 1443 BMS_MV_04_CRC 5000;
BA_REL_ "GenSigTimeoutTime" BU_SG_REL_ Gateway SG_ 1443 BMS_MV_04_BZ 5000;
BA_REL_ "GenSigTimeoutTime" BU_SG_REL_ Gateway SG_ 1443 BMS_MV_IstModus 5000;
BA_REL_ "GenSigTimeoutTime" BU_SG_REL_ Gateway SG_ 1443 BMS_MV_FehlerStatus 5000;
BA_REL_ "GenSigTimeoutTime" BU_SG_REL_ Gateway SG_ 2589283412 BMS_MV_Speichertechnologie 5000;
BA_REL_ "GenSigTimeoutTime" BU_SG_REL_ Gateway SG_ 2589283412 BMS_MV_Temperatur 5000;
BA_REL_ "GenSigTimeoutTime" BU_SG_REL_ Gateway SG_ 2589283608 BMS_MV_Energieinhalt 5000;
BA_REL_ "GenSigTimeoutTime" BU_SG_REL_ Gateway SG_ 2589283608 BMS_MV_MaxEnergieinhalt 5000;
BA_REL_ "GenSigTimeoutTime" BU_SG_REL_ Gateway SG_ 2589283606 BMS_MV_SOC_Kaltstart 5000;
BA_REL_ "GenSigTimeoutTime" BU_SG_REL_ Gateway SG_ 2589283606 BMS_MV_max_Grenz_SOC 5000;
BA_REL_ "GenSigTimeoutTime" BU_SG_REL_ Gateway SG_ 499 BMS_NV_01_CRC 1000;
BA_REL_ "GenSigTimeoutTime" BU_SG_REL_ Gateway SG_ 499 BMS_NV_01_BZ 1000;
BA_REL_ "GenSigTimeoutTime" BU_SG_REL_ Gateway SG_ 499 BMS_NV_FMAus_Info 1000;
BA_REL_ "GenSigTimeoutTime" BU_SG_REL_ Gateway SG_ 499 BMS_NV_IstStrom 1000;
BA_REL_ "GenSigTimeoutTime" BU_SG_REL_ Gateway SG_ 499 BMS_NV_IstSpannung 1000;
BA_REL_ "GenSigTimeoutTime" BU_SG_REL_ Gateway SG_ 499 BMS_NV_BatterieAb 1000;
BA_REL_ "GenSigTimeoutTime" BU_SG_REL_ Gateway SG_ 499 BMS_NV_IstModus 1000;
BA_REL_ "GenSigTimeoutTime" BU_SG_REL_ Gateway SG_ 504 BMS_NV_Fehlerstatus 1000;
BA_REL_ "GenSigTimeoutTime" BU_SG_REL_ Gateway SG_ 504 BMS_NV_Qe_LI_Inhalt 1000;
BA_REL_ "GenSigTimeoutTime" BU_SG_REL_ Gateway SG_ 504 BMS_NV_IMaxStart 1000;
BA_REL_ "GenSigTimeoutTime" BU_SG_REL_ Gateway SG_ 504 BMS_NV_Ri_Batterie 1000;
BA_REL_ "GenSigTimeoutTime" BU_SG_REL_ Gateway SG_ 504 BMS_NV_SOC 1000;
BA_REL_ "GenSigTimeoutTime" BU_SG_REL_ Gateway SG_ 504 BMS_NV_UMinStart 1000;
BA_REL_ "GenSigTimeoutTime" BU_SG_REL_ Gateway SG_ 874 BMS_NV_Max_LadeStrom 5000;
BA_REL_ "GenSigTimeoutTime" BU_SG_REL_ Gateway SG_ 874 BMS_NV_Max_EntladeStrom 5000;
BA_REL_ "GenSigTimeoutTime" BU_SG_REL_ Gateway SG_ 874 BMS_NV_Max_LadeSpannung 5000;
BA_REL_ "GenSigTimeoutTime" BU_SG_REL_ Gateway SG_ 874 BMS_NV_Diagnose_Anf 5000;
BA_REL_ "GenSigTimeoutTime" BU_SG_REL_ Gateway SG_ 874 BMS_NV_Min_EntladeSpannung 5000;
BA_REL_ "GenSigTimeoutTime" BU_SG_REL_ Gateway SG_ 874 BMS_NV_Kapazitaet_akt 5000;
BA_REL_ "GenSigTimeoutTime" BU_SG_REL_ Gateway SG_ 874 BMS_NV_Temperatur 5000;
BA_REL_ "GenSigTimeoutTime" BU_SG_REL_ Gateway SG_ 2463978664 BMS_NV_Polspannung 1000;
BA_REL_ "GenSigTimeoutTime" BU_SG_REL_ Gateway SG_ 2463978720 BMS_NV_05_CRC 1000;
BA_REL_ "GenSigTimeoutTime" BU_SG_REL_ Gateway SG_ 2463978720 BMS_NV_05_BZ 1000;
BA_REL_ "GenSigTimeoutTime" BU_SG_REL_ Gateway SG_ 2463978720 BMS_NV_SollPred_EntladeSpannung 1000;
BA_REL_ "GenSigTimeoutTime" BU_SG_REL_ Gateway SG_ 2463978720 BMS_NV_SollDyn_EntladeSpannung 1000;
BA_REL_ "GenSigTimeoutTime" BU_SG_REL_ Gateway SG_ 2463978720 BMS_NV_IstDyn_EntladeStrom 1000;
BA_REL_ "GenSigTimeoutTime" BU_SG_REL_ Gateway SG_ 2463978720 BMS_NV_IstPred_EntladeStrom 1000;
BA_REL_ "GenSigTimeoutTime" BU_SG_REL_ Gateway SG_ 686 DCDC_01_CRC 500;
BA_REL_ "GenSigTimeoutTime" BU_SG_REL_ Gateway SG_ 686 DCDC_01_BZ 500;
BA_REL_ "GenSigTimeoutTime" BU_SG_REL_ Gateway SG_ 686 DC_IstSpannung_HV 500;
BA_REL_ "GenSigTimeoutTime" BU_SG_REL_ Gateway SG_ 686 DC_IstStrom_HV_02 500;
BA_REL_ "GenSigTimeoutTime" BU_SG_REL_ Gateway SG_ 686 DC_IstStrom_NV 500;
BA_REL_ "GenSigTimeoutTime" BU_SG_REL_ Gateway SG_ 686 DC_IstSpannung_NV 500;
BA_REL_ "GenSigTimeoutTime" BU_SG_REL_ Gateway SG_ 1012 DCDC_02_BZ 1000;
BA_REL_ "GenSigTimeoutTime" BU_SG_REL_ Gateway SG_ 1012 DC_HYB_iAktReserveLV 1000;
BA_REL_ "GenSigTimeoutTime" BU_SG_REL_ Gateway SG_ 1012 DC_Verbrauch_Ueberlauf 1000;
BA_REL_ "GenSigTimeoutTime" BU_SG_REL_ Gateway SG_ 1012 DC_Verbrauch 1000;
BA_REL_ "GenSigTimeoutTime" BU_SG_REL_ Gateway SG_ 1012 DC_HYB_Auslastungsgrad 1000;
BA_REL_ "GenSigTimeoutTime" BU_SG_REL_ Gateway SG_ 1485 DCDC_03_CRC 5000;
BA_REL_ "GenSigTimeoutTime" BU_SG_REL_ Gateway SG_ 1485 DCDC_03_BZ 5000;
BA_REL_ "GenSigTimeoutTime" BU_SG_REL_ Gateway SG_ 1485 DC_Fehlerstatus 5000;
BA_REL_ "GenSigTimeoutTime" BU_SG_REL_ Gateway SG_ 1485 DC_Peakstrom_verfuegbar 5000;
BA_REL_ "GenSigTimeoutTime" BU_SG_REL_ Gateway SG_ 1485 DC_IstModus_02 5000;
BA_REL_ "GenSigTimeoutTime" BU_SG_REL_ Gateway SG_ 1485 DC_Status_Spgfreiheit_HV 5000;
BA_REL_ "GenSigTimeoutTime" BU_SG_REL_ Gateway SG_ 1485 DC_IstSpannung_EKK_HV 5000;
BA_REL_ "GenSigTimeoutTime" BU_SG_REL_ Gateway SG_ 1485 DC_Temperatur 5000;
BA_REL_ "GenSigTimeoutTime" BU_SG_REL_ Gateway SG_ 2589283653 DCDC_HV_02_01_CRC 5000;
BA_REL_ "GenSigTimeoutTime" BU_SG_REL_ Gateway SG_ 2589283653 DCDC_HV_02_01_BZ 5000;
BA_REL_ "GenSigTimeoutTime" BU_SG_REL_ Gateway SG_ 2589283653 HVLB_IstModus_TN1 5000;
BA_REL_ "GenSigTimeoutTime" BU_SG_REL_ Gateway SG_ 2589283653 HVLB_StatusSpgfreiheit_HV 5000;
BA_REL_ "GenSigTimeoutTime" BU_SG_REL_ Gateway SG_ 2589283653 HVLB_IstSpannung_HVHS 5000;
BA_REL_ "GenSigTimeoutTime" BU_SG_REL_ Gateway SG_ 2589283653 HVLB_Fehlerstatus 5000;
BA_REL_ "GenSigTimeoutTime" BU_SG_REL_ Gateway SG_ 685 DCDC_MV_01_CRC 500;
BA_REL_ "GenSigTimeoutTime" BU_SG_REL_ Gateway SG_ 685 DCDC_MV_01_BZ 500;
BA_REL_ "GenSigTimeoutTime" BU_SG_REL_ Gateway SG_ 685 DC_MV_IstSpannung_MV 500;
BA_REL_ "GenSigTimeoutTime" BU_SG_REL_ Gateway SG_ 685 DC_MV_IstStrom_MV 500;
BA_REL_ "GenSigTimeoutTime" BU_SG_REL_ Gateway SG_ 685 DC_MV_IstStrom_NV 500;
BA_REL_ "GenSigTimeoutTime" BU_SG_REL_ Gateway SG_ 685 DC_MV_IstSpannung_NV 500;
BA_REL_ "GenSigTimeoutTime" BU_SG_REL_ Gateway SG_ 1018 DCDC_MV_02_CRC 1000;
BA_REL_ "GenSigTimeoutTime" BU_SG_REL_ Gateway SG_ 1018 DCDC_MV_02_BZ 1000;
BA_REL_ "GenSigTimeoutTime" BU_SG_REL_ Gateway SG_ 1018 DC_MV_akt_Stromreserve_NV 1000;
BA_REL_ "GenSigTimeoutTime" BU_SG_REL_ Gateway SG_ 1018 DC_MV_MaxStrom_MV 1000;
BA_REL_ "GenSigTimeoutTime" BU_SG_REL_ Gateway SG_ 1018 DC_MV_Auslastungsgrad 1000;
BA_REL_ "GenSigTimeoutTime" BU_SG_REL_ Gateway SG_ 1484 DCDC_MV_03_CRC 5000;
BA_REL_ "GenSigTimeoutTime" BU_SG_REL_ Gateway SG_ 1484 DCDC_MV_03_BZ 5000;
BA_REL_ "GenSigTimeoutTime" BU_SG_REL_ Gateway SG_ 1484 DCDC_MV_Peakstrom_verfuegbar 5000;
BA_REL_ "GenSigTimeoutTime" BU_SG_REL_ Gateway SG_ 1484 DC_MV_Tiefsetzen_Notbetrieb 5000;
BA_REL_ "GenSigTimeoutTime" BU_SG_REL_ Gateway SG_ 1484 DC_MV_Fehlerstatus 5000;
BA_REL_ "GenSigTimeoutTime" BU_SG_REL_ Gateway SG_ 1484 DC_MV_12V_Bordnetzstuetzung 5000;
BA_REL_ "GenSigTimeoutTime" BU_SG_REL_ Gateway SG_ 1484 DC_MV_IstModus 5000;
BA_REL_ "GenSigTimeoutTime" BU_SG_REL_ Gateway SG_ 1484 DC_MV_Dyn_MinSpannung 5000;
BA_REL_ "GenSigTimeoutTime" BU_SG_REL_ Gateway SG_ 1484 DC_MV_Dyn_MaxSpannung 5000;
BA_REL_ "GenSigTimeoutTime" BU_SG_REL_ Gateway_PAG SG_ 871 BMS_MV_03_CRC 1000;
BA_REL_ "GenSigTimeoutTime" BU_SG_REL_ Gateway_PAG SG_ 871 BMS_MV_03_BZ 1000;
BA_REL_ "GenSigTimeoutTime" BU_SG_REL_ Gateway_PAG SG_ 871 BMS_MV_Max_LadeSpannung 1000;
BA_REL_ "GenSigTimeoutTime" BU_SG_REL_ Gateway_PAG SG_ 871 BMS_MV_MaxPred_LadeStrom 1000;
BA_REL_ "GenSigTimeoutTime" BU_SG_REL_ Gateway_PAG SG_ 871 BMS_MV_Leistungsreduzierung 1000;
BA_REL_ "GenSigTimeoutTime" BU_SG_REL_ Gateway_PAG SG_ 1443 BMS_MV_04_CRC 5000;
BA_REL_ "GenSigTimeoutTime" BU_SG_REL_ Gateway_PAG SG_ 1443 BMS_MV_04_BZ 5000;
BA_REL_ "GenSigTimeoutTime" BU_SG_REL_ Gateway_PAG SG_ 1443 BMS_MV_IstModus 5000;
BA_REL_ "GenSigTimeoutTime" BU_SG_REL_ Gateway_PAG SG_ 1443 BMS_MV_FehlerStatus 5000;
BA_REL_ "GenSigTimeoutTime" BU_SG_REL_ Gateway_PAG SG_ 2589283412 BMS_MV_Speichertechnologie 5000;
BA_REL_ "GenSigTimeoutTime" BU_SG_REL_ Gateway_PAG SG_ 2589283412 BMS_MV_Temperatur 5000;
BA_REL_ "GenSigTimeoutTime" BU_SG_REL_ Gateway_PAG SG_ 2589283608 BMS_MV_Energieinhalt 5000;
BA_REL_ "GenSigTimeoutTime" BU_SG_REL_ Gateway_PAG SG_ 2589283608 BMS_MV_MaxEnergieinhalt 5000;
BA_REL_ "GenSigTimeoutTime" BU_SG_REL_ Gateway_PAG SG_ 2589283606 BMS_MV_SOC_Kaltstart 5000;
BA_REL_ "GenSigTimeoutTime" BU_SG_REL_ Gateway_PAG SG_ 2589283606 BMS_MV_max_Grenz_SOC 5000;
BA_REL_ "GenSigTimeoutTime" BU_SG_REL_ Gateway_PAG SG_ 499 BMS_NV_01_CRC 1000;
BA_REL_ "GenSigTimeoutTime" BU_SG_REL_ Gateway_PAG SG_ 499 BMS_NV_01_BZ 1000;
BA_REL_ "GenSigTimeoutTime" BU_SG_REL_ Gateway_PAG SG_ 499 BMS_NV_FMAus_Info 1000;
BA_REL_ "GenSigTimeoutTime" BU_SG_REL_ Gateway_PAG SG_ 499 BMS_NV_IstStrom 1000;
BA_REL_ "GenSigTimeoutTime" BU_SG_REL_ Gateway_PAG SG_ 499 BMS_NV_IstSpannung 1000;
BA_REL_ "GenSigTimeoutTime" BU_SG_REL_ Gateway_PAG SG_ 499 BMS_NV_BatterieAb 1000;
BA_REL_ "GenSigTimeoutTime" BU_SG_REL_ Gateway_PAG SG_ 499 BMS_NV_IstModus 1000;
BA_REL_ "GenSigTimeoutTime" BU_SG_REL_ Gateway_PAG SG_ 504 BMS_NV_Fehlerstatus 1000;
BA_REL_ "GenSigTimeoutTime" BU_SG_REL_ Gateway_PAG SG_ 504 BMS_NV_Qe_LI_Inhalt 1000;
BA_REL_ "GenSigTimeoutTime" BU_SG_REL_ Gateway_PAG SG_ 504 BMS_NV_IMaxStart 1000;
BA_REL_ "GenSigTimeoutTime" BU_SG_REL_ Gateway_PAG SG_ 504 BMS_NV_Ri_Batterie 1000;
BA_REL_ "GenSigTimeoutTime" BU_SG_REL_ Gateway_PAG SG_ 504 BMS_NV_SOC 1000;
BA_REL_ "GenSigTimeoutTime" BU_SG_REL_ Gateway_PAG SG_ 504 BMS_NV_UMinStart 1000;
BA_REL_ "GenSigTimeoutTime" BU_SG_REL_ Gateway_PAG SG_ 874 BMS_NV_Max_LadeStrom 5000;
BA_REL_ "GenSigTimeoutTime" BU_SG_REL_ Gateway_PAG SG_ 874 BMS_NV_Max_EntladeStrom 5000;
BA_REL_ "GenSigTimeoutTime" BU_SG_REL_ Gateway_PAG SG_ 874 BMS_NV_Max_LadeSpannung 5000;
BA_REL_ "GenSigTimeoutTime" BU_SG_REL_ Gateway_PAG SG_ 874 BMS_NV_Diagnose_Anf 5000;
BA_REL_ "GenSigTimeoutTime" BU_SG_REL_ Gateway_PAG SG_ 874 BMS_NV_Min_EntladeSpannung 5000;
BA_REL_ "GenSigTimeoutTime" BU_SG_REL_ Gateway_PAG SG_ 874 BMS_NV_Kapazitaet_akt 5000;
BA_REL_ "GenSigTimeoutTime" BU_SG_REL_ Gateway_PAG SG_ 874 BMS_NV_Temperatur 5000;
BA_REL_ "GenSigTimeoutTime" BU_SG_REL_ Gateway_PAG SG_ 2463978664 BMS_NV_Polspannung 1000;
BA_REL_ "GenSigTimeoutTime" BU_SG_REL_ Gateway_PAG SG_ 2463978720 BMS_NV_05_CRC 1000;
BA_REL_ "GenSigTimeoutTime" BU_SG_REL_ Gateway_PAG SG_ 2463978720 BMS_NV_05_BZ 1000;
BA_REL_ "GenSigTimeoutTime" BU_SG_REL_ Gateway_PAG SG_ 2463978720 BMS_NV_SollPred_EntladeSpannung 1000;
BA_REL_ "GenSigTimeoutTime" BU_SG_REL_ Gateway_PAG SG_ 2463978720 BMS_NV_SollDyn_EntladeSpannung 1000;
BA_REL_ "GenSigTimeoutTime" BU_SG_REL_ Gateway_PAG SG_ 2463978720 BMS_NV_IstDyn_EntladeStrom 1000;
BA_REL_ "GenSigTimeoutTime" BU_SG_REL_ Gateway_PAG SG_ 2463978720 BMS_NV_IstPred_EntladeStrom 1000;
BA_REL_ "GenSigTimeoutTime" BU_SG_REL_ Gateway_PAG SG_ 686 DCDC_01_CRC 500;
BA_REL_ "GenSigTimeoutTime" BU_SG_REL_ Gateway_PAG SG_ 686 DCDC_01_BZ 500;
BA_REL_ "GenSigTimeoutTime" BU_SG_REL_ Gateway_PAG SG_ 686 DC_IstSpannung_HV 500;
BA_REL_ "GenSigTimeoutTime" BU_SG_REL_ Gateway_PAG SG_ 686 DC_IstStrom_HV_02 500;
BA_REL_ "GenSigTimeoutTime" BU_SG_REL_ Gateway_PAG SG_ 686 DC_IstStrom_NV 500;
BA_REL_ "GenSigTimeoutTime" BU_SG_REL_ Gateway_PAG SG_ 686 DC_IstSpannung_NV 500;
BA_REL_ "GenSigTimeoutTime" BU_SG_REL_ Gateway_PAG SG_ 1012 DCDC_02_BZ 1000;
BA_REL_ "GenSigTimeoutTime" BU_SG_REL_ Gateway_PAG SG_ 1012 DC_HYB_iAktReserveLV 1000;
BA_REL_ "GenSigTimeoutTime" BU_SG_REL_ Gateway_PAG SG_ 1012 DC_Verbrauch_Ueberlauf 1000;
BA_REL_ "GenSigTimeoutTime" BU_SG_REL_ Gateway_PAG SG_ 1012 DC_Verbrauch 1000;
BA_REL_ "GenSigTimeoutTime" BU_SG_REL_ Gateway_PAG SG_ 1012 DC_HYB_Auslastungsgrad 1000;
BA_REL_ "GenSigTimeoutTime" BU_SG_REL_ Gateway_PAG SG_ 1485 DCDC_03_CRC 5000;
BA_REL_ "GenSigTimeoutTime" BU_SG_REL_ Gateway_PAG SG_ 1485 DCDC_03_BZ 5000;
BA_REL_ "GenSigTimeoutTime" BU_SG_REL_ Gateway_PAG SG_ 1485 DC_Fehlerstatus 5000;
BA_REL_ "GenSigTimeoutTime" BU_SG_REL_ Gateway_PAG SG_ 1485 DC_Peakstrom_verfuegbar 5000;
BA_REL_ "GenSigTimeoutTime" BU_SG_REL_ Gateway_PAG SG_ 1485 DC_IstModus_02 5000;
BA_REL_ "GenSigTimeoutTime" BU_SG_REL_ Gateway_PAG SG_ 1485 DC_Temperatur 5000;
BA_REL_ "GenSigTimeoutTime" BU_SG_REL_ Gateway_PAG SG_ 2589283653 DCDC_HV_02_01_CRC 5000;
BA_REL_ "GenSigTimeoutTime" BU_SG_REL_ Gateway_PAG SG_ 2589283653 DCDC_HV_02_01_BZ 5000;
BA_REL_ "GenSigTimeoutTime" BU_SG_REL_ Gateway_PAG SG_ 2589283653 HVLB_IstModus_TN1 5000;
BA_REL_ "GenSigTimeoutTime" BU_SG_REL_ Gateway_PAG SG_ 2589283653 HVLB_StatusSpgfreiheit_HV 5000;
BA_REL_ "GenSigTimeoutTime" BU_SG_REL_ Gateway_PAG SG_ 2589283653 HVLB_IstSpannung_HVHS 5000;
BA_REL_ "GenSigTimeoutTime" BU_SG_REL_ Gateway_PAG SG_ 2589283653 HVLB_Fehlerstatus 5000;
BA_REL_ "GenSigTimeoutTime" BU_SG_REL_ Gateway_PAG SG_ 685 DCDC_MV_01_CRC 500;
BA_REL_ "GenSigTimeoutTime" BU_SG_REL_ Gateway_PAG SG_ 685 DCDC_MV_01_BZ 500;
BA_REL_ "GenSigTimeoutTime" BU_SG_REL_ Gateway_PAG SG_ 685 DC_MV_IstSpannung_MV 500;
BA_REL_ "GenSigTimeoutTime" BU_SG_REL_ Gateway_PAG SG_ 685 DC_MV_IstStrom_MV 500;
BA_REL_ "GenSigTimeoutTime" BU_SG_REL_ Gateway_PAG SG_ 685 DC_MV_IstStrom_NV 500;
BA_REL_ "GenSigTimeoutTime" BU_SG_REL_ Gateway_PAG SG_ 685 DC_MV_IstSpannung_NV 500;
BA_REL_ "GenSigTimeoutTime" BU_SG_REL_ Gateway_PAG SG_ 1018 DCDC_MV_02_CRC 1000;
BA_REL_ "GenSigTimeoutTime" BU_SG_REL_ Gateway_PAG SG_ 1018 DCDC_MV_02_BZ 1000;
BA_REL_ "GenSigTimeoutTime" BU_SG_REL_ Gateway_PAG SG_ 1018 DC_MV_akt_Stromreserve_NV 1000;
BA_REL_ "GenSigTimeoutTime" BU_SG_REL_ Gateway_PAG SG_ 1018 DC_MV_MaxStrom_MV 1000;
BA_REL_ "GenSigTimeoutTime" BU_SG_REL_ Gateway_PAG SG_ 1018 DC_MV_Auslastungsgrad 1000;
BA_REL_ "GenSigTimeoutTime" BU_SG_REL_ Gateway_PAG SG_ 1484 DCDC_MV_03_CRC 5000;
BA_REL_ "GenSigTimeoutTime" BU_SG_REL_ Gateway_PAG SG_ 1484 DCDC_MV_03_BZ 5000;
BA_REL_ "GenSigTimeoutTime" BU_SG_REL_ Gateway_PAG SG_ 1484 DCDC_MV_Peakstrom_verfuegbar 5000;
BA_REL_ "GenSigTimeoutTime" BU_SG_REL_ Gateway_PAG SG_ 1484 DC_MV_Tiefsetzen_Notbetrieb 5000;
BA_REL_ "GenSigTimeoutTime" BU_SG_REL_ Gateway_PAG SG_ 1484 DC_MV_Fehlerstatus 5000;
BA_REL_ "GenSigTimeoutTime" BU_SG_REL_ Gateway_PAG SG_ 1484 DC_MV_12V_Bordnetzstuetzung 5000;
BA_REL_ "GenSigTimeoutTime" BU_SG_REL_ Gateway_PAG SG_ 1484 DC_MV_IstModus 5000;
BA_REL_ "GenSigTimeoutTime" BU_SG_REL_ Ladegeraet_2 SG_ 686 DC_IstSpannung_NV 500;
BA_REL_ "GenSigTimeoutTime" BU_SG_REL_ Ladegeraet_Konzern SG_ 686 DC_IstStrom_HV_02 500;
BA_REL_ "GenSigTimeoutTime" BU_SG_REL_ Ladegeraet_Konzern SG_ 686 DC_IstSpannung_NV 500;
BA_REL_ "GenSigTimeoutTime" BU_SG_REL_ Ladegeraet_Konzern SG_ 1485 DC_IstModus_02 5000;
BA_REL_ "GenSigTimeoutTime" BU_SG_REL_ Ladegeraet_Konzern SG_ 2589283653 DCDC_HV_02_01_CRC 5000;
BA_REL_ "GenSigTimeoutTime" BU_SG_REL_ Ladegeraet_Konzern SG_ 2589283653 DCDC_HV_02_01_BZ 5000;
BA_REL_ "GenSigTimeoutTime" BU_SG_REL_ Ladegeraet_Konzern SG_ 2589283653 HVLB_IstSpannung_DCLS 5000;
BA_REL_ "GenSigTimeoutTime" BU_SG_REL_ Ladegeraet_Konzern SG_ 2589283653 HVLB_IstModus 5000;
BA_REL_ "GenSigTimeoutTime" BU_SG_REL_ Ladegeraet_Konzern SG_ 2589283653 HVLB_IstStrom_HVHS 5000;
BA_REL_ "GenSigTimeoutTime" BU_SG_REL_ Ladegeraet_Konzern SG_ 2589283653 HVLB_IstSpannung_HVHS 5000;
BA_REL_ "GenSigTimeoutTime" BU_SG_REL_ Ladegeraet_Konzern SG_ 2589283653 HVLB_DC_Laden_ohneBoost_verfuegb 5000;
BA_REL_ "GenSigTimeoutTime" BU_SG_REL_ Ladegeraet_Konzern SG_ 2589283653 HVLB_DC_Laden_mitBoost_verfuegb 5000;
BA_REL_ "GenSigTimeoutTime" BU_SG_REL_ Ladegeraet_Konzern SG_ 2589283653 HVLB_AC_Laden_verfuegbar 5000;
BA_REL_ "GenSigTimeoutTime" BU_SG_REL_ Ladegeraet_Konzern SG_ 2589283653 HVLB_Warnzustand 5000;
BA_REL_ "GenSigTimeoutTime" BU_SG_REL_ Ladegeraet_Konzern SG_ 2589283653 HVLB_Fehlerstatus 5000;
BA_REL_ "GenSigTimeoutTime" BU_SG_REL_ Ladegeraet_Konzern SG_ 2463978669 DCDC_HV_02_02_CRC 1000;
BA_REL_ "GenSigTimeoutTime" BU_SG_REL_ Ladegeraet_Konzern SG_ 2463978669 DCDC_HV_02_02_BZ 1000;
BA_REL_ "GenSigTimeoutTime" BU_SG_REL_ Ladegeraet_Konzern SG_ 2463978669 HVLB_IstSpannung_HVLS 1000;
BA_REL_ "GenSigTimeoutTime" BU_SG_REL_ Ladegeraet_Konzern SG_ 2463978669 HVLB_MaxDynStrom_HVLS 1000;
BA_REL_ "GenSigTimeoutTime" BU_SG_REL_ Ladegeraet_Konzern SG_ 2589283662 HVLB_PlanAntw_Verlustleistung 5000;
BA_REL_ "GenSigTimeoutTime" BU_SG_REL_ Ladegeraet_Konzern SG_ 2589283662 HVLB_PlanAntw_Zaehler 5000;
BA_REL_ "GenSigTimeoutTime" BU_SG_REL_ TME SG_ 2589283412 BMS_MV_Temperierung_Anf 5000;
BA_REL_ "GenSigTimeoutTime" BU_SG_REL_ TME SG_ 2589283412 BMS_MV_Temp_Epsilon 5000;
BA_REL_ "GenSigTimeoutTime" BU_SG_REL_ TME SG_ 2589283412 BMS_MV_Soll_PWM_Pumpe 5000;
BA_REL_ "GenSigTimeoutTime" BU_SG_REL_ TME SG_ 2589283412 BMS_MV_Temperatur 5000;
BA_REL_ "GenSigTimeoutTime" BU_SG_REL_ TME SG_ 2589283412 BMS_MV_IstVorlaufTemperatur 5000;
BA_REL_ "GenSigTimeoutTime" BU_SG_REL_ TME SG_ 2589283412 BMS_MV_SollVolumenstrom 5000;
BA_REL_ "GenSigTimeoutTime" BU_SG_REL_ TME SG_ 2589283412 BMS_MV_SollVorlauftemperatur 5000;
BA_REL_ "GenSigTimeoutTime" BU_SG_REL_ TME SG_ 2589283412 BMS_MV_IstRuecklaufTemperatur 5000;
BA_REL_ "GenSigTimeoutTime" BU_SG_REL_ TME SG_ 901 CHA_Ziel_FahrPr_MO_BZS 5000;
BA_REL_ "GenSigTimeoutTime" BU_SG_REL_ TME SG_ 686 DC_IstSpannung_HV 500;
BA_REL_ "GenSigTimeoutTime" BU_SG_REL_ TME SG_ 686 DC_IstStrom_HV_02 500;
BA_REL_ "GenSigTimeoutTime" BU_SG_REL_ TME SG_ 1012 DC_Verlustleistung 1000;
BA_REL_ "GenSigTimeoutTime" BU_SG_REL_ TME SG_ 1012 DC_HYB_Auslastungsgrad 1000;
BA_REL_ "GenSigTimeoutTime" BU_SG_REL_ TME SG_ 1485 DC_Abregelung_Temperatur 5000;
BA_REL_ "GenSigTimeoutTime" BU_SG_REL_ TME SG_ 1485 DC_IstModus_02 5000;
BA_REL_ "GenSigTimeoutTime" BU_SG_REL_ TME SG_ 1485 DC_Temperatur 5000;
BA_REL_ "GenSigTimeoutTime" BU_SG_REL_ TME SG_ 2589283653 HVLB_IstModus 5000;
BA_REL_ "GenSigTimeoutTime" BU_SG_REL_ TME SG_ 2463978669 HVLB_Temperatur 1000;
BA_REL_ "GenSigTimeoutTime" BU_SG_REL_ TME SG_ 2589283662 HVLB_PlanAntw_Verlustleistung 5000;
BA_REL_ "GenSigTimeoutTime" BU_SG_REL_ TME SG_ 2589283662 HVLB_PlanAntw_Zaehler 5000;
BA_REL_ "GenSigTimeoutTime" BU_SG_REL_ TME SG_ 1484 DC_MV_Abregelung_Temperatur 5000;
BA_REL_ "GenSigTimeoutTime" BU_SG_REL_ TME SG_ 1484 DC_MV_Temperatur 5000;
VAL_ 871 BMS_MV_Max_LadeSpannung 254 "Init" 255 "Fehler" ;
VAL_ 871 BMS_MV_MaxPred_EntladeStrom 2046 "Init" 2047 "Fehler" ;
VAL_ 871 BMS_MV_MaxPred_LadeStrom 2046 "Init" 2047 "Fehler" ;
VAL_ 871 BMS_MV_MinPred_EntladeSpannung 254 "Init" ;
VAL_ 871 BMS_MV_MinPred_LadeSpannung 254 "Init" ;
VAL_ 871 BMS_MV_Leistungsreduzierung 0 "inaktiv" 1 "aktiv" ;
VAL_ 1443 BMS_MV_OBD_Lampe_Anf 0 "Init" 1 "MIL_Request" ;
VAL_ 1443 BMS_MV_IstModus 0 "stStdBy" 1 "stMV" 5 "Error_Batt" 7 "stInit" ;
VAL_ 1443 BMS_MV_FehlerStatus 0 "Komponente_IO" 3 "Vorwarnung_KompFkt" 4 "Keine_KompFkt_Uebertemperatur" 5 "Eingeschr_KompFkt_Leistungsred" 6 "Keine_Komponentenfunktion" 7 "Init" ;
VAL_ 2589283412 BMS_MV_Temperierung_Anf 0 "hoher_Kuehlbedarf" 1 "mittlerer_Kuehlbedarf" 2 "niedriger_Kuehlbedarf" 3 "kein_Temperierungsbedarf_Init" 4 "niedriger_Heizbedarf" 5 "mittlerer_Heizbedarf" 6 "hoher_Heizbedarf" 7 "Umwaelzungsbedarf" ;
VAL_ 2589283412 BMS_MV_Speichertechnologie 0 "Technologie_0" 1 "Technologie_1" 2 "Technologie_2" 3 "Technologie_3" 4 "Technologie_4" 5 "Technologie_5" 6 "Technologie_6" 7 "Technologie_unbekannt" ;
VAL_ 2589283412 BMS_MV_Soll_PWM_Pumpe 15 "Init" ;
VAL_ 2589283412 BMS_MV_Temperatur 254 "Init" 255 "Fehler" ;
VAL_ 2589283412 BMS_MV_IstVorlaufTemperatur 254 "Init" 255 "Fehler" ;
VAL_ 2589283412 BMS_MV_SollVolumenstrom 62 "Init" 63 "Fehler" ;
VAL_ 2589283412 BMS_MV_SollVorlauftemperatur 254 "Init" 255 "Fehler" ;
VAL_ 2589283412 BMS_MV_IstRuecklaufTemperatur 254 "Init" 255 "Fehler" ;
VAL_ 2589283608 BMS_MV_Energieinhalt 2046 "Init" 2047 "Fehler" ;
VAL_ 2589283608 BMS_MV_MaxEnergieinhalt 2046 "Init" 2047 "Fehler" ;
VAL_ 2589283606 BMS_MV_SOC_Kaltstart 2046 "Init" 2047 "Fehler" ;
VAL_ 2589283606 BMS_MV_max_Grenz_SOC 31 "Init" ;
VAL_ 1021 BMS_MV_Pred_Entladeperformance 126 "Init" 127 "Fehler" ;
VAL_ 1021 BMS_MV_Pred_Ladeperformance 126 "Init" 127 "Fehler" ;
VAL_ 499 BMS_NV_FMAus_Info 0 "Motorlauf_langfristig_nicht_notwendig_FMAus_freigabe" 1 "Motoranlauf_nicht_zwingend_notwendig_Stoppverbot_keine_Startanforderung" 2 "Motoranlauf_zwingend_notwendig_Startanforderung" 3 "Systemfehler" ;
VAL_ 499 BMS_NV_TE_Status 0 "Trennelement_offen" 1 "Trennelement_garantiert_geschlossen" 2 "Trennelement_geschlossen" 3 "Trennelement_geschlossen_Mindestzeit" ;
VAL_ 499 BMS_NV_IstStrom 262142 "Init" 262143 "Fehler" ;
VAL_ 499 BMS_NV_IstSpannung 16382 "Init" 16383 "Fehler" ;
VAL_ 499 BMS_NV_StSt_Nutzbare_Ladung 254 "Init" 255 "Fehler" ;
VAL_ 499 BMS_NV_BatterieAb 0 "Batterie_nicht_ab" 1 "Batterie_ab" ;
VAL_ 499 BMS_NV_IstModus 0 "TE_offen" 1 "TE_geschlossen" 2 "Fehler" 3 "Init" ;
VAL_ 504 BMS_NV_Fehlerstatus 0 "Komponente_IO" 1 "TE_defekt" 7 "Init" ;
VAL_ 504 BMS_NV_Qe_LI_Inhalt 4001 "Out_of_Range" 4094 "Init" 4095 "Fehler" ;
VAL_ 504 BMS_NV_IMaxStart 254 "Init" 255 "Fehler" ;
VAL_ 504 BMS_NV_Ri_Batterie 254 "Init" 255 "Fehler" ;
VAL_ 504 BMS_NV_SOC 254 "Init" 255 "Fehler" ;
VAL_ 504 BMS_NV_UMinStart 254 "Init" 255 "Fehler" ;
VAL_ 874 BMS_NV_Max_LadeStrom 1022 "Init" 1023 "Fehler" ;
VAL_ 874 BMS_NV_Max_EntladeStrom 1022 "Init" 1023 "Fehler" ;
VAL_ 874 BMS_NV_Max_LadeSpannung 62 "Init" 63 "Fehler" ;
VAL_ 874 BMS_NV_Diagnose_Anf 0 "keine_Massnahme_noetig" 1 "Anforderung_Stufe_1" 2 "Anforderung_Stufe_2" 3 "Anforderung_Stufe_3" 7 "Init" ;
VAL_ 874 BMS_NV_Min_EntladeSpannung 62 "Init" 63 "Fehler" ;
VAL_ 874 BMS_NV_Kapazitaet_akt 510 "Init" 511 "Fehler" ;
VAL_ 874 BMS_NV_Temperatur 254 "Init" 255 "Fehler" ;
VAL_ 2463978664 BMS_NV_Polspannung 510 "Init" 511 "Fehler" ;
VAL_ 2463978720 BMS_NV_SollPred_EntladeSpannung 254 "Init" 255 "Fehler" ;
VAL_ 2463978720 BMS_NV_SollDyn_EntladeSpannung 254 "Init" 255 "Fehler" ;
VAL_ 2463978720 BMS_NV_IstDyn_EntladeStrom 2046 "Init" 2047 "Fehler" ;
VAL_ 2463978720 BMS_NV_IstPred_EntladeStrom 2046 "Init" 2047 "Fehler" ;
VAL_ 901 CHA_Ziel_FahrPr_AGA 0 "keine_Funktion" 1 "Programm_1" 2 "Programm_2" 3 "Programm_3" 4 "Programm_4" 5 "Programm_5" 6 "Programm_6" 7 "Programm_7" 8 "Programm_8" 9 "Programm_9" 10 "Programm_10" 11 "Programm_11" 12 "Programm_12" 13 "Programm_13" 14 "Programm_14" 15 "Programm_15" ;
VAL_ 901 CHA_Ziel_FahrPr_ESP 0 "keine_Funktion" 1 "Programm_1" 2 "Programm_2" 3 "Programm_3" 4 "Programm_4" 5 "Programm_5" 6 "Programm_6" 7 "Programm_7" 8 "Programm_8" 9 "Programm_9" 10 "Programm_10" 11 "Programm_11" 12 "Programm_12" 13 "Programm_13" 14 "Programm_14" 15 "Programm_15" ;
VAL_ 901 CHA_Ziel_FahrPr_Freilauf 0 "keine_Funktion" 1 "Programm_1" 2 "Programm_2" 3 "Programm_3" 4 "Programm_4" 5 "Programm_5" 6 "Programm_6" 7 "Programm_7" 8 "Programm_8" 9 "Programm_9" 10 "Programm_10" 11 "Programm_11" 12 "Programm_12" 13 "Programm_13" 14 "Programm_14" 15 "Programm_15" ;
VAL_ 901 CHA_Fahrer_Umschaltung 0 "keine_oder_automatische_Umschaltung" 1 "manuelle_Umschaltung" ;
VAL_ 901 CHA_Fahrer_Umschaltung_BMA 0 "keine_oder_autom_Umschaltung" 1 "manuelle_Umschaltung" ;
VAL_ 901 CHA_Ziel_FahrPr_MO 0 "keine_Funktion" 1 "Programm_1" 2 "Programm_2" 3 "Programm_3" 4 "Programm_4" 5 "Programm_5" 6 "Programm_6" 7 "Programm_7" 8 "Programm_8" 9 "Programm_9" 10 "Programm_10" 11 "Programm_11" 12 "Programm_12" 13 "Programm_13" 14 "Programm_14" 15 "Programm_15" ;
VAL_ 901 CHA_Ziel_FahrPr_GE 0 "keine_Funktion" 1 "Programm_1" 2 "Programm_2" 3 "Programm_3" 4 "Programm_4" 5 "Programm_5" 6 "Programm_6" 7 "Programm_7" 8 "Programm_8" 9 "Programm_9" 10 "Programm_10" 11 "Programm_11" 12 "Programm_12" 13 "Programm_13" 14 "Programm_14" 15 "Programm_15" ;
VAL_ 901 CHA_Ziel_FahrPr_ALR 0 "keine_Funktion" 1 "Programm_1" 2 "Programm_2" 3 "Programm_3" 4 "Programm_4" 5 "Programm_5" 6 "Programm_6" 7 "Programm_7" 8 "Programm_8" 9 "Programm_9" 10 "Programm_10" 11 "Programm_11" 12 "Programm_12" 13 "Programm_13" 14 "Programm_14" 15 "Programm_15" ;
VAL_ 901 CHA_Ziel_FahrPr_MO_BZS 0 "keine_Funktion" 1 "Programm_1" 2 "Programm_2" 3 "Programm_3" 4 "Programm_4" 5 "Programm_5" 6 "Programm_6" 7 "Programm_7" 8 "Programm_8" 9 "Programm_9" 10 "Programm_10" 11 "Programm_11" 12 "Programm_12" 13 "Programm_13" 14 "Programm_14" 15 "Programm_15" ;
VAL_ 901 CHA_Ziel_FahrPr_DR 0 "keine_Funktion" 1 "Programm_1" 2 "Programm_2" 3 "Programm_3" 4 "Programm_4" 5 "Programm_5" 6 "Programm_6" 7 "Programm_7" 8 "Programm_8" 9 "Programm_9" 10 "Programm_10" 11 "Programm_11" 12 "Programm_12" 13 "Programm_13" 14 "Programm_14" 15 "Programm_15" ;
VAL_ 901 CHA_Ziel_FahrPr_VAQ 0 "keine_Funktion" 1 "Programm_1" 2 "Programm_2" 3 "Programm_3" 4 "Programm_4" 5 "Programm_5" 6 "Programm_6" 7 "Programm_7" 8 "Programm_8" 9 "Programm_9" 10 "Programm_10" 11 "Programm_11" 12 "Programm_12" 13 "Programm_13" 14 "Programm_14" 15 "Programm_15" ;
VAL_ 901 CHA_Ziel_FahrPr_AFS 0 "keine_Funktion" 1 "Programm_1" 2 "Programm_2" 3 "Programm_3" 4 "Programm_4" 5 "Programm_5" 6 "Programm_6" 7 "Programm_7" 8 "Programm_8" 9 "Programm_9" 10 "Programm_10" 11 "Programm_11" 12 "Programm_12" 13 "Programm_13" 14 "Programm_14" 15 "Programm_15" ;
VAL_ 901 CHA_Ziel_FahrPr_PreCrash 0 "keine_Funktion" 1 "Programm_1" 2 "Programm_2" 3 "Programm_3" 4 "Programm_4" 5 "Programm_5" 6 "Programm_6" 7 "Programm_7" 8 "Programm_8" 9 "Programm_9" 10 "Programm_10" 11 "Programm_11" 12 "Programm_12" 13 "Programm_13" 14 "Programm_14" 15 "Programm_15" ;
VAL_ 901 CHA_Ziel_FahrPr_EPS 0 "keine_Funktion" 1 "Programm_1" 2 "Programm_2" 3 "Programm_3" 4 "Programm_4" 5 "Programm_5" 6 "Programm_6" 7 "Programm_7" 8 "Programm_8" 9 "Programm_9" 10 "Programm_10" 11 "Programm_11" 12 "Programm_12" 13 "Programm_13" 14 "Programm_14" 15 "Programm_15" ;
VAL_ 901 CHA_Ziel_FahrPr_ACC 0 "keine_Funktion" 1 "Programm_1" 2 "Programm_2" 3 "Programm_3" 4 "Programm_4" 5 "Programm_5" 6 "Programm_6" 7 "Programm_7" 8 "Programm_8" 9 "Programm_9" 10 "Programm_10" 11 "Programm_11" 12 "Programm_12" 13 "Programm_13" 14 "Programm_14" 15 "Programm_15" ;
VAL_ 901 CHA_Ziel_FahrPr_SAK 0 "keine_Funktion" 1 "Programm_1" 2 "Programm_2" 3 "Programm_3" 4 "Programm_4" 5 "Programm_5" 6 "Programm_6" 7 "Programm_7" 8 "Programm_8" 9 "Programm_9" 10 "Programm_10" 11 "Programm_11" 12 "Programm_12" 13 "Programm_13" 14 "Programm_14" 15 "Programm_15" ;
VAL_ 901 CHA_Ziel_FahrPr_MO_StSt 0 "keine_Funktion" 1 "Programm_1" 2 "Programm_2" 3 "Programm_3" 4 "Programm_4" 5 "Programm_5" 6 "Programm_6" 7 "Programm_7" 8 "Programm_8" 9 "Programm_9" 10 "Programm_10" 11 "Programm_11" 12 "Programm_12" 13 "Programm_13" 14 "Programm_14" 15 "Programm_15" ;
VAL_ 1022 CHA_Fahrer_Umschaltung 0 "keine_oder_automatische_Umschaltung" 1 "manuelle_Umschaltung" ;
VAL_ 1022 CHA_Fahrer_Umschaltung_BMA 0 "keine_oder_autom_Umschaltung" 1 "manuelle_Umschaltung" ;
VAL_ 1022 CHA_Ziel_FahrPr_Reku_ZwGas 0 "kein_Funktion" 1 "Programm_1" 2 "Programm_2" 3 "Programm_3" 4 "Programm_4" 5 "Programm_5" 6 "Programm_6" 7 "Programm_7" 8 "Programm_8" 9 "Programm_9" 10 "Programm_10" 11 "Programm_11" 12 "Programm_12" 13 "Programm_13" 14 "Programm_14" 15 "Programm_15" ;
VAL_ 1022 CHA_Ziel_FahrPr_MO_Freilauf 0 "keine_Funktion" 1 "Programm_1" 2 "Programm_2" 3 "Programm_3" 4 "Programm_4" 5 "Programm_5" 6 "Programm_6" 7 "Programm_7" 8 "Programm_8" 9 "Programm_9" 10 "Programm_10" 11 "Programm_11" 12 "Programm_12" 13 "Programm_13" 14 "Programm_14" 15 "Programm_15" ;
VAL_ 1022 CHA_Ziel_FahrPr_BMS 0 "keine_Funktion" 1 "Programm_1" 2 "Programm_2" 3 "Programm_3" 4 "Programm_4" 5 "Programm_5" 6 "Programm_6" 7 "Programm_7" 8 "Programm_8" 9 "Programm_9" 10 "Programm_10" 11 "Programm_11" 12 "Programm_12" 13 "Programm_13" 14 "Programm_14" 15 "Programm_15" ;
VAL_ 1022 CHA_Current_Mode_BMA 0 "keine_Funktion" 1 "Programm_1" 2 "Programm_2" 3 "Programm_3" 4 "Programm_4" 5 "Programm_5" 6 "Programm_6" 7 "Programm_7" 8 "Programm_8" 9 "Programm_9" 10 "Programm_10" 11 "Programm_11" 12 "Programm_12" 13 "Programm_13" 14 "Programm_14" 15 "Programm_15" ;
VAL_ 1022 CHA_Ziel_FahrPr_PDC 0 "keine_Funktion" 1 "Programm_1" 2 "Programm_2" 3 "Programm_3" 4 "Programm_4" 5 "Programm_5" 6 "Programm_6" 7 "Programm_7" 8 "Programm_8" 9 "Programm_9" 10 "Programm_10" 11 "Programm_11" 12 "Programm_12" 13 "Programm_13" 14 "Programm_14" 15 "Programm_15" ;
VAL_ 1022 CHA_Ziel_FahrPr_HHC 0 "keine_Funktion" 1 "Programm_1" 2 "Programm_2" 3 "Programm_3" 4 "Programm_4" 5 "Programm_5" 6 "Programm_6" 7 "Programm_7" 8 "Programm_8" 9 "Programm_9" 10 "Programm_10" 11 "Programm_11" 12 "Programm_12" 13 "Programm_13" 14 "Programm_14" 15 "Programm_15" ;
VAL_ 1022 CHA_Ziel_FahrPr_EDS 0 "keine_Funktion" 1 "Programm_1" 2 "Programm_2" 3 "Programm_3" 4 "Programm_4" 5 "Programm_5" 6 "Programm_6" 7 "Programm_7" 8 "Programm_8" 9 "Programm_9" 10 "Programm_10" 11 "Programm_11" 12 "Programm_12" 13 "Programm_13" 14 "Programm_14" 15 "Programm_15" ;
VAL_ 1022 CHA_Ziel_FahrPr_PACC 0 "keine_Funktion" 1 "Programm_1" 2 "Programm_2" 3 "Programm_3" 4 "Programm_4" 5 "Programm_5" 6 "Programm_6" 7 "Programm_7" 8 "Programm_8" 9 "Programm_9" 10 "Programm_10" 11 "Programm_11" 12 "Programm_12" 13 "Programm_13" 14 "Programm_14" 15 "Programm_15" ;
VAL_ 1022 CHA_Ziel_FahrPr_AGK 0 "keine_Funktion" 1 "Programm_1" 2 "Programm_2" 3 "Programm_3" 4 "Programm_4" 5 "Programm_5" 6 "Programm_6" 7 "Programm_7" 8 "Programm_8" 9 "Programm_9" 10 "Programm_10" 11 "Programm_11" 12 "Programm_12" 13 "Programm_13" 14 "Programm_14" 15 "Programm_15" ;
VAL_ 686 DC_IstSpannung_HV 4094 "Init" 4095 "Fehler" ;
VAL_ 686 DC_IstStrom_HV_02 1022 "Init" 1023 "Fehler" ;
VAL_ 686 DC_IstStrom_NV 1022 "Init" 1023 "Fehler" ;
VAL_ 686 DC_IstSpannung_NV 254 "Init" 255 "Fehler" ;
VAL_ 1012 DC_HYB_iAktReserveLV 1022 "Init" 1023 "Fehler" ;
VAL_ 1012 DC_Verbrauch_Ueberlauf 0 "kein_Ueberlauf" 1 "Ueberlauf" ;
VAL_ 1012 DC_Verlustleistung 62 "Init" 63 "Fehler" ;
VAL_ 1012 DC_HYB_Auslastungsgrad 254 "Init" 255 "Fehler" ;
VAL_ 1485 DC_Fehlerstatus 0 "Komponente_IO" 1 "Eingeschr_KompFkt_Entlad_defekt" 3 "Eingeschr_KompFkt_Interlock" 6 "Keine_Komponentenfunktion" 7 "Init" ;
VAL_ 1485 DC_Peakstrom_verfuegbar 0 "Peakstrom_nicht_verfuegbar" 1 "Peakstrom_verfuegbar" ;
VAL_ 1485 DC_Abregelung_Temperatur 0 "keine_Abregelung" 1 "Abregelung_Temp" ;
VAL_ 1485 DC_IstModus_02 0 "Standby" 1 "HV_On" 2 "Tiefsetzen" 3 "Hochsetzen" 5 "Fehler" 7 "Initialisierung" ;
VAL_ 1485 DC_Status_Spgfreiheit_HV 0 "Init" 1 "HV_Komponente_spannungsfrei" 2 "HV_Komp_nicht_spannungsfrei" 3 "Fehler_nicht_spannungsfrei" ;
VAL_ 1485 DC_IstSpannung_EKK_HV 255 "Init" ;
VAL_ 1485 DC_Temperatur 254 "Init" 255 "Fehler" ;
VAL_ 2589283653 HVLB_IstModus_TN1 0 "HV_Off" 1 "HV_On" 2 "Fehler" 3 "Initialisierung" ;
VAL_ 2589283653 HVLB_IstSpannung_DCLS 4094 "Init" 4095 "Fehler" ;
VAL_ 2589283653 HVLB_StatusSpgfreiheit_HV 0 "Init" 1 "HV_Komponente_spannungsfrei" 2 "HV_Komp_nicht_spannungsfrei" 3 "Fehler_nicht_Spannungsfrei" ;
VAL_ 2589283653 HVLB_IstModus 0 "Standby" 1 "Laden_DC_ohne_Boost" 2 "Laden_DC_mit_Boost" 3 "Laden_AC" 5 "Fehler" 6 "Laden_DC_ohneBoost_mitVorladung" 7 "Init" ;
VAL_ 2589283653 HVLB_IstStrom_HVHS 4094 "Init" 4095 "Fehler" ;
VAL_ 2589283653 HVLB_IstSpannung_HVHS 4094 "Init" 4095 "Fehler" ;
VAL_ 2589283653 HVLB_DC_Laden_ohneBoost_verfuegb 0 "nicht_verfuegbar" 1 "verfuegbar" ;
VAL_ 2589283653 HVLB_DC_Laden_mitBoost_verfuegb 0 "nicht_verfuegbar" 1 "verfuegbar" ;
VAL_ 2589283653 HVLB_AC_Laden_verfuegbar 0 "nicht_verfuegbar" 1 "verfuegbar" ;
VAL_ 2589283653 HVLB_Warnzustand 0 "keine_Warnung" 1 "Derating_aktiv" 2 "SollModus_unplausibel" 3 "Spannungsdifferenz_zu_gross" ;
VAL_ 2589283653 HVLB_Fehlerstatus 0 "Komponente_IO" 1 "Eingeschr_KompFkt_IntFehler" 3 "Eingeschr_KompFkt_Interlock" 6 "Keine_Komponentenfunktion" 7 "Init" ;
VAL_ 2463978669 HVLB_Temperatur 254 "Init" 255 "Fehler" ;
VAL_ 2463978669 HVLB_IstSpannung_HVLS 4094 "Init" 4095 "Fehler" ;
VAL_ 2463978669 HVLB_MaxDynStrom_HVLS 4094 "Init" 4095 "Fehler" ;
VAL_ 2589283662 HVLB_PlanAntw_Verlustleistung 4094 "Init" 4095 "Fehler" ;
VAL_ 2589283662 HVLB_PlanAntw_Zaehler 14 "Init" 15 "Fehler" ;
VAL_ 685 DC_MV_IstSpannung_MV 254 "Init" 255 "Fehler" ;
VAL_ 685 DC_MV_IstStrom_MV 1022 "Init" 1023 "Fehler" ;
VAL_ 685 DC_MV_IstStrom_NV 1022 "Init" 1023 "Fehler" ;
VAL_ 685 DC_MV_IstSpannung_NV 254 "Init" 255 "Fehler" ;
VAL_ 1018 DC_MV_akt_Stromreserve_NV 1022 "Init" 1023 "Fehler" ;
VAL_ 1018 DC_MV_MaxStrom_MV 62 "Init" 63 "Fehler" ;
VAL_ 1018 DC_MV_Auslastungsgrad 254 "Init" 255 "Fehler" ;
VAL_ 1484 DCDC_MV_Peakstrom_verfuegbar 0 "Peakstrom_nicht_verfuegbar" 1 "Peakstrom_verfuegbar" ;
VAL_ 1484 DC_MV_Tiefsetzen_Notbetrieb 0 "Init" 1 "aktiv" ;
VAL_ 1484 DC_MV_Fehlerstatus 0 "Komponente_IO" 6 "Keine_Komponentenfunktion" 7 "Init" ;
VAL_ 1484 DC_MV_12V_Bordnetzstuetzung 0 "Init" 1 "aktiv" ;
VAL_ 1484 DC_MV_Abregelung_Temperatur 0 "keine_Abregelung" 1 "Abregelung_Temp" ;
VAL_ 1484 DC_MV_IstModus 0 "Standby" 1 "MV_On" 2 "Tiefsetzen" 3 "Hochsetzen" 4 "Startunterstuetzung_48V" 5 "Fehler" 6 "Startunterstuetzung_12V" 7 "Init" ;
VAL_ 1484 DC_MV_Dyn_MinSpannung 254 "Init" ;
VAL_ 1484 DC_MV_Dyn_MaxSpannung 254 "Init" ;
VAL_ 1484 DC_MV_Temperatur 254 "Init" 255 "Fehler" ;
